VERSION ""

NS_ :

BS_:

BU_: TM

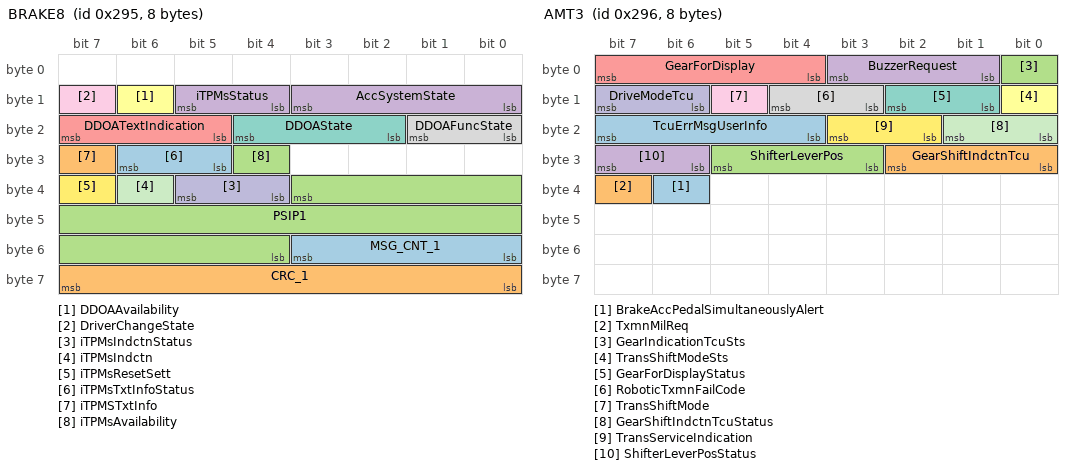
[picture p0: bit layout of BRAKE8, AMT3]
BO_ 661 BRAKE8: 8 Vector__XXX
 SG_ MSG_CNT_1 : 51|4@0+ (1,0) [0|15] ""  TM
 SG_ CRC_1 : 63|8@0+ (1,0) [0|255] ""  TM
 SG_ PSIP1 : 35|16@0+ (0.005,-163.84) [-163.84|163.835] "Deg/Sec"  TM
 SG_ AccSystemState : 11|4@0+ (1,0) [0|15] ""  TM
 SG_ DDOATextIndication : 23|3@0+ (1,0) [0|7] ""  TM
 SG_ DDOAAvailability : 14|1@0+ (1,0) [0|1] ""  TM
 SG_ DDOAState : 20|3@0+ (1,0) [0|7] ""  TM
 SG_ DDOAFuncState : 17|2@0+ (1,0) [0|3] ""  TM
 SG_ DriverChangeState : 15|1@0+ (1,0) [0|1] ""  TM
 SG_ iTPMsIndctnStatus : 37|2@0+ (1,0) [0|3] ""  TM
 SG_ iTPMsIndctn : 38|1@0+ (1,0) [0|1] ""  TM
 SG_ iTPMsResetSett : 39|1@0+ (1,0) [0|1] ""  TM
 SG_ iTPMsTxtInfoStatus : 30|2@0+ (1,0) [0|3] ""  TM
 SG_ iTPMSTxtInfo : 31|1@0+ (1,0) [0|1] ""  TM
 SG_ iTPMsAvailability : 28|1@0+ (1,0) [0|1] ""  TM
 SG_ iTPMsStatus : 13|2@0+ (1,0) [0|3] ""  TM

BO_ 662 AMT3: 8 Vector__XXX
 SG_ BrakeAccPedalSimultaneouslyAlert : 38|1@0+ (1,0) [0|1] ""  TM
 SG_ TxmnMilReq : 39|1@0+ (1,0) [0|1] ""  TM
 SG_ GearIndicationTcuSts : 0|1@0+ (1,0) [0|1] ""  TM
 SG_ BuzzerRequest : 3|3@0+ (1,0) [0|7] ""  TM
 SG_ GearForDisplay : 7|4@0+ (1,0) [0|15] ""  TM
 SG_ TransShiftModeSts : 8|1@0+ (1,0) [0|1] ""  TM
 SG_ GearForDisplayStatus : 10|2@0+ (1,0) [0|3] ""  TM
 SG_ RoboticTxmnFailCode : 12|2@0+ (1,0) [0|3] ""  TM
 SG_ TransShiftMode : 13|1@0+ (1,0) [0|1] ""  TM
 SG_ DriveModeTcu : 15|2@0+ (1,0) [0|3] ""  TM
 SG_ GearShiftIndctnTcuStatus : 17|2@0+ (1,0) [0|3] ""  TM
 SG_ TransServiceIndication : 19|2@0+ (1,0) [0|3] ""  TM
 SG_ TcuErrMsgUserInfo : 23|4@0+ (1,0) [0|15] ""  TM
 SG_ GearShiftIndctnTcu : 26|3@0+ (1,0) [0|7] ""  TM
 SG_ ShifterLeverPos : 29|3@0+ (1,0) [0|7] ""  TM
 SG_ ShifterLeverPosStatus : 31|2@0+ (1,0) [0|3] ""  TM

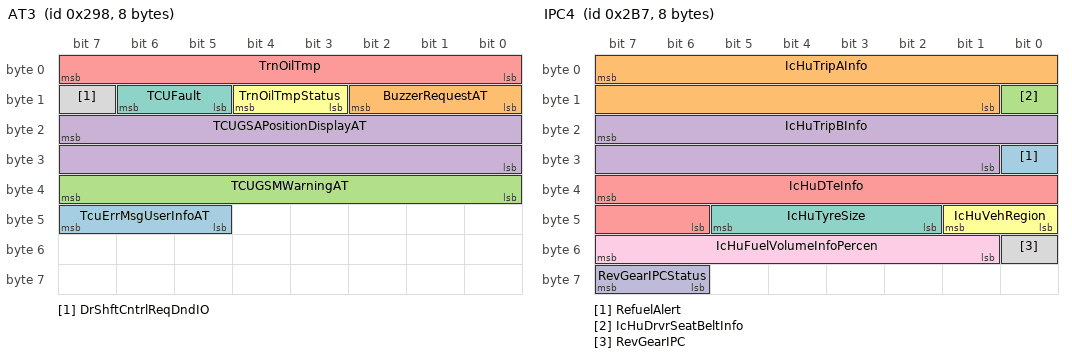
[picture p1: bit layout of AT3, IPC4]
BO_ 664 AT3: 8 Vector__XXX
 SG_ TcuErrMsgUserInfoAT : 47|3@0+ (1,0) [0|7] ""  TM
 SG_ BuzzerRequestAT : 10|3@0+ (1,0) [0|7] ""  TM
 SG_ TCUGSMWarningAT : 39|8@0+ (1,0) [0|255] ""  TM
 SG_ TCUGSAPositionDisplayAT : 23|16@0+ (1,0) [0|65535] ""  TM
 SG_ TrnOilTmp : 7|8@0+ (1,-40) [-40|215] "deg C"  TM
 SG_ TrnOilTmpStatus : 12|2@0+ (1,0) [0|3] ""  TM
 SG_ TCUFault : 14|2@0+ (1,0) [0|3] ""  TM
 SG_ DrShftCntrlReqDndIO : 15|1@0+ (1,0) [0|1] ""  TM

BO_ 666 DCT3: 8 Vector__XXX
 SG_ TCUGSMWarningDct : 63|8@0+ (1,0) [0|255] ""  TM
 SG_ TCUGSAPositionDisplayDct : 47|16@0+ (1,0) [0|65535] ""  TM
 SG_ TcuErrMsgUserInfoDCT : 5|3@0+ (1,0) [0|7] ""  TM
 SG_ DrShftCntrlReqDndIODCT : 26|1@0+ (1,0) [0|1] ""  TM
 SG_ TxmnOilSumpTempStatus : 25|2@0+ (1,0) [0|3] ""  TM
 SG_ TxmnOilSumpTemp : 39|8@0+ (1,-40) [-40|215] "DegC"  TM
 SG_ BuzzerRequestDct : 2|3@0+ (1,0) [0|7] ""  TM
 SG_ TransServiceIndicationDCT : 7|2@0+ (1,0) [0|3] ""  TM
 SG_ CoolingFanStateReq : 8|1@0+ (1,0) [0|1] ""  TM
 SG_ ACCmprsrStateReq : 10|2@0+ (1,0) [0|3] ""  TM
 SG_ GearShiftIndctnTcuDct : 13|3@0+ (1,0) [0|7] ""  TM
 SG_ GearShiftIndctnTcuDctStatus : 15|2@0+ (1,0) [0|3] ""  TM
 SG_ TxmnOverheated : 16|1@0+ (1,0) [0|1] ""  TM
 SG_ InhibitStopStrt : 17|1@0+ (1,0) [0|1] ""  TM
 SG_ GearForDisplayDctStatus : 19|2@0+ (1,0) [0|3] ""  TM
 SG_ GearForDisplayDct : 23|4@0+ (1,0) [0|15] ""  TM
 SG_ BrkPedalPressReq : 27|1@0+ (1,0) [0|1] ""  TM
 SG_ TxmnMilReq : 28|1@0+ (1,0) [0|1] ""  TM
 SG_ EngShutAuth : 29|1@0+ (1,0) [0|1] ""  TM
 SG_ EngStopReqESS : 30|1@0+ (1,0) [0|1] ""  TM
 SG_ EngRestrtReq : 31|1@0+ (1,0) [0|1] ""  TM

BO_ 693 IPC2: 8 Vector__XXX
 SG_ iTPMsResetStatus : 57|2@0+ (1,0) [0|3] ""  TM
 SG_ iTPMsReset : 29|1@0+ (1,0) [0|1] ""  TM
 SG_ HvBattSoCColor : 51|3@0+ (1,0) [0|7] ""  TM
 SG_ OATICSig : 7|8@0+ (0.5,-40) [-40|85] "degC"  TM
 SG_ BattVoltIPC : 15|8@0+ (0.1,0) [0|25.4] "Volts"  TM
 SG_ LowFuelOutputICStatus : 17|2@0+ (1,0) [0|3] ""  TM
 SG_ LowFuelOutputIC : 18|1@0+ (1,0) [0|1] ""  TM
 SG_ ParkBrkState : 19|1@0+ (1,0) [0|1] ""  TM
 SG_ IcPlatformVariant : 23|4@0+ (1,0) [0|15] ""  TM
 SG_ OATICSigStatus : 25|2@0+ (1,0) [0|3] ""  TM
 SG_ IcPresence : 26|1@0+ (1,0) [0|1] ""  TM
 SG_ SRSWarningLampStatus : 27|1@0+ (1,0) [0|1] ""  TM
 SG_ VsSPulseCountSigStatus : 31|2@0+ (1,0) [0|3] ""  TM
 SG_ VsSPulseCountSig : 39|8@0+ (1,0) [0|255] "Pulse"  TM
 SG_ IcHuVoiceAlertState : 47|8@0+ (1,0) [0|255] ""  TM
 SG_ IcHuVoiceAlertStateStatus : 48|1@0+ (1,0) [0|1] ""  TM
 SG_ ICCurDriveModeSig : 55|4@0+ (1,0) [0|15] ""  TM
 SG_ IcHuCarImageSelection : 61|4@0+ (1,0) [0|15] ""  TM
 SG_ IcSbDispReq : 62|1@0+ (1,0) [0|1] ""  TM
 SG_ IcSbrDrvrSeatBeltSwitchStatus : 63|1@0+ (1,0) [0|1] ""  TM

BO_ 695 IPC4: 8 Vector__XXX
 SG_ RefuelAlert : 24|1@0+ (1,0) [0|1] ""  TM
 SG_ IcHuTripAInfo : 7|15@0+ (0.1,0) [0|1999] "Km"  TM
 SG_ IcHuDrvrSeatBeltInfo : 8|1@0+ (1,0) [0|1] ""  TM
 SG_ IcHuTripBInfo : 23|15@0+ (0.1,0) [0|1999] "Km"  TM
 SG_ IcHuDTeInfo : 39|10@0+ (1,0) [0|999] ""  TM
 SG_ IcHuVehRegion : 41|2@0+ (1,0) [0|3] ""  TM
 SG_ IcHuTyreSize : 45|4@0+ (1,0) [0|15] ""  TM
 SG_ RevGearIPC : 48|1@0+ (1,0) [0|1] ""  TM
 SG_ IcHuFuelVolumeInfoPercen : 55|7@0+ (1,0) [0|100] "%"  TM
 SG_ RevGearIPCStatus : 63|2@0+ (1,0) [0|3] ""  TM

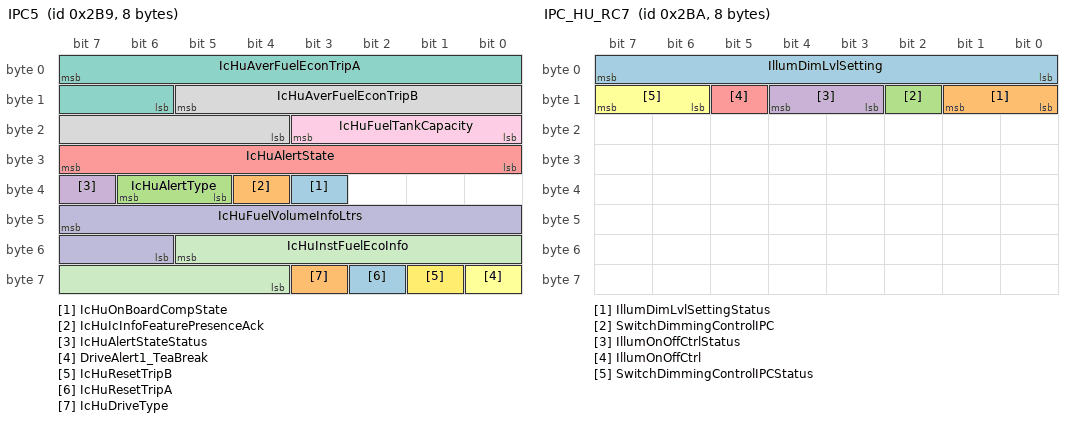
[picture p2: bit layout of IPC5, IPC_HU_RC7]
BO_ 697 IPC5: 8 Vector__XXX
 SG_ IcHuOnBoardCompState : 35|1@0+ (1,0) [0|1] ""  TM
 SG_ IcHuIcInfoFeaturePresenceAck : 36|1@0+ (1,0) [0|1] ""  TM
 SG_ IcHuAlertType : 38|2@0+ (1,0) [0|3] ""  TM
 SG_ IcHuAlertStateStatus : 39|1@0+ (1,0) [0|1] ""  TM
 SG_ IcHuAlertState : 31|8@0+ (1,0) [0|127] ""  TM
 SG_ DriveAlert1_TeaBreak : 56|1@0+ (1,0) [0|1] ""  TM
 SG_ IcHuAverFuelEconTripA : 7|10@0+ (0.1,0) [0|99.9] "Km/Ltr"  TM
 SG_ IcHuAverFuelEconTripB : 13|10@0+ (0.1,0) [0|99.9] "Km/Ltr"  TM
 SG_ IcHuFuelTankCapacity : 19|4@0+ (1,0) [0|15] ""  TM
 SG_ IcHuFuelVolumeInfoLtrs : 47|10@0+ (0.1,0) [0|65] "Ltr"  TM
 SG_ IcHuInstFuelEcoInfo : 53|10@0+ (0.1,0) [0|99.9] "Km/Ltr"  TM
 SG_ IcHuResetTripB : 57|1@0+ (1,0) [0|1] ""  TM
 SG_ IcHuResetTripA : 58|1@0+ (1,0) [0|1] ""  TM
 SG_ IcHuDriveType : 59|1@0+ (1,0) [0|1] ""  TM

BO_ 698 IPC_HU_RC7: 8 Vector__XXX
 SG_ IllumDimLvlSetting : 7|8@0+ (1,0) [0|100] "%"  TM
 SG_ IllumDimLvlSettingStatus : 9|2@0+ (1,0) [0|3] ""  TM
 SG_ SwitchDimmingControlIPC : 10|1@0+ (1,0) [0|1] ""  TM
 SG_ IllumOnOffCtrlStatus : 12|2@0+ (1,0) [0|3] ""  TM
 SG_ IllumOnOffCtrl : 13|1@0+ (1,0) [0|1] ""  TM
 SG_ SwitchDimmingControlIPCStatus : 15|2@0+ (1,0) [0|3] ""  TM

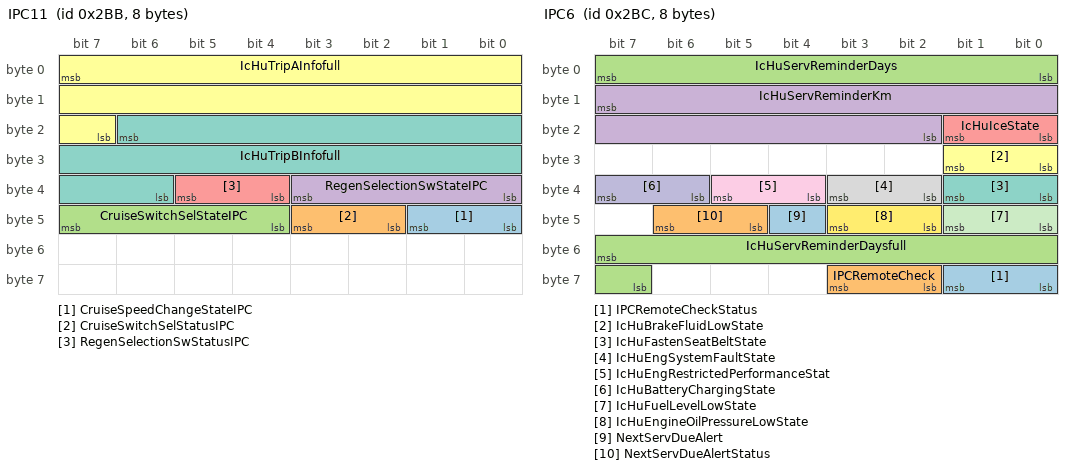
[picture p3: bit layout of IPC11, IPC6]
BO_ 699 IPC11: 8 Vector__XXX
 SG_ CruiseSpeedChangeStateIPC : 41|2@0+ (1,0) [0|3] ""  TM
 SG_ CruiseSwitchSelStatusIPC : 43|2@0+ (1,0) [0|3] ""  TM
 SG_ CruiseSwitchSelStateIPC : 47|4@0+ (1,0) [0|15] ""  TM
 SG_ RegenSelectionSwStateIPC : 35|4@0+ (1,0) [0|15] ""  TM
 SG_ RegenSelectionSwStatusIPC : 37|2@0+ (1,0) [0|3] ""  TM
 SG_ IcHuTripAInfofull : 7|17@0+ (0.1,0) [0|9999.9] "Km"  TM
 SG_ IcHuTripBInfofull : 22|17@0+ (0.1,0) [0|9999.9] "Km"  TM

BO_ 700 IPC6: 8 Vector__XXX
 SG_ IPCRemoteCheckStatus : 57|2@0+ (1,0) [0|3] ""  TM
 SG_ IPCRemoteCheck : 59|2@0+ (1,0) [0|3] ""  TM
 SG_ IcHuServReminderDays : 7|8@0+ (1,0) [0|255] "Day"  TM
 SG_ IcHuServReminderKm : 15|14@0+ (1,0) [0|16383] "Km"  TM
 SG_ IcHuIceState : 17|2@0+ (1,0) [0|3] ""  TM
 SG_ IcHuBrakeFluidLowState : 25|2@0+ (1,0) [0|3] ""  TM
 SG_ IcHuFastenSeatBeltState : 33|2@0+ (1,0) [0|3] ""  TM
 SG_ IcHuEngSystemFaultState : 35|2@0+ (1,0) [0|3] ""  TM
 SG_ IcHuEngRestrictedPerformanceStat : 37|2@0+ (1,0) [0|3] ""  TM
 SG_ IcHuBatteryChargingState : 39|2@0+ (1,0) [0|3] ""  TM
 SG_ IcHuFuelLevelLowState : 41|2@0+ (1,0) [0|3] ""  TM
 SG_ IcHuEngineOilPressureLowState : 43|2@0+ (1,0) [0|3] ""  TM
 SG_ NextServDueAlert : 44|1@0+ (1,0) [0|1] ""  TM
 SG_ NextServDueAlertStatus : 46|2@0+ (1,0) [0|3] ""  TM
 SG_ IcHuServReminderDaysfull : 55|9@0+ (1,0) [0|511] "Day"  TM

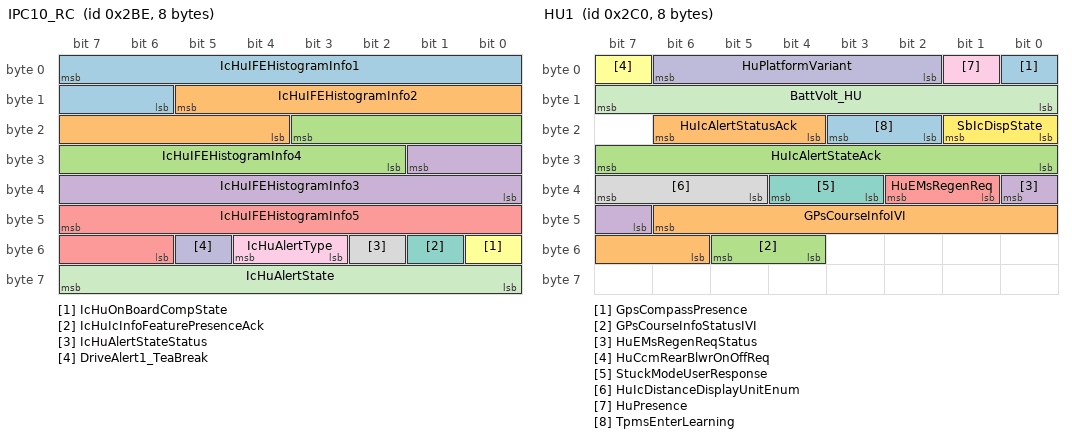
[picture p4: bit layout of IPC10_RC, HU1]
BO_ 702 IPC10_RC: 8 Vector__XXX
 SG_ IcHuIFEHistogramInfo1 : 7|10@0+ (0.1,0) [0|99.9] "Km/Ltr"  TM
 SG_ IcHuIFEHistogramInfo2 : 13|10@0+ (0.1,0) [0|99.9] "km/Ltr"  TM
 SG_ IcHuIFEHistogramInfo4 : 19|10@0+ (0.1,0) [0|99.9] "Km/Ltr"  TM
 SG_ IcHuIFEHistogramInfo3 : 25|10@0+ (0.1,0) [0|99.9] "Km/Ltr"  TM
 SG_ IcHuIFEHistogramInfo5 : 47|10@0+ (0.1,0) [0|99.9] "Km/Ltr"  TM
 SG_ IcHuOnBoardCompState : 48|1@0+ (1,0) [0|1] ""  TM
 SG_ IcHuIcInfoFeaturePresenceAck : 49|1@0+ (1,0) [0|1] ""  TM
 SG_ IcHuAlertStateStatus : 50|1@0+ (1,0) [0|1] ""  TM
 SG_ IcHuAlertType : 52|2@0+ (1,0) [0|3] ""  TM
 SG_ DriveAlert1_TeaBreak : 53|1@0+ (1,0) [0|1] ""  TM
 SG_ IcHuAlertState : 63|8@0+ (1,0) [0|127] ""  TM

BO_ 704 HU1: 8 Vector__XXX
 SG_ GpsCompassPresence : 0|1@0+ (1,0) [0|1] ""  TM
 SG_ GPsCourseInfoIVI : 46|9@0+ (1,0) [0|360] ""  TM
 SG_ GPsCourseInfoStatusIVI : 53|2@0+ (1,0) [0|3] ""  TM
 SG_ HuEMsRegenReqStatus : 32|2@0+ (1,0) [0|3] ""  TM
 SG_ HuEMsRegenReq : 34|2@0+ (1,0) [0|3] ""  TM
 SG_ HuCcmRearBlwrOnOffReq : 7|1@0+ (1,0) [0|1] ""  TM
 SG_ StuckModeUserResponse : 36|2@0+ (1,0) [0|3] ""  TM
 SG_ HuIcDistanceDisplayUnitEnum : 39|3@0+ (1,0) [0|7] ""  TM
 SG_ HuPresence : 1|1@0+ (1,0) [0|1] ""  TM
 SG_ HuPlatformVariant : 6|5@0+ (1,0) [0|31] ""  TM
 SG_ BattVolt_HU : 15|8@0+ (0.1,0) [0|25] "Volts"  TM
 SG_ SbIcDispState : 17|2@0+ (1,0) [0|3] ""  TM
 SG_ TpmsEnterLearning : 19|2@0+ (1,0) [0|3] ""  TM
 SG_ HuIcAlertStatusAck : 22|3@0+ (1,0) [0|7] ""  TM
 SG_ HuIcAlertStateAck : 31|8@0+ (1,0) [0|127] ""  TM

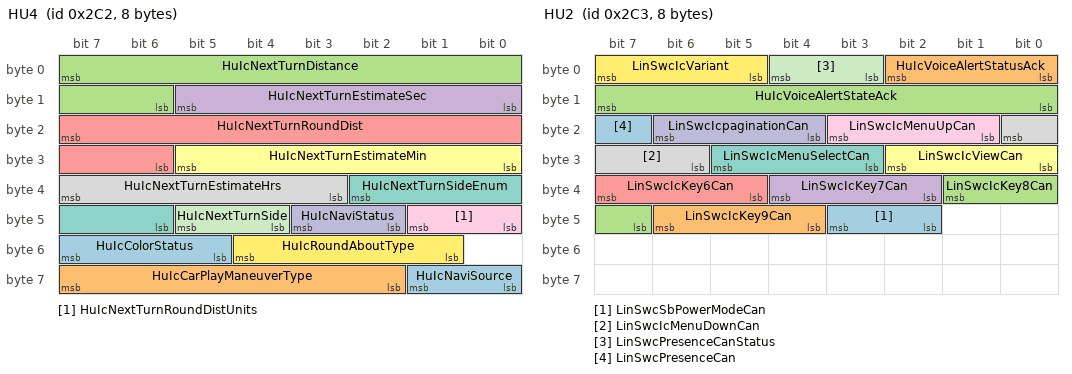
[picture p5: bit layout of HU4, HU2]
BO_ 706 HU4: 8 Vector__XXX
 SG_ HuIcNaviSource : 57|2@0+ (1,0) [0|3] ""  TM
 SG_ HuIcCarPlayManeuverType : 63|6@0+ (1,0) [0|63] ""  TM
 SG_ HuIcNextTurnDistance : 7|10@0+ (1,0) [0|1023] "m"  TM
 SG_ HuIcNextTurnEstimateSec : 13|6@0+ (1,0) [0|59] "sec"  TM
 SG_ HuIcNextTurnRoundDist : 23|10@0+ (1,0) [0|1023] "m"  TM
 SG_ HuIcNextTurnEstimateMin : 29|6@0+ (1,0) [0|59] "min"  TM
 SG_ HuIcNextTurnSideEnum : 34|5@0+ (1,0) [0|31] ""  TM
 SG_ HuIcNextTurnEstimateHrs : 39|5@0+ (1,0) [0|23] "hr"  TM
 SG_ HuIcNextTurnRoundDistUnits : 41|2@0+ (1,0) [0|3] ""  TM
 SG_ HuIcNaviStatus : 43|2@0+ (1,0) [0|3] ""  TM
 SG_ HuIcNextTurnSide : 45|2@0+ (1,0) [0|3] ""  TM
 SG_ HuIcRoundAboutType : 52|4@0+ (1,0) [0|15] ""  TM
 SG_ HuIcColorStatus : 55|3@0+ (1,0) [0|7] ""  TM

BO_ 707 HU2: 8 Vector__XXX
 SG_ LinSwcSbPowerModeCan : 43|2@0+ (1,0) [0|3] ""  TM
 SG_ LinSwcIcKey9Can : 46|3@0+ (1,0) [0|7] ""  TM
 SG_ LinSwcIcKey8Can : 33|3@0+ (1,0) [0|7] ""  TM
 SG_ LinSwcIcKey7Can : 36|3@0+ (1,0) [0|7] ""  TM
 SG_ LinSwcIcKey6Can : 39|3@0+ (1,0) [0|7] ""  TM
 SG_ LinSwcIcViewCan : 26|3@0+ (1,0) [0|7] ""  TM
 SG_ LinSwcIcMenuSelectCan : 29|3@0+ (1,0) [0|7] ""  TM
 SG_ LinSwcIcMenuDownCan : 16|3@0+ (1,0) [0|7] ""  TM
 SG_ LinSwcIcMenuUpCan : 19|3@0+ (1,0) [0|7] ""  TM
 SG_ LinSwcIcpaginationCan : 22|3@0+ (1,0) [0|7] ""  TM
 SG_ LinSwcPresenceCanStatus : 4|2@0+ (1,0) [0|3] ""  TM
 SG_ LinSwcIcVariant : 7|3@0+ (1,0) [0|7] ""  TM
 SG_ LinSwcPresenceCan : 23|1@0+ (1,0) [0|1] ""  TM
 SG_ HuIcVoiceAlertStatusAck : 2|3@0+ (1,0) [0|7] ""  TM
 SG_ HuIcVoiceAlertStateAck : 15|8@0+ (1,0) [0|255] ""  TM

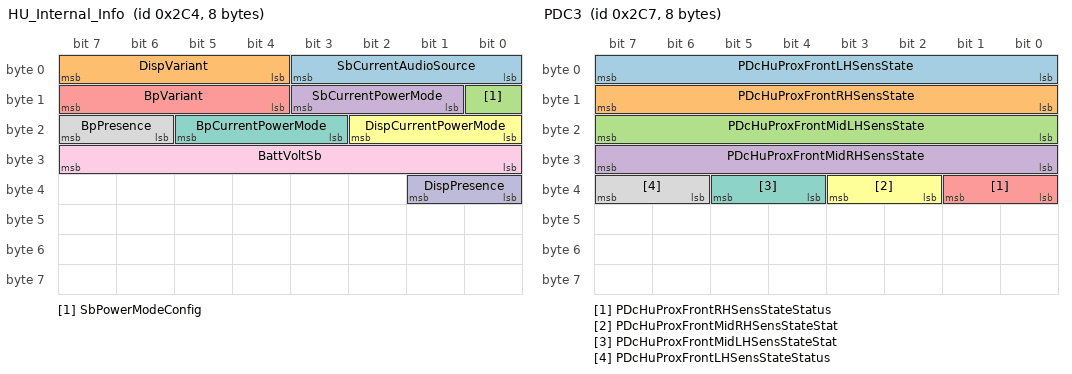
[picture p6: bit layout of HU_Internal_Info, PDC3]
BO_ 708 HU_Internal_Info: 8 Vector__XXX
 SG_ SbCurrentAudioSource : 3|4@0+ (1,0) [0|15] ""  TM
 SG_ DispVariant : 7|4@0+ (1,0) [0|15] ""  TM
 SG_ SbPowerModeConfig : 8|1@0+ (1,0) [0|1] ""  TM
 SG_ SbCurrentPowerMode : 11|3@0+ (1,0) [0|7] ""  TM
 SG_ BpVariant : 15|4@0+ (1,0) [0|15] ""  TM
 SG_ DispCurrentPowerMode : 18|3@0+ (1,0) [0|7] ""  TM
 SG_ BpCurrentPowerMode : 21|3@0+ (1,0) [0|7] ""  TM
 SG_ BpPresence : 23|2@0+ (1,0) [0|3] ""  TM
 SG_ BattVoltSb : 31|8@0+ (0.1,0) [0|25.4] "V"  TM
 SG_ DispPresence : 33|2@0+ (1,0) [0|3] ""  TM

BO_ 710 PDC1: 8 Vector__XXX
 SG_ PDcHuFaultState : 4|5@0+ (1,0) [0|31] ""  TM
 SG_ PDcHuAudioZoneState : 7|3@0+ (1,0) [0|7] ""  TM
 SG_ PDcHuVisualZoneRearLHSensState : 11|4@0+ (1,0) [0|15] ""  TM
 SG_ PDcHuVisualZoneRearMidRHSensStat : 15|4@0+ (1,0) [0|15] ""  TM
 SG_ PDcHuVisualZoneRearRHSensState : 19|4@0+ (1,0) [0|15] ""  TM
 SG_ PDcHuVisualZoneRearMidLHSensStat : 23|4@0+ (1,0) [0|15] ""  TM
 SG_ PDcPresence : 24|1@0+ (1,0) [0|1] ""  TM
 SG_ PDcHuState : 25|1@0+ (1,0) [0|1] ""  TM
 SG_ PDcHuPwrModeState : 29|4@0+ (1,0) [0|15] ""  TM
 SG_ PDcVariant : 31|2@0+ (1,0) [0|3] ""  TM
 SG_ PDcHuVisualZoneFrontLHSensState : 35|4@0+ (1,0) [0|15] ""  TM
 SG_ PDcHuVisualZoneFrontMidLHSensSta : 39|4@0+ (1,0) [0|15] ""  TM
 SG_ PDcHuVisualZoneFrontMidRHSensSta : 43|4@0+ (1,0) [0|15] ""  TM
 SG_ PDcHuVisualZoneFrontRHSensState : 47|4@0+ (1,0) [0|15] ""  TM
 SG_ PDcHuFrontAudioZoneState : 50|3@0+ (1,0) [0|7] ""  TM
 SG_ PDcHuFrontFaultState : 55|5@0+ (1,0) [0|31] ""  TM
 SG_ PDcHuFrontState : 56|1@0+ (1,0) [0|1] ""  TM
 SG_ PDcIPcFrontActive : 59|1@0+ (1,0) [0|1] ""  TM
 SG_ PDcIPcRearActive : 60|1@0+ (1,0) [0|1] ""  TM

BO_ 711 PDC3: 8 Vector__XXX
 SG_ PDcHuProxFrontLHSensState : 7|8@0+ (1,0) [0|255] "cms"  TM
 SG_ PDcHuProxFrontRHSensState : 15|8@0+ (1,0) [0|255] "cms"  TM
 SG_ PDcHuProxFrontMidLHSensState : 23|8@0+ (1,0) [0|255] "cms"  TM
 SG_ PDcHuProxFrontMidRHSensState : 31|8@0+ (1,0) [0|255] "cm"  TM
 SG_ PDcHuProxFrontRHSensStateStatus : 33|2@0+ (1,0) [0|3] ""  TM
 SG_ PDcHuProxFrontMidRHSensStateStat : 35|2@0+ (1,0) [0|3] ""  TM
 SG_ PDcHuProxFrontMidLHSensStateStat : 37|2@0+ (1,0) [0|3] ""  TM
 SG_ PDcHuProxFrontLHSensStateStatus : 39|2@0+ (1,0) [0|3] ""  TM

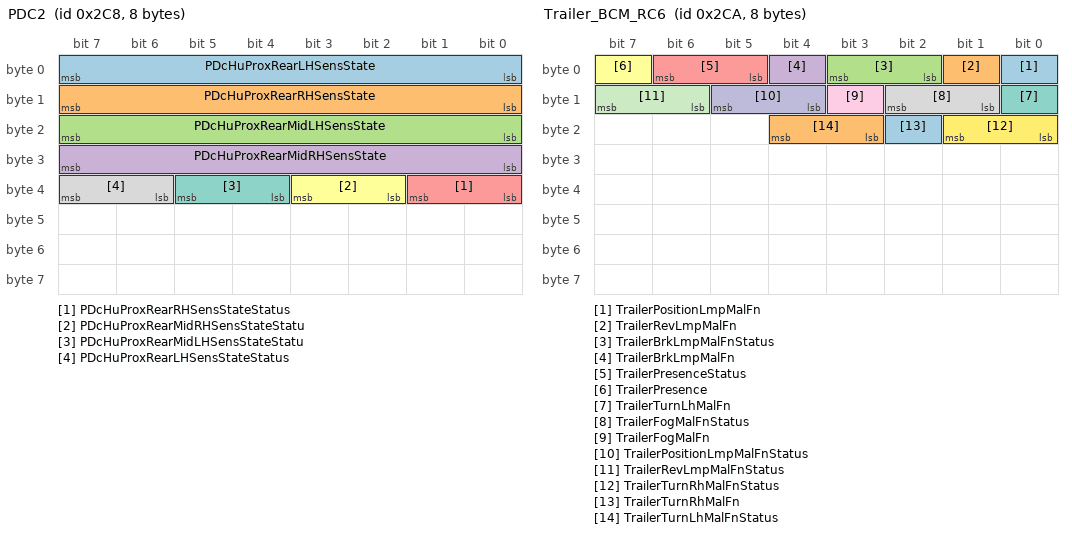
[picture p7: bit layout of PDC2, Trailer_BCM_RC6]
BO_ 712 PDC2: 8 Vector__XXX
 SG_ PDcHuProxRearLHSensState : 7|8@0+ (1,0) [0|255] "cms"  TM
 SG_ PDcHuProxRearRHSensState : 15|8@0+ (1,0) [0|255] "cms"  TM
 SG_ PDcHuProxRearMidLHSensState : 23|8@0+ (1,0) [0|255] "cms"  TM
 SG_ PDcHuProxRearMidRHSensState : 31|8@0+ (1,0) [0|255] "cm"  TM
 SG_ PDcHuProxRearRHSensStateStatus : 33|2@0+ (1,0) [0|3] ""  TM
 SG_ PDcHuProxRearMidRHSensStateStatu : 35|2@0+ (1,0) [0|3] ""  TM
 SG_ PDcHuProxRearMidLHSensStateStatu : 37|2@0+ (1,0) [0|3] ""  TM
 SG_ PDcHuProxRearLHSensStateStatus : 39|2@0+ (1,0) [0|3] ""  TM

BO_ 713 HU5: 8 Vector__XXX
 SG_ HuIcMediaState : 59|4@0+ (1,0) [0|15] ""  TM
 SG_ HuIcSource : 48|5@0+ (1,0) [0|31] ""  TM
 SG_ HuIcAudioVolumeStatus : 12|5@0+ (1,0) [0|31] ""  TM
 SG_ HuIcBTStatus : 15|3@0+ (1,0) [0|7] ""  TM
 SG_ HuIcPlabackCallDurationSec : 21|6@0+ (1,0) [0|59] "sec."  TM
 SG_ HuIcRepeatOneState : 22|1@0+ (1,0) [0|1] ""  TM
 SG_ HuIcMuteStatus : 23|1@0+ (1,0) [0|1] ""  TM
 SG_ HuIcPlabackCallDurationMin : 29|6@0+ (1,0) [0|59] "min"  TM
 SG_ HuIcSMSReceiveState : 30|1@0+ (1,0) [0|1] ""  TM
 SG_ HuIcRepeatState : 31|1@0+ (1,0) [0|1] ""  TM
 SG_ HuIcPlabackCallDurationHrs : 36|5@0+ (1,0) [0|23] "hr"  TM
 SG_ HuIcPhoneCallStatus : 39|3@0+ (1,0) [0|7] ""  TM
 SG_ HuIcPlaybackElapsedTimeHrs : 44|5@0+ (1,0) [0|23] "hr"  TM
 SG_ HuIcNetworkSignalStatus : 47|3@0+ (1,0) [0|7] ""  TM
 SG_ HuIcPlaybackElapsedTimeMin : 55|6@0+ (1,0) [0|59] "min"  TM
 SG_ HuIcInfoFeaturePresence : 0|1@0+ (1,0) [0|1] ""  TM
 SG_ HuIcShuffleState : 1|1@0+ (1,0) [0|1] ""  TM
 SG_ HuIcPlaybackElapsedTimeSec : 7|6@0+ (1,0) [0|59] "sec"  TM

BO_ 714 Trailer_BCM_RC6: 8 Vector__XXX
 SG_ TrailerPositionLmpMalFn : 0|1@0+ (1,0) [0|1] ""  TM
 SG_ TrailerRevLmpMalFn : 1|1@0+ (1,0) [0|1] ""  TM
 SG_ TrailerBrkLmpMalFnStatus : 3|2@0+ (1,0) [0|3] ""  TM
 SG_ TrailerBrkLmpMalFn : 4|1@0+ (1,0) [0|1] ""  TM
 SG_ TrailerPresenceStatus : 6|2@0+ (1,0) [0|3] ""  TM
 SG_ TrailerPresence : 7|1@0+ (1,0) [0|1] ""  TM
 SG_ TrailerTurnLhMalFn : 8|1@0+ (1,0) [0|1] ""  TM
 SG_ TrailerFogMalFnStatus : 10|2@0+ (1,0) [0|3] ""  TM
 SG_ TrailerFogMalFn : 11|1@0+ (1,0) [0|1] ""  TM
 SG_ TrailerPositionLmpMalFnStatus : 13|2@0+ (1,0) [0|3] ""  TM
 SG_ TrailerRevLmpMalFnStatus : 15|2@0+ (1,0) [0|3] ""  TM
 SG_ TrailerTurnRhMalFnStatus : 17|2@0+ (1,0) [0|3] ""  TM
 SG_ TrailerTurnRhMalFn : 18|1@0+ (1,0) [0|1] ""  TM
 SG_ TrailerTurnLhMalFnStatus : 20|2@0+ (1,0) [0|3] ""  TM

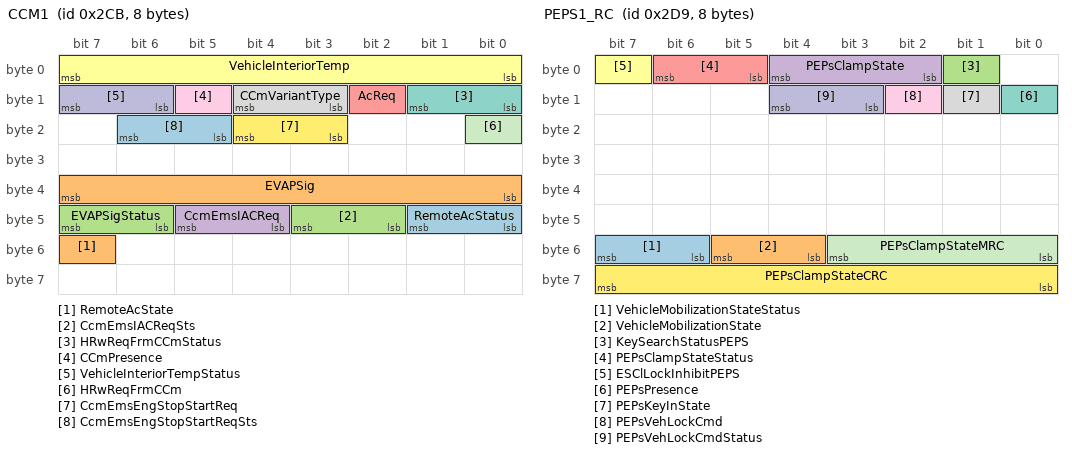
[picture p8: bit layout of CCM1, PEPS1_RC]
BO_ 715 CCM1: 8 Vector__XXX
 SG_ RemoteAcStatus : 41|2@0+ (1,0) [0|3] ""  TM
 SG_ RemoteAcState : 55|1@0+ (1,0) [0|1] ""  TM
 SG_ CcmEmsIACReqSts : 43|2@0+ (1,0) [0|3] ""  TM
 SG_ CcmEmsIACReq : 45|2@0+ (1,0) [0|3] ""  TM
 SG_ AcReq : 10|1@0+ (1,0) [0|1] ""  TM
 SG_ VehicleInteriorTemp : 7|8@0+ (0.5,-40) [-40|85] "Deg"  TM
 SG_ HRwReqFrmCCmStatus : 9|2@0+ (1,0) [0|3] ""  TM
 SG_ CCmVariantType : 12|2@0+ (1,0) [0|3] ""  TM
 SG_ CCmPresence : 13|1@0+ (1,0) [0|1] ""  TM
 SG_ VehicleInteriorTempStatus : 15|2@0+ (1,0) [0|3] ""  TM
 SG_ HRwReqFrmCCm : 16|1@0+ (1,0) [0|1] ""  TM
 SG_ CcmEmsEngStopStartReq : 20|2@0+ (1,0) [0|3] ""  TM
 SG_ CcmEmsEngStopStartReqSts : 22|2@0+ (1,0) [0|3] ""  TM
 SG_ EVAPSig : 39|8@0+ (0.5,-40) [-40|85] "DegC"  TM
 SG_ EVAPSigStatus : 47|2@0+ (1,0) [0|3] ""  TM

BO_ 720 BCM1: 8 Vector__XXX
 SG_ RearWasherStateStatus : 63|2@0+ (1,0) [0|3] ""  TM
 SG_ RearWasherState : 61|2@0+ (1,0) [0|3] ""  TM
 SG_ FrontWasherStateStatus : 59|2@0+ (1,0) [0|3] ""  TM
 SG_ FrontWasherState : 57|2@0+ (1,0) [0|3] ""  TM
 SG_ AutoWipeStateStatus : 35|2@0+ (1,0) [0|3] ""  TM
 SG_ AutoWipeState : 33|2@0+ (1,0) [0|3] ""  TM
 SG_ PositionLmpTelltale : 25|1@0+ (1,0) [0|1] ""  TM
 SG_ PositionLmpTelltaleStatus : 39|2@0+ (1,0) [0|3] ""  TM
 SG_ BattVolt_BCM : 7|8@0+ (0.1,0) [0|25] "Volts"  TM
 SG_ BCMVariant : 10|3@0+ (1,0) [0|7] ""  TM
 SG_ BCMPresence : 11|1@0+ (1,0) [0|1] ""  TM
 SG_ RevGearStatus : 13|2@0+ (1,0) [0|3] ""  TM
 SG_ RevGear : 14|1@0+ (1,0) [0|1] ""  TM
 SG_ RevLmpON : 15|1@0+ (1,0) [0|1] ""  TM
 SG_ RevLmpONStatus : 17|2@0+ (1,0) [0|3] ""  TM
 SG_ RearFogLmpON : 18|1@0+ (1,0) [0|1] ""  TM
 SG_ RearFogLmpONStatus : 20|2@0+ (1,0) [0|3] ""  TM
 SG_ TurnLHTelltaleStatus : 22|2@0+ (1,0) [0|3] ""  TM
 SG_ TurnLHTelltale : 23|1@0+ (1,0) [0|1] ""  TM
 SG_ TurnRHTelltaleStatus : 27|2@0+ (1,0) [0|3] ""  TM
 SG_ TurnRHTelltale : 28|1@0+ (1,0) [0|1] ""  TM
 SG_ LightSensActiveStatus : 30|2@0+ (1,0) [0|3] ""  TM
 SG_ LightSensActive : 31|1@0+ (1,0) [0|1] ""  TM
 SG_ RVcPresence : 37|2@0+ (1,0) [0|3] ""  TM
 SG_ BcmCcmSolarInputLh : 47|8@0+ (5,0) [0|1200] "W/m^2"  TM
 SG_ BcmCcmSolarInputRh : 55|8@0+ (5,0) [0|1200] "W/m^2"  TM

BO_ 722 BCM_HUICTrailer_RC1: 8 Vector__XXX
 SG_ PowerModeStateStatus : 1|2@0+ (1,0) [0|3] ""  TM
 SG_ PowerModeState : 5|4@0+ (1,0) [0|15] ""  TM
 SG_ PositionLmpTelltaleStatus : 7|2@0+ (1,0) [0|3] ""  TM
 SG_ PositionLmpTelltale : 8|1@0+ (1,0) [0|1] ""  TM
 SG_ HRwFdBkFrmBCm : 9|1@0+ (1,0) [0|1] ""  TM
 SG_ HRwFdBkFrmBCmStatus : 11|2@0+ (1,0) [0|3] ""  TM
 SG_ TurnRHTelltale : 12|1@0+ (1,0) [0|1] ""  TM
 SG_ TurnLHTelltaleStatus : 14|2@0+ (1,0) [0|3] ""  TM
 SG_ TurnLHTelltale : 15|1@0+ (1,0) [0|1] ""  TM
 SG_ TurnRHTelltaleStatus : 17|2@0+ (1,0) [0|3] ""  TM
 SG_ BattSaverFnONStatus : 19|2@0+ (1,0) [0|3] ""  TM
 SG_ BattSaverFnON : 20|1@0+ (1,0) [0|1] ""  TM
 SG_ BrkLmpONStatus : 22|2@0+ (1,0) [0|3] ""  TM
 SG_ BrkLmpON : 23|1@0+ (1,0) [0|1] ""  TM
 SG_ CockpitSigECuStatus : 25|2@0+ (1,0) [0|3] ""  TM
 SG_ RearRHTurnLmpON : 26|1@0+ (1,0) [0|1] ""  TM
 SG_ RearRHTurnLmpONStatus : 28|2@0+ (1,0) [0|3] ""  TM
 SG_ RearLHTurnLmpONStatus : 30|2@0+ (1,0) [0|3] ""  TM
 SG_ RearLHTurnLmpON : 31|1@0+ (1,0) [0|1] ""  TM
 SG_ CockpitSigECu : 39|8@0+ (1,0) [0|100] "%"  TM
 SG_ VehicleLockStateStatus : 41|2@0+ (1,0) [0|3] ""  TM
 SG_ HighBeamTelltaleStatus : 43|2@0+ (1,0) [0|3] ""  TM
 SG_ HighBeamTelltale : 44|1@0+ (1,0) [0|1] ""  TM
 SG_ KeyInStateStatus : 46|2@0+ (1,0) [0|3] ""  TM
 SG_ KeyInState : 47|1@0+ (1,0) [0|1] ""  TM
 SG_ PowerModeStateMsgCnt : 51|4@0+ (1,0) [0|15] ""  TM
 SG_ VehicleLockState : 55|3@0+ (1,0) [0|7] ""  TM
 SG_ PowerModeStateCRC : 63|8@0+ (1,0) [0|255] ""  TM

BO_ 729 PEPS1_RC: 8 Vector__XXX
 SG_ VehicleMobilizationStateStatus : 55|2@0+ (1,0) [0|3] ""  TM
 SG_ VehicleMobilizationState : 53|2@0+ (1,0) [0|3] ""  TM
 SG_ KeySearchStatusPEPS : 1|1@0+ (1,0) [0|1] ""  TM
 SG_ PEPsClampState : 4|3@0+ (1,0) [0|7] ""  TM
 SG_ PEPsClampStateStatus : 6|2@0+ (1,0) [0|3] ""  TM
 SG_ ESClLockInhibitPEPS : 7|1@0+ (1,0) [0|1] ""  TM
 SG_ PEPsPresence : 8|1@0+ (1,0) [0|1] ""  TM
 SG_ PEPsKeyInState : 9|1@0+ (1,0) [0|1] ""  TM
 SG_ PEPsVehLockCmd : 10|1@0+ (1,0) [0|1] ""  TM
 SG_ PEPsVehLockCmdStatus : 12|2@0+ (1,0) [0|3] ""  TM
 SG_ PEPsClampStateMRC : 51|4@0+ (1,0) [0|15] ""  TM
 SG_ PEPsClampStateCRC : 63|8@0+ (1,0) [0|255] ""  TM

CM_ SG_ 661 MSG_CNT_1 "Messgage counter for AY & Yaw signals";
CM_ SG_ 661 CRC_1 "CRC signal for AY & Yaw signals";
CM_ SG_ 661 PSIP1 "This data indicates information regarding digital filtered Yaw rate signal.";
CM_ SG_ 661 AccSystemState "It indicates the status of AccEngaged signal";
CM_ SG_ 661 DDOATextIndication " Driver Drowsiness State for IPC Text Message ";
CM_ SG_ 661 DDOAAvailability "DDOA function availability in the vehicle";
CM_ SG_ 661 DDOAState "Signal indicates driver Drowsiness State";
CM_ SG_ 661 DDOAFuncState "Functional State of DDOA";
CM_ SG_ 661 DriverChangeState "It indicates driver change is required";
CM_ SG_ 661 iTPMsIndctnStatus "Status signal of iTPMSIndctn";
CM_ SG_ 661 iTPMsIndctn "Low/ Ok tyre pressure indication";
CM_ SG_ 661 iTPMsResetSett "iTPMS reset setting to IPC";
CM_ SG_ 661 iTPMsTxtInfoStatus "Staus signal for iTPMSTxtInfo";
CM_ SG_ 661 iTPMSTxtInfo "iTPMS text message for user information";
CM_ SG_ 661 iTPMsAvailability "status information of TPMS";
CM_ SG_ 661 iTPMsStatus "status information of TPMS";
CM_ SG_ 662 BrakeAccPedalSimultaneouslyAlert "Brake and acc pedal pressed simultaneously.";
CM_ SG_ 662 TxmnMilReq "transmission OBD related malfunction indication to the driver";
CM_ SG_ 662 GearIndicationTcuSts "In case of any problem, gear number wll blink otherwise it will be normal";
CM_ SG_ 662 BuzzerRequest "Indication for buzzer request";
CM_ SG_ 662 GearForDisplay "This is the current position of the gear shift lever";
CM_ SG_ 662 TransShiftModeSts "In case of Inadvertent GSL movement, Transmission mode willl blink otherwise it will be normal";
CM_ SG_ 662 GearForDisplayStatus "This is the current position of the gear shift lever,Status info";
CM_ SG_ 662 RoboticTxmnFailCode "In case of vehcile interface or Gear box shifting failure, corresponding fault will be set.";
CM_ SG_ 662 TransShiftMode "Indication for the gear shift program";
CM_ SG_ 662 DriveModeTcu "Indicated the mode selected for IC";
CM_ SG_ 662 GearShiftIndctnTcuStatus "Gear shift Indication staus used to indicate the gear status signal";
CM_ SG_ 662 TransServiceIndication "Indication for AMT system warning lamp";
CM_ SG_ 662 TcuErrMsgUserInfo "ErrorMessages&UserInformation  ";
CM_ SG_ 662 GearShiftIndctnTcu "Gear shift Indication used to indicate the required gear status in IC  required Gear by the driver is to Improve the drive habits of driver 








";
CM_ SG_ 662 ShifterLeverPos "Gear Shift Lever position";
CM_ SG_ 662 ShifterLeverPosStatus "Gear Shift Lever position status information";
CM_ SG_ 664 TcuErrMsgUserInfoAT "ErrorMessages&UserInformation";
CM_ SG_ 664 BuzzerRequestAT "Indication for buzzer request";
CM_ SG_ 664 TCUGSMWarningAT "Request from GSM for alerts/warnings. More then one bit to can be set in the signal. This is to request multiple messages.

This is bit-mapped signal. Please refer FD/Function net for value table";
CM_ SG_ 664 TCUGSAPositionDisplayAT "Refer FN/FD for bit-mapped signals";
CM_ SG_ 664 TrnOilTmp "Transmission Oil Temperature";
CM_ SG_ 664 TCUFault "Diagnostic failure in TCU ";
CM_ SG_ 664 DrShftCntrlReqDndIO "This signal indicates that the driver gear request cannot be allowed";
CM_ SG_ 666 TCUGSMWarningDct "Request from GSM for alerts/warnings. More then one bit to can be set in the signal. This is to request multiple messages.

This is bit-mapped signal. Please refer FD/Function net for value table";
CM_ SG_ 666 TCUGSAPositionDisplayDct "Refer FN/FD for bit-mapped signals";
CM_ SG_ 666 TcuErrMsgUserInfoDCT "ErrorMessages&UserInformation  ";
CM_ SG_ 666 DrShftCntrlReqDndIODCT "Driver Shift Control Request Denied Indication On";
CM_ SG_ 666 TxmnOilSumpTempStatus "Transmission Oil Sump Temperature Status";
CM_ SG_ 666 TxmnOilSumpTemp "Transmission Oil Sump Temperature";
CM_ SG_ 666 BuzzerRequestDct "Indication for buzzer request";
CM_ SG_ 666 TransServiceIndicationDCT "Indication for AMT system warning lamp";
CM_ SG_ 666 CoolingFanStateReq "TCU request specific cooling FAN state";
CM_ SG_ 666 ACCmprsrStateReq "TCU request specific Air conditioning request";
CM_ SG_ 666 GearShiftIndctnTcuDct "Gear shift Indication used to indicate the required gear status in IC  required Gear by the driver is to Improve the drive habits of driver 








";
CM_ SG_ 666 GearShiftIndctnTcuDctStatus "Gear shift Indication staus used to indicate the gear status signal";
CM_ SG_ 666 TxmnOverheated "transmission Overheat  indication to the driver";
CM_ SG_ 666 InhibitStopStrt "Flag inhibiting stop start function.";
CM_ SG_ 666 GearForDisplayDctStatus "status information";
CM_ SG_ 666 GearForDisplayDct "This is the actual engaged gear ";
CM_ SG_ 666 BrkPedalPressReq "Flag that indicates to the driver that brake press is required in order to authorise gear lever transition";
CM_ SG_ 666 TxmnMilReq "transmission OBD related malfunction indication to the driver";
CM_ SG_ 666 EngShutAuth "Flag authorising EMS to stop the engine , In case of Start Stop functionality";
CM_ SG_ 666 EngStopReqESS "TCU request an engine Stop request,in case of Start Stop functionality";
CM_ SG_ 666 EngRestrtReq "TCU request an engine restart for tranmission internal need,in case of Start Stop functionality";
CM_ SG_ 693 iTPMsResetStatus "Staus signal for iTPMSTxtInfo";
CM_ SG_ 693 iTPMsReset "iTPMS reset input through IPC";
CM_ SG_ 693 OATICSig "Signal represents Outside Ambient Temperature raw value evaluated by Instrument Cluster ";
CM_ SG_ 693 BattVoltIPC "Battery voltage evaluated by IPC";
CM_ SG_ 693 LowFuelOutputICStatus "Status information";
CM_ SG_ 693 LowFuelOutputIC "Signal represents that Fuel volume is less";
CM_ SG_ 693 ParkBrkState " Signal represents Status of ParkBrake";
CM_ SG_ 693 IcPlatformVariant "IC shall publish its variant type to all partner ECUs.";
CM_ SG_ 693 OATICSigStatus "Signal represents Status of OATSig";
CM_ SG_ 693 IcPresence "IC shall publish its presence to all partner ECUs";
CM_ SG_ 693 SRSWarningLampStatus "AWL Warning Lamp Status from IC";
CM_ SG_ 693 VsSPulseCountSigStatus "Indicates status of VsSPulseCountSig status";
CM_ SG_ 693 VsSPulseCountSig "Signal represents the number of VSS pulses produced.";
CM_ SG_ 693 IcHuVoiceAlertState "IC sends alerts to HU.";
CM_ SG_ 693 IcHuVoiceAlertStateStatus "Status of IcHUVoiceAlert signal";
CM_ SG_ 693 ICCurDriveModeSig "Signal represents the current drive mode selected in Vehicle";
CM_ SG_ 693 IcHuCarImageSelection "Car image selection";
CM_ SG_ 693 IcSbDispReq "Indicates request to infotainment to drive IC display";
CM_ SG_ 693 IcSbrDrvrSeatBeltSwitchStatus "Driver seat belt information";
CM_ SG_ 695 RefuelAlert "This information is used to display or indicate the re-fueling alert";
CM_ SG_ 695 IcHuTripAInfo "This signal indicates Trip A info.";
CM_ SG_ 695 IcHuDrvrSeatBeltInfo "Driver seat belt information";
CM_ SG_ 695 IcHuTripBInfo "This signal indicates Trip B info.";
CM_ SG_ 695 IcHuDTeInfo "This signal indicates distance to empty info.";
CM_ SG_ 695 IcHuVehRegion "This signal indicates the  vehicle geography.";
CM_ SG_ 695 IcHuTyreSize "This signal indicates the  vehicle tyre size.";
CM_ SG_ 695 RevGearIPC "RevGear engaged/disengaed Signal";
CM_ SG_ 695 IcHuFuelVolumeInfoPercen "This signal indicates fuel volume in % .";
CM_ SG_ 695 RevGearIPCStatus "Status of the RevGear";
CM_ SG_ 697 IcHuOnBoardCompState "Indicates the Function state";
CM_ SG_ 697 IcHuIcInfoFeaturePresenceAck "Media Information in IC";
CM_ SG_ 697 IcHuAlertType "Informs type of alert";
CM_ SG_ 697 IcHuAlertStateStatus "Alert Status";
CM_ SG_ 697 IcHuAlertState "IC HU test message details";
CM_ SG_ 697 DriveAlert1_TeaBreak "Tea Break alert from IC to HU";
CM_ SG_ 697 IcHuAverFuelEconTripA "This signal indicates average fuel economy of Trip A .";
CM_ SG_ 697 IcHuAverFuelEconTripB "This signal indicates average fuel economy of Trip B.";
CM_ SG_ 697 IcHuFuelTankCapacity "This signal indicates fuel tank capacity info.";
CM_ SG_ 697 IcHuFuelVolumeInfoLtrs "This signal indicates fuel volume in litres";
CM_ SG_ 697 IcHuInstFuelEcoInfo "This signal indicates fuel economy in litres.";
CM_ SG_ 697 IcHuResetTripB "This signal indicates the Set/Reset of Trip B.";
CM_ SG_ 697 IcHuResetTripA "This signal indicates the Set/Reset of Trip A.";
CM_ SG_ 697 IcHuDriveType "This signal indicates the drive type of vehicle.";
CM_ SG_ 698 IllumDimLvlSetting "Signal represents Dimming Level evaluated by Instrument Cluster";
CM_ SG_ 698 IllumDimLvlSettingStatus "Signal represents Status of Dimming Level Signal";
CM_ SG_ 698 SwitchDimmingControlIPC "Status of Switch Illumination";
CM_ SG_ 698 IllumOnOffCtrlStatus "status of the interior illumination";
CM_ SG_ 698 IllumOnOffCtrl "this signal is used to turn ON/OFF the interior illumination of the individual ECU's";
CM_ SG_ 698 SwitchDimmingControlIPCStatus "Status of Switch Illumination status";
CM_ SG_ 699 CruiseSpeedChangeStateIPC "Indicates Cruise Speed Inc / Dec through the  cluster";
CM_ SG_ 699 CruiseSwitchSelStatusIPC "status information to CruiseStateStatus";
CM_ SG_ 699 CruiseSwitchSelStateIPC "This function indicates Cruise Selection by cluster";
CM_ SG_ 699 RegenSelectionSwStateIPC "Transmit user selected Regen Level";
CM_ SG_ 699 RegenSelectionSwStatusIPC "Transmit user selected Regen Level";
CM_ SG_ 699 IcHuTripAInfofull "This signal indicates Trip A info";
CM_ SG_ 699 IcHuTripBInfofull "This signal indicates Trip B info";
CM_ SG_ 700 IPCRemoteCheckStatus "IPC Remote Engine and AC signal check Status";
CM_ SG_ 700 IPCRemoteCheck "IPC Remote Engine and AC signal check";
CM_ SG_ 700 IcHuServReminderDays "This signal indicates the  service reminder in days.";
CM_ SG_ 700 IcHuServReminderKm "This signal indicates the  service reminder in Kms";
CM_ SG_ 700 IcHuIceState "This information is used   to display or indicate the possibility of snowfall.";
CM_ SG_ 700 IcHuBrakeFluidLowState "This information is used   to display or indicate the Brake fluid low state .";
CM_ SG_ 700 IcHuFastenSeatBeltState "This information is used   to display or indicate the FASTEN SEAT BELT state.";
CM_ SG_ 700 IcHuEngSystemFaultState "This information is used   to display or indicate the ENGINE SYSTEM FAULT state.";
CM_ SG_ 700 IcHuEngRestrictedPerformanceStat "This information is used   to display or indicate the ENGINE RESTRICTED PERFORMANCE state.";
CM_ SG_ 700 IcHuBatteryChargingState "This information is used   to display or indicate the Battery Charging state .";
CM_ SG_ 700 IcHuFuelLevelLowState "This information is used   to display or indicate the Fuel level low state.";
CM_ SG_ 700 IcHuEngineOilPressureLowState "This information is used   to display or indicate the Engine oil pressure low state .";
CM_ SG_ 700 NextServDueAlert "signal represents the next service due alert ";
CM_ SG_ 700 NextServDueAlertStatus "signal represents the next service due alert status";
CM_ SG_ 700 IcHuServReminderDaysfull "This signal indicates the  service reminder in days.";
CM_ SG_ 702 IcHuIFEHistogramInfo1 "This signal indicates fuel economy in litres.";
CM_ SG_ 702 IcHuIFEHistogramInfo2 "This signal indicates fuel economy in litres.";
CM_ SG_ 702 IcHuIFEHistogramInfo4 "This signal indicates fuel economy in litres.";
CM_ SG_ 702 IcHuIFEHistogramInfo3 "This signal indicates fuel economy in litres.";
CM_ SG_ 702 IcHuIFEHistogramInfo5 "This signal indicates fuel economy in litres.";
CM_ SG_ 702 IcHuOnBoardCompState "Indicates the Function state";
CM_ SG_ 702 IcHuIcInfoFeaturePresenceAck "Media Information in IC";
CM_ SG_ 702 IcHuAlertStateStatus "Alert Status";
CM_ SG_ 702 IcHuAlertType "Informs type of alert";
CM_ SG_ 702 DriveAlert1_TeaBreak "Tea Break alert from IC to HU";
CM_ SG_ 702 IcHuAlertState "IC HU test message details";
CM_ SG_ 704 GpsCompassPresence "This is to check compass information, available or not in IVI ";
CM_ SG_ 704 GPsCourseInfoIVI "This signal shall be published by IVI . It shall contain GPS Course angle info";
CM_ SG_ 704 GPsCourseInfoStatusIVI "Status of signal GPsCourseInfoStatusIVI";
CM_ SG_ 704 HuEMsRegenReqStatus "This signal is used to indicate plausibility status of DPF regeneration request signal.";
CM_ SG_ 704 HuEMsRegenReq "This signal is used for requesting / cancelling the regenration request.";
CM_ SG_ 704 HuCcmRearBlwrOnOffReq "Transmit Rear Blower ON/OFF Request to CCM.";
CM_ SG_ 704 StuckModeUserResponse "User input information for end user";
CM_ SG_ 704 HuIcDistanceDisplayUnitEnum "Indicating navigation next turn round disatnce unit";
CM_ SG_ 704 HuPresence "HU shall publish its presence to all partner ECUs.";
CM_ SG_ 704 HuPlatformVariant "HU shall publish its variant type to all partner ECUs";
CM_ SG_ 704 BattVolt_HU "Battery voltage evaluated by HU";
CM_ SG_ 704 SbIcDispState "Indicates silver box readiness to drive IC display";
CM_ SG_ 704 TpmsEnterLearning "Trigger Wheel Sensor Learning In TPMS";
CM_ SG_ 704 HuIcAlertStatusAck "Alert delivery status";
CM_ SG_ 704 HuIcAlertStateAck " HU send ack for each alert";
CM_ SG_ 706 HuIcNaviSource "Indicating navigation source type";
CM_ SG_ 706 HuIcCarPlayManeuverType "Indicating car play navigation source type";
CM_ SG_ 706 HuIcNextTurnDistance "Navigation Info In IC";
CM_ SG_ 706 HuIcNextTurnEstimateSec "Navigation Info In IC";
CM_ SG_ 706 HuIcNextTurnRoundDist "Navigation Info In IC";
CM_ SG_ 706 HuIcNextTurnEstimateMin "Navigation Info In IC";
CM_ SG_ 706 HuIcNextTurnSideEnum "Navigation Info In IC";
CM_ SG_ 706 HuIcNextTurnEstimateHrs "Navigation Info In IC";
CM_ SG_ 706 HuIcNextTurnRoundDistUnits "Navigation Info In IC";
CM_ SG_ 706 HuIcNaviStatus "Navigation Info In IC";
CM_ SG_ 706 HuIcNextTurnSide "Navigation Info In IC";
CM_ SG_ 706 HuIcRoundAboutType "Indicating navigation next turn round type";
CM_ SG_ 706 HuIcColorStatus "Theme color from HU to IC";
CM_ SG_ 707 LinSwcSbPowerModeCan "It is used to specify LinSwc power mode state";
CM_ SG_ 707 LinSwcIcKey9Can "It is used to specify Reserve key9 state";
CM_ SG_ 707 LinSwcIcKey8Can "It is used to specify Reserve key8 state";
CM_ SG_ 707 LinSwcIcKey7Can "It is used to specify Reserve key7 state";
CM_ SG_ 707 LinSwcIcKey6Can "It is used to specify Reserve key6 state";
CM_ SG_ 707 LinSwcIcViewCan "It is used to specify view Button state";
CM_ SG_ 707 LinSwcIcMenuSelectCan "It is used to specify menu select Button state";
CM_ SG_ 707 LinSwcIcMenuDownCan "It is used to specify menu down Button state";
CM_ SG_ 707 LinSwcIcMenuUpCan "It is used to specify menu up Button state";
CM_ SG_ 707 LinSwcIcpaginationCan "It is used to specify pagination Button state";
CM_ SG_ 707 LinSwcPresenceCanStatus "LinSwcIc shall publish its status to all partner ECUs.";
CM_ SG_ 707 LinSwcIcVariant "LinSwcIc shall publish its variant type to all partner ECUs.";
CM_ SG_ 707 LinSwcPresenceCan "LinSwc shall publish its presence to partner ECUs.";
CM_ SG_ 707 HuIcVoiceAlertStatusAck "HU transmits status of alerts to IC.";
CM_ SG_ 707 HuIcVoiceAlertStateAck "HU Acknowledges to the alert received by IPC.";
CM_ SG_ 708 SbCurrentAudioSource "Silver Box shall published its current audio source";
CM_ SG_ 708 DispVariant "HU shall publish its variant type to all partner ECUs.";
CM_ SG_ 708 SbPowerModeConfig "Silver Box shall published its current power mode configuration";
CM_ SG_ 708 SbCurrentPowerMode "Silver Box shall published its current operating power mode";
CM_ SG_ 708 BpVariant "HU shall publish its variant type to all partner ECUs.";
CM_ SG_ 708 DispCurrentPowerMode "Silver Box shall published display current operating power mode";
CM_ SG_ 708 BpCurrentPowerMode "Silver Box shall published button panel current operating power mode";
CM_ SG_ 708 BpPresence "HU shall publish its presence to all partner ECUs.";
CM_ SG_ 708 BattVoltSb "Silver Box Battery Voltage";
CM_ SG_ 708 DispPresence "HU shall publish its presence to all partner ECUs.";
CM_ SG_ 710 PDcHuFaultState "This input signal to HU from BCM is to update Rear PDC fault  information.";
CM_ SG_ 710 PDcHuAudioZoneState "This signal is used as an output from BCM to HU to know Audio Zone state for rear PDC.";
CM_ SG_ 710 PDcHuVisualZoneRearLHSensState "It is used as an input to HU from BCM to update the display warning zone from RearLeft Sensor";
CM_ SG_ 710 PDcHuVisualZoneRearMidRHSensStat "It is used as an input to HU from BCM to update the display warning zone from Rear Mid-Right sensor.";
CM_ SG_ 710 PDcHuVisualZoneRearRHSensState "It is used as an input to HU from BCM to update the display warning zone from Rear Right sensor.";
CM_ SG_ 710 PDcHuVisualZoneRearMidLHSensStat "It is used as an input to HU from BCM to update the display warning zone from Rear Mid-Left sensor.";
CM_ SG_ 710 PDcPresence "This is O/P signal from PDC to provide its presence to all ECU in n/w";
CM_ SG_ 710 PDcHuState "This signal is used an input from BCM to HU to know Rear PDC function is Active/Deactive state.";
CM_ SG_ 710 PDcHuPwrModeState "It is used to know PDC power mode.";
CM_ SG_ 710 PDcVariant "This is O/P signal from PDC to provide its variant details to all other ECUs in n/w";
CM_ SG_ 710 PDcHuVisualZoneFrontLHSensState "IIt is used as an input to HU from BCM to update the display warning zone from Rear Left sensor.";
CM_ SG_ 710 PDcHuVisualZoneFrontMidLHSensSta "It is used as an input to HU from BCM to update the display warning zone from Rear Mid-Left sensor.";
CM_ SG_ 710 PDcHuVisualZoneFrontMidRHSensSta "It is used as an input to HU from BCM to update the display warning zone from Rear Mid-Right sensor.";
CM_ SG_ 710 PDcHuVisualZoneFrontRHSensState "It is used as an input to HU from BCM to update the display warning zone from Rear Right sensor.";
CM_ SG_ 710 PDcHuFrontAudioZoneState "This signal is used as an output from BCM to HU to know Audio Zone state for Front PDC";
CM_ SG_ 710 PDcHuFrontFaultState "This input signal to HU from BCM is to update Front PDC fault  information.";
CM_ SG_ 710 PDcHuFrontState "This signal is used an input from BCM to HU to know Front PDC function is Active/Deactive state.";
CM_ SG_ 710 PDcIPcFrontActive "This signal is sent by BCM to IPC for displaying PDC warnings";
CM_ SG_ 710 PDcIPcRearActive "This signal is sent by BCM to IPC for displaying PDC warnings";
CM_ SG_ 711 PDcHuProxFrontLHSensState "IIt is used as an input to HU from BCM to update proximity distance  from Front Left sensor.";
CM_ SG_ 711 PDcHuProxFrontRHSensState "It is used as an input to HU from BCM to update proximity distance  from Front Right sensor.";
CM_ SG_ 711 PDcHuProxFrontMidLHSensState "It is used as an input to HU from BCMto update proximity distance  from Front Mid-Left sensor.";
CM_ SG_ 711 PDcHuProxFrontMidRHSensState "It is used as an input to HU from BCM to update proximity distance  from Front Mid-Right sensor.";
CM_ SG_ 711 PDcHuProxFrontRHSensStateStatus "It is used to know proximity info status.BCM will send Plausible / Implausible status to HU.";
CM_ SG_ 711 PDcHuProxFrontMidRHSensStateStat "It is used to know proximity info status.BCM will send Plausible / Implausible status to HU.";
CM_ SG_ 711 PDcHuProxFrontMidLHSensStateStat "It is used to know proximity info status.BCM will send Plausible / Implausible status to HU.";
CM_ SG_ 711 PDcHuProxFrontLHSensStateStatus "It is used to know proximity info status.BCM will send Plausible / Implausible status to HU.";
CM_ SG_ 712 PDcHuProxRearLHSensState "It is used as an input to HU from BCM to update proximity distance  from Rear Left sensor.";
CM_ SG_ 712 PDcHuProxRearRHSensState "It is used as an input to HU from BCM to update proximity distance  from Rear Right sensor.";
CM_ SG_ 712 PDcHuProxRearMidLHSensState "IIt is used as an input to HU from BCMto update proximity distance  from Rear Mid-Left sensor.";
CM_ SG_ 712 PDcHuProxRearMidRHSensState "It is used as an input to HU from BCM to update proximity distance  from Rear Mid-Right sensor.";
CM_ SG_ 712 PDcHuProxRearRHSensStateStatus "It is used to know proximity info status.BCM will send Plausible / Implausible status to HU.";
CM_ SG_ 712 PDcHuProxRearMidRHSensStateStatu "It is used to know proximity info status.BCM will send Plausible / Implausible status to HU.";
CM_ SG_ 712 PDcHuProxRearMidLHSensStateStatu "It is used to know proximity info status.BCM will send Plausible / Implausible status to HU.";
CM_ SG_ 712 PDcHuProxRearLHSensStateStatus "It is used to know proximity info status.BCM will send Plausible / Implausible status to HU.";
CM_ SG_ 713 HuIcMediaState "Media Information in IC";
CM_ SG_ 713 HuIcSource "Media Information in IC";
CM_ SG_ 713 HuIcAudioVolumeStatus "Media Information in IC";
CM_ SG_ 713 HuIcBTStatus "Media Information in IC";
CM_ SG_ 713 HuIcPlabackCallDurationSec "Media Information in IC";
CM_ SG_ 713 HuIcRepeatOneState "Media Information in IC";
CM_ SG_ 713 HuIcMuteStatus "Media Information in IC";
CM_ SG_ 713 HuIcPlabackCallDurationMin "Media Information in IC";
CM_ SG_ 713 HuIcSMSReceiveState "Media Information in IC";
CM_ SG_ 713 HuIcRepeatState "Media Information in IC";
CM_ SG_ 713 HuIcPlabackCallDurationHrs "Media Information in IC";
CM_ SG_ 713 HuIcPhoneCallStatus "Media Information in IC";
CM_ SG_ 713 HuIcPlaybackElapsedTimeHrs "Media Information in IC";
CM_ SG_ 713 HuIcNetworkSignalStatus "Media Information in IC";
CM_ SG_ 713 HuIcPlaybackElapsedTimeMin "Media Information in IC";
CM_ SG_ 713 HuIcInfoFeaturePresence "Media Information in IC";
CM_ SG_ 713 HuIcShuffleState "Media Information in IC";
CM_ SG_ 713 HuIcPlaybackElapsedTimeSec "Media Information in IC";
CM_ SG_ 714 TrailerPositionLmpMalFn "Trailer Position Lamp malfunction signal";
CM_ SG_ 714 TrailerRevLmpMalFn "Trailer Reverse Lamp malfunction signal";
CM_ SG_ 714 TrailerBrkLmpMalFnStatus "Trailer Brake Lamp malfunction signal status";
CM_ SG_ 714 TrailerBrkLmpMalFn "Trailer Brake Lamp malfunction signal";
CM_ SG_ 714 TrailerPresenceStatus "Status of the Trailer Presence signal";
CM_ SG_ 714 TrailerTurnLhMalFn "Trailer Turn left side indicator lamp malfunction signal";
CM_ SG_ 714 TrailerFogMalFnStatus "Trailer Fog Lamp malfunction signal status";
CM_ SG_ 714 TrailerFogMalFn "Trailer Fog Lamp malfunction signal";
CM_ SG_ 714 TrailerPositionLmpMalFnStatus "Trailer Position Lamp malfunction signal status";
CM_ SG_ 714 TrailerRevLmpMalFnStatus "Trailer Reverse Lamp malfunction signal status";
CM_ SG_ 714 TrailerTurnRhMalFnStatus "Trailer Turn right side indicator lamp malfunction signal status";
CM_ SG_ 714 TrailerTurnRhMalFn "Trailer Turn right side indicator lamp malfunction signal";
CM_ SG_ 714 TrailerTurnLhMalFnStatus "Trailer Turn left side indicator lamp malfunction signal status";
CM_ SG_ 715 RemoteAcStatus "Plausibility status of Remote AC ON/OFF status from FATC to TCM";
CM_ SG_ 715 RemoteAcState "Remote AC ON/OFF status from FATC to TCM";
CM_ SG_ 715 CcmEmsIACReqSts "Intelligent Alternator CCM Status Request";
CM_ SG_ 715 CcmEmsIACReq "Intelligent Alternator CCM Request";
CM_ SG_ 715 AcReq "EMS to recive the signal from FATC to know the AC request by driver";
CM_ SG_ 715 VehicleInteriorTemp "HVAC receives the raw Interior temperature value from sensor and transmits the same to IPC for global snapshot only";
CM_ SG_ 715 HRwReqFrmCCmStatus "Indicates the status whether the heated rear window is requested from Climate Control Module.";
CM_ SG_ 715 CCmVariantType "Indicates whether CCM is ETC/FATC single or dual zone";
CM_ SG_ 715 CCmPresence " presence of CCM ECU";
CM_ SG_ 715 VehicleInteriorTempStatus "sensor value status";
CM_ SG_ 715 HRwReqFrmCCm "Indicates the state (ON/OFF) whether the heated rear window is requested from Climate Control Module.";
CM_ SG_ 715 CcmEmsEngStopStartReq "CCM to give the EMS permission to stop the engine when the cabin comfort is at an acceptable level";
CM_ SG_ 715 CcmEmsEngStopStartReqSts "Engine Stop/Start request Status";
CM_ SG_ 715 EVAPSig "Signal represents Evaporator Temperature raw value ";
CM_ SG_ 715 EVAPSigStatus "Signal represents Status of EVAPSig";
CM_ SG_ 720 RearWasherStateStatus "Status of Rear Washer function Activate/Deactivate state  to various ECUs";
CM_ SG_ 720 RearWasherState "Rear Washer function Activate/Deactivate state  to various ECUs";
CM_ SG_ 720 FrontWasherStateStatus "Status of Front Washer function Activate/Deactivate state  to various ECUs";
CM_ SG_ 720 FrontWasherState "Front Washer function Activate/Deactivate state  to various ECUs";
CM_ SG_ 720 AutoWipeStateStatus "Status of the Wiper sensor active";
CM_ SG_ 720 AutoWipeState "When an auto wipe switch is configured as a separate switch and is non-latchable then BCM shall communicate  the wipe sensor ON status text message signal AutoWipeState via CAN to partner ECU";
CM_ SG_ 720 PositionLmpTelltale "IC to display the position lamp telltale when the position lamp is active. (For backlight illumination - wherever Telltale is not applicable)IC to display the position lamp telltale when the position lamp is active. (For backlight illumination - wherever Telltale is not applicable)IC to display the position lamp telltale when the position lamp is active. (For backlight illumination - wherever Telltale is not applicable)";
CM_ SG_ 720 PositionLmpTelltaleStatus "Status of the Position Lamp Tell-taleStatus of the Position Lamp Tell-taleStatus of the Position Lamp Tell-tale";
CM_ SG_ 720 BattVolt_BCM "Battery voltage evaluated by BCM";
CM_ SG_ 720 BCMVariant "Indicates the BCM variant to other ECU, if BCM is present.";
CM_ SG_ 720 BCMPresence "Indicates the state of the BCM presence to other ECU.";
CM_ SG_ 720 RevGearStatus "Status of the Reverse gear";
CM_ SG_ 720 RevGear "Status of the Reverse gear";
CM_ SG_ 720 RevLmpON "Reverse Lamp signal";
CM_ SG_ 720 RevLmpONStatus "Status of the Reverse Lamp signal";
CM_ SG_ 720 RearFogLmpON "Rear Fog Lamp signal";
CM_ SG_ 720 RearFogLmpONStatus "Status of the Rear Fog Lamp signal";
CM_ SG_ 720 TurnLHTelltaleStatus "Status of the turn left tell-tale";
CM_ SG_ 720 TurnLHTelltale "IC to display the turn left tell-tale when the left side indicator lamp is active";
CM_ SG_ 720 TurnRHTelltaleStatus "Status of the turn right tell-tale





";
CM_ SG_ 720 TurnRHTelltale "IC to display the turn right tell-tale when the right side indicator lamp is active



";
CM_ SG_ 720 LightSensActiveStatus "Status of the Light sensor active";
CM_ SG_ 720 LightSensActive "When an auto light switch is configured as a separate switch and is non-latchable then BCM shall communicate  the light sensor ON status text message signal LightSensorActive via CAN to IC.";
CM_ SG_ 720 RVcPresence "This signal is used as an input from BCM to HU to know if camera is present and if it is what type of camera it is";
CM_ SG_ 720 BcmCcmSolarInputLh "Solar input signal from BCM to CCM(LH)";
CM_ SG_ 720 BcmCcmSolarInputRh "Solar input signal from BCM to CCM(RH)";
CM_ SG_ 722 PowerModeStateStatus "This signal is used to verify the correctness of Power Mode Status";
CM_ SG_ 722 PowerModeState "Vehicle power mode signal shall be used by all ECUs of the vehicle for their respective functional implementation";
CM_ SG_ 722 PositionLmpTelltaleStatus "Status of the Position Lamp Tell-tale";
CM_ SG_ 722 PositionLmpTelltale "IC to display the position lamp telltale when the position lamp is active. (For backlight illumination - wherever Telltale is not applicable)";
CM_ SG_ 722 HRwFdBkFrmBCm "Indicates the feedback for HRW from BCM.";
CM_ SG_ 722 HRwFdBkFrmBCmStatus "Indicates the feedback status for HRW from BCM.";
CM_ SG_ 722 TurnRHTelltale "IC to display the turn right tell-tale when the right side indicator lamp is active



";
CM_ SG_ 722 TurnLHTelltaleStatus "Status of the turn left tell-tale";
CM_ SG_ 722 TurnLHTelltale "IC to display the turn left tell-tale when the left side indicator lamp is active";
CM_ SG_ 722 TurnRHTelltaleStatus "Status of the turn right tell-tale





";
CM_ SG_ 722 BattSaverFnONStatus "Status of the Battery Saver Function ON





";
CM_ SG_ 722 BattSaverFnON "BCM to transmit battery saver active message when the battery saver mode is made active.



";
CM_ SG_ 722 BrkLmpONStatus "Status of the Brake Lamp signal";
CM_ SG_ 722 BrkLmpON "Brake Lamp signal";
CM_ SG_ 722 CockpitSigECuStatus "Status of the Cockpit Signal ECU.";
CM_ SG_ 722 RearRHTurnLmpON "BCM to Trailer ECU to turn ON/ OFF Trailer RH turn indicator";
CM_ SG_ 722 RearRHTurnLmpONStatus "Status of the RearRHTurnLmpON signal";
CM_ SG_ 722 RearLHTurnLmpONStatus "Status of the RearLHTurnLmpON signal";
CM_ SG_ 722 RearLHTurnLmpON "BCM to Trailer ECU to turn ON/ OFF Trailer LH turn indicator";
CM_ SG_ 722 CockpitSigECu "BCM sends cockpit signal to other ECUs. It is 'Package Protected' signal.


";
CM_ SG_ 722 VehicleLockStateStatus "Status of the 'VehicleLockState' signal";
CM_ SG_ 722 HighBeamTelltaleStatus "Status of the High Beam Telltale";
CM_ SG_ 722 HighBeamTelltale "IC to display the high beam tell-tale when the high beam lamp is active";
CM_ SG_ 722 KeyInStateStatus "This signal is used to verify the correctness of Key-In Signal.";
CM_ SG_ 722 KeyInState "Key-In signal used by IC ECUs of the vehicle for their respective functional implementation";
CM_ SG_ 722 PowerModeStateMsgCnt "Message counter for E2E-Protection";
CM_ SG_ 722 VehicleLockState "Vehicle central lock state signal from BCM to PEPS ECU";
CM_ SG_ 722 PowerModeStateCRC "CRC-Checksum over signals for E2E-Protection.";
CM_ SG_ 729 VehicleMobilizationStateStatus "Status of the VehicleMobilizationState signal";
CM_ SG_ 729 VehicleMobilizationState "Vehicle Mobilization and immobilization  response to prevent vehicle crank";
CM_ SG_ 729 KeySearchStatusPEPS "PEPS UID search status while learning";
CM_ SG_ 729 PEPsClampState "PEPS power mode signal shall be used by BCM for it's respective functional implementation";
CM_ SG_ 729 PEPsClampStateStatus "Status of the 'PEPSClampState' signal";
CM_ SG_ 729 ESClLockInhibitPEPS "Signal for the ESCL to prevent Locking";
CM_ SG_ 729 PEPsPresence "Indicates the state of the PEPS presence to other ECU.";
CM_ SG_ 729 PEPsKeyInState "PEPS KeyIn state from PEPS to BCM - 'Inside the vehicle / Outside the vehicle'";
CM_ SG_ 729 PEPsVehLockCmd "Vehicle lock command signal";
CM_ SG_ 729 PEPsVehLockCmdStatus "Status of the VehicleLockCommand signal";
CM_ SG_ 729 PEPsClampStateMRC "Message counter for E2E-Protection";
CM_ SG_ 729 PEPsClampStateCRC "CRC for E2E protection";
BA_DEF_ SG_  "Remarks" STRING ;
BA_DEF_ SG_  "NWM_WakeupAllowed" ENUM  "No","Yes";
BA_DEF_ SG_  "GenSigTimeoutTime_HU_Mid_X451" INT 0 65535;
BA_DEF_ SG_  "GenSigTimeoutTime_HU_High_X451" INT 0 65535;
BA_DEF_ SG_  "GenSigTimeoutTime_HU_B" INT 0 65535;
BA_DEF_ SG_  "GenSigTimeoutTime_HU_A" INT 0 65535;
BA_DEF_ SG_  "GenSigTimeoutTime_BCM_Mid" INT 0 65535;
BA_DEF_ SG_  "GenSigTimeoutMsg_HU_Mid_X451" INT 0 65535;
BA_DEF_ SG_  "GenSigTimeoutMsg_HU_High_X451" INT 0 65535;
BA_DEF_ SG_  "GenSigTimeoutMsg_HU_B" INT 0 65535;
BA_DEF_ SG_  "GenSigTimeoutMsg_HU_A" INT 0 65535;
BA_DEF_ SG_  "GenSigStartValue" INT 0 0;
BA_DEF_ SG_  "GenSigSendType" ENUM  "Cyclic","OnWrite","OnWriteWithRepetition","OnChange","OnChangeWithRepetition","IfActive","IfActiveWithRepetition","NoSigSendType","NotUsed","NotUsed","NotUsed","NotUsed","NotUsed";
BA_DEF_ SG_  "GenSigInactiveValue" INT 0 0;
BA_DEF_ SG_  "GenSigEnvVarType" ENUM  "int","float","undef";
BA_DEF_ SG_  "GenSigCycleTimeActive" INT 0 0;
BA_DEF_ SG_  "GenSigCycleTime" INT 0 0;
BA_DEF_ SG_  "GenSigTimeoutMsg_HU_High_X445" INT 0 65535;
BA_DEF_ SG_  "GenSigTimeoutMsg_HU_Mid_X445" INT 0 65535;
BA_DEF_ SG_  "GenSigTimeoutTime_HU_High_X445" INT 0 65535;
BA_DEF_ SG_  "GenSigTimeoutTime_HU_Mid_X445" INT 0 65535;
BA_DEF_ SG_  "GenSigTimeoutMsg_IVI" INT 0 65535;
BA_DEF_ SG_  "GenSigTimeoutTime_IVI" INT 0 65535;
BA_DEF_ BO_  "NmMessage" ENUM  "no","yes";
BA_DEF_ BO_  "NmAsrMessage" ENUM  "<n.a.>","No","Yes";
BA_DEF_ BO_  "MessageTimeout" INT 0 65535;
BA_DEF_ BO_  "Me" INT 0 0;
BA_DEF_ BO_  "GenMsgStartDelayTime" INT 0 0;
BA_DEF_ BO_  "GenMsgSendType" ENUM  "Cyclic","NotUsed","NotUsed","NotUsed","NotUsed","NotUsed","NotUsed","IfActive","NoMsgSendType","NotUsed";
BA_DEF_ BO_  "GenMsgNrOfRepetition" INT 0 0;
BA_DEF_ BO_  "GenMsgILSupport" ENUM  "No","Yes";
BA_DEF_ BO_  "GenMsgDelayTime" INT 0 0;
BA_DEF_ BO_  "GenMsgCycleTimeFast" INT 0 0;
BA_DEF_ BO_  "GenMsgCycleTime" INT 0 0;
BA_DEF_ BO_  "DiagUudtResponse" ENUM  "false","true";
BA_DEF_ BO_  "DiagUsdtResponse" ENUM  "false","true";
BA_DEF_ BO_  "DiagState" ENUM  "No","Yes";
BA_DEF_ BO_  "DiagResponse" ENUM  "No","Yes";
BA_DEF_ BO_  "DiagRequest" ENUM  "No","Yes";
BA_DEF_ BO_  "MsgType" ENUM  "Application","NM","NMH";
BA_DEF_ SG_  "SystemSignalLongSymbol" STRING ;
BA_DEF_DEF_  "Remarks" "null";
BA_DEF_DEF_  "NWM_WakeupAllowed" "No";
BA_DEF_DEF_  "GenSigTimeoutTime_HU_Mid_X451" 500;
BA_DEF_DEF_  "GenSigTimeoutTime_HU_High_X451" 500;
BA_DEF_DEF_  "GenSigTimeoutTime_HU_B" 500;
BA_DEF_DEF_  "GenSigTimeoutTime_HU_A" 500;
BA_DEF_DEF_  "GenSigTimeoutTime_BCM_Mid" 0;
BA_DEF_DEF_  "GenSigTimeoutMsg_HU_Mid_X451" 500;
BA_DEF_DEF_  "GenSigTimeoutMsg_HU_High_X451" 500;
BA_DEF_DEF_  "GenSigTimeoutMsg_HU_B" 500;
BA_DEF_DEF_  "GenSigTimeoutMsg_HU_A" 500;
BA_DEF_DEF_  "GenSigStartValue" 0;
BA_DEF_DEF_  "GenSigSendType" "Cyclic";
BA_DEF_DEF_  "GenSigInactiveValue" 0;
BA_DEF_DEF_  "GenSigEnvVarType" "undef";
BA_DEF_DEF_  "GenSigCycleTimeActive" 0;
BA_DEF_DEF_  "GenSigCycleTime" 0;
BA_DEF_DEF_  "GenSigTimeoutMsg_HU_High_X445" 500;
BA_DEF_DEF_  "GenSigTimeoutMsg_HU_Mid_X445" 500;
BA_DEF_DEF_  "GenSigTimeoutTime_HU_High_X445" 500;
BA_DEF_DEF_  "GenSigTimeoutTime_HU_Mid_X445" 500;
BA_DEF_DEF_  "GenSigTimeoutMsg_IVI" 500;
BA_DEF_DEF_  "GenSigTimeoutTime_IVI" 500;
BA_DEF_DEF_  "NmMessage" "no";
BA_DEF_DEF_  "NmAsrMessage" "<n.a.>";
BA_DEF_DEF_  "MessageTimeout" 500;
BA_DEF_DEF_  "Me" 0;
BA_DEF_DEF_  "GenMsgStartDelayTime" 0;
BA_DEF_DEF_  "GenMsgSendType" "Cyclic";
BA_DEF_DEF_  "GenMsgNrOfRepetition" 0;
BA_DEF_DEF_  "GenMsgILSupport" "Yes";
BA_DEF_DEF_  "GenMsgDelayTime" 0;
BA_DEF_DEF_  "GenMsgCycleTimeFast" 0;
BA_DEF_DEF_  "GenMsgCycleTime" 0;
BA_DEF_DEF_  "DiagUudtResponse" "false";
BA_DEF_DEF_  "DiagUsdtResponse" "false";
BA_DEF_DEF_  "DiagState" "No";
BA_DEF_DEF_  "DiagResponse" "No";
BA_DEF_DEF_  "DiagRequest" "No";
BA_DEF_DEF_  "MsgType" "Application";
BA_DEF_DEF_  "SystemSignalLongSymbol" "";
BA_ "GenMsgCycleTime" BO_ 661 100;
BA_ "GenMsgStartDelayTime" BO_ 662 10;
BA_ "GenMsgCycleTime" BO_ 662 100;
BA_ "GenMsgCycleTime" BO_ 664 100;
BA_ "GenMsgCycleTime" BO_ 666 100;
BA_ "GenMsgStartDelayTime" BO_ 693 5;
BA_ "GenMsgCycleTime" BO_ 693 100;
BA_ "GenMsgStartDelayTime" BO_ 695 10;
BA_ "GenMsgCycleTime" BO_ 695 100;
BA_ "GenMsgStartDelayTime" BO_ 697 15;
BA_ "GenMsgCycleTime" BO_ 697 100;
BA_ "GenMsgStartDelayTime" BO_ 698 20;
BA_ "GenMsgCycleTime" BO_ 698 100;
BA_ "GenMsgCycleTime" BO_ 699 100;
BA_ "GenMsgStartDelayTime" BO_ 700 25;
BA_ "GenMsgCycleTime" BO_ 700 100;
BA_ "GenMsgCycleTime" BO_ 702 100;
BA_ "GenMsgCycleTime" BO_ 704 100;
BA_ "GenMsgCycleTime" BO_ 706 100;
BA_ "GenMsgStartDelayTime" BO_ 707 5;
BA_ "GenMsgCycleTime" BO_ 707 100;
BA_ "GenMsgStartDelayTime" BO_ 708 10;
BA_ "GenMsgCycleTime" BO_ 708 100;
BA_ "GenMsgCycleTime" BO_ 710 100;
BA_ "GenMsgCycleTime" BO_ 711 100;
BA_ "GenMsgStartDelayTime" BO_ 712 10;
BA_ "GenMsgCycleTime" BO_ 712 100;
BA_ "GenMsgCycleTime" BO_ 713 100;
BA_ "GenMsgCycleTime" BO_ 714 100;
BA_ "GenMsgCycleTime" BO_ 715 100;
BA_ "GenMsgCycleTime" BO_ 720 100;
BA_ "GenMsgStartDelayTime" BO_ 722 10;
BA_ "GenMsgCycleTime" BO_ 722 100;
BA_ "GenMsgCycleTime" BO_ 729 100;
BA_ "GenSigSendType" SG_ 661 MSG_CNT_1 7;
BA_ "GenSigCycleTimeActive" SG_ 661 MSG_CNT_1 100;
BA_ "GenSigCycleTime" SG_ 661 MSG_CNT_1 100;
BA_ "GenSigSendType" SG_ 661 CRC_1 7;
BA_ "GenSigCycleTimeActive" SG_ 661 CRC_1 100;
BA_ "GenSigCycleTime" SG_ 661 CRC_1 100;
BA_ "GenSigStartValue" SG_ 661 PSIP1 32768;
BA_ "GenSigSendType" SG_ 661 PSIP1 7;
BA_ "GenSigCycleTimeActive" SG_ 661 PSIP1 100;
BA_ "GenSigCycleTime" SG_ 661 PSIP1 100;
BA_ "GenSigSendType" SG_ 661 AccSystemState 7;
BA_ "GenSigCycleTimeActive" SG_ 661 AccSystemState 100;
BA_ "GenSigCycleTime" SG_ 661 AccSystemState 100;
BA_ "GenSigSendType" SG_ 661 DDOATextIndication 7;
BA_ "GenSigCycleTimeActive" SG_ 661 DDOATextIndication 100;
BA_ "GenSigCycleTime" SG_ 661 DDOATextIndication 100;
BA_ "GenSigSendType" SG_ 661 DDOAAvailability 7;
BA_ "GenSigCycleTimeActive" SG_ 661 DDOAAvailability 100;
BA_ "GenSigCycleTime" SG_ 661 DDOAAvailability 100;
BA_ "GenSigSendType" SG_ 661 DDOAState 7;
BA_ "GenSigCycleTimeActive" SG_ 661 DDOAState 100;
BA_ "GenSigCycleTime" SG_ 661 DDOAState 100;
BA_ "GenSigSendType" SG_ 661 DDOAFuncState 7;
BA_ "GenSigCycleTimeActive" SG_ 661 DDOAFuncState 100;
BA_ "GenSigCycleTime" SG_ 661 DDOAFuncState 100;
BA_ "GenSigSendType" SG_ 661 DriverChangeState 7;
BA_ "GenSigCycleTimeActive" SG_ 661 DriverChangeState 100;
BA_ "GenSigCycleTime" SG_ 661 DriverChangeState 100;
BA_ "GenSigSendType" SG_ 661 iTPMsIndctnStatus 7;
BA_ "GenSigCycleTimeActive" SG_ 661 iTPMsIndctnStatus 100;
BA_ "GenSigCycleTime" SG_ 661 iTPMsIndctnStatus 100;
BA_ "GenSigSendType" SG_ 661 iTPMsIndctn 7;
BA_ "GenSigCycleTimeActive" SG_ 661 iTPMsIndctn 100;
BA_ "GenSigCycleTime" SG_ 661 iTPMsIndctn 100;
BA_ "GenSigSendType" SG_ 661 iTPMsResetSett 7;
BA_ "GenSigCycleTimeActive" SG_ 661 iTPMsResetSett 100;
BA_ "GenSigCycleTime" SG_ 661 iTPMsResetSett 100;
BA_ "GenSigSendType" SG_ 661 iTPMsTxtInfoStatus 7;
BA_ "GenSigCycleTimeActive" SG_ 661 iTPMsTxtInfoStatus 100;
BA_ "GenSigCycleTime" SG_ 661 iTPMsTxtInfoStatus 100;
BA_ "GenSigSendType" SG_ 661 iTPMSTxtInfo 7;
BA_ "GenSigCycleTimeActive" SG_ 661 iTPMSTxtInfo 100;
BA_ "GenSigCycleTime" SG_ 661 iTPMSTxtInfo 100;
BA_ "GenSigSendType" SG_ 661 iTPMsAvailability 7;
BA_ "GenSigCycleTimeActive" SG_ 661 iTPMsAvailability 100;
BA_ "GenSigCycleTime" SG_ 661 iTPMsAvailability 100;
BA_ "GenSigSendType" SG_ 661 iTPMsStatus 7;
BA_ "GenSigCycleTimeActive" SG_ 661 iTPMsStatus 100;
BA_ "GenSigCycleTime" SG_ 661 iTPMsStatus 100;
BA_ "GenSigSendType" SG_ 662 BrakeAccPedalSimultaneouslyAlert 7;
BA_ "GenSigCycleTimeActive" SG_ 662 BrakeAccPedalSimultaneouslyAlert 100;
BA_ "GenSigCycleTime" SG_ 662 BrakeAccPedalSimultaneouslyAlert 100;
BA_ "GenSigSendType" SG_ 662 TxmnMilReq 7;
BA_ "GenSigCycleTimeActive" SG_ 662 TxmnMilReq 100;
BA_ "GenSigCycleTime" SG_ 662 TxmnMilReq 100;
BA_ "GenSigSendType" SG_ 662 GearIndicationTcuSts 7;
BA_ "GenSigCycleTimeActive" SG_ 662 GearIndicationTcuSts 100;
BA_ "GenSigCycleTime" SG_ 662 GearIndicationTcuSts 100;
BA_ "GenSigSendType" SG_ 662 BuzzerRequest 7;
BA_ "GenSigCycleTimeActive" SG_ 662 BuzzerRequest 100;
BA_ "GenSigCycleTime" SG_ 662 BuzzerRequest 100;
BA_ "GenSigSendType" SG_ 662 GearForDisplay 7;
BA_ "GenSigCycleTimeActive" SG_ 662 GearForDisplay 100;
BA_ "GenSigCycleTime" SG_ 662 GearForDisplay 100;
BA_ "GenSigSendType" SG_ 662 TransShiftModeSts 7;
BA_ "GenSigCycleTimeActive" SG_ 662 TransShiftModeSts 100;
BA_ "GenSigCycleTime" SG_ 662 TransShiftModeSts 100;
BA_ "GenSigSendType" SG_ 662 GearForDisplayStatus 7;
BA_ "GenSigCycleTimeActive" SG_ 662 GearForDisplayStatus 100;
BA_ "GenSigCycleTime" SG_ 662 GearForDisplayStatus 100;
BA_ "GenSigSendType" SG_ 662 RoboticTxmnFailCode 7;
BA_ "GenSigCycleTimeActive" SG_ 662 RoboticTxmnFailCode 100;
BA_ "GenSigCycleTime" SG_ 662 RoboticTxmnFailCode 100;
BA_ "GenSigSendType" SG_ 662 TransShiftMode 7;
BA_ "GenSigCycleTimeActive" SG_ 662 TransShiftMode 100;
BA_ "GenSigCycleTime" SG_ 662 TransShiftMode 100;
BA_ "GenSigSendType" SG_ 662 DriveModeTcu 7;
BA_ "GenSigCycleTimeActive" SG_ 662 DriveModeTcu 100;
BA_ "GenSigCycleTime" SG_ 662 DriveModeTcu 100;
BA_ "GenSigSendType" SG_ 662 GearShiftIndctnTcuStatus 7;
BA_ "GenSigCycleTimeActive" SG_ 662 GearShiftIndctnTcuStatus 100;
BA_ "GenSigCycleTime" SG_ 662 GearShiftIndctnTcuStatus 100;
BA_ "GenSigSendType" SG_ 662 TransServiceIndication 7;
BA_ "GenSigCycleTimeActive" SG_ 662 TransServiceIndication 100;
BA_ "GenSigCycleTime" SG_ 662 TransServiceIndication 100;
BA_ "GenSigSendType" SG_ 662 TcuErrMsgUserInfo 7;
BA_ "GenSigCycleTimeActive" SG_ 662 TcuErrMsgUserInfo 100;
BA_ "GenSigCycleTime" SG_ 662 TcuErrMsgUserInfo 100;
BA_ "GenSigSendType" SG_ 662 GearShiftIndctnTcu 7;
BA_ "GenSigCycleTimeActive" SG_ 662 GearShiftIndctnTcu 100;
BA_ "GenSigCycleTime" SG_ 662 GearShiftIndctnTcu 100;
BA_ "GenSigSendType" SG_ 662 ShifterLeverPos 7;
BA_ "GenSigCycleTimeActive" SG_ 662 ShifterLeverPos 100;
BA_ "GenSigCycleTime" SG_ 662 ShifterLeverPos 100;
BA_ "GenSigSendType" SG_ 662 ShifterLeverPosStatus 7;
BA_ "GenSigCycleTimeActive" SG_ 662 ShifterLeverPosStatus 100;
BA_ "GenSigCycleTime" SG_ 662 ShifterLeverPosStatus 100;
BA_ "GenSigStartValue" SG_ 664 TcuErrMsgUserInfoAT 7;
BA_ "GenSigSendType" SG_ 664 TcuErrMsgUserInfoAT 7;
BA_ "GenSigCycleTimeActive" SG_ 664 TcuErrMsgUserInfoAT 100;
BA_ "GenSigCycleTime" SG_ 664 TcuErrMsgUserInfoAT 100;
BA_ "GenSigSendType" SG_ 664 BuzzerRequestAT 7;
BA_ "GenSigCycleTimeActive" SG_ 664 BuzzerRequestAT 100;
BA_ "GenSigCycleTime" SG_ 664 BuzzerRequestAT 100;
BA_ "GenSigSendType" SG_ 664 TCUGSMWarningAT 7;
BA_ "GenSigCycleTimeActive" SG_ 664 TCUGSMWarningAT 100;
BA_ "GenSigCycleTime" SG_ 664 TCUGSMWarningAT 100;
BA_ "GenSigSendType" SG_ 664 TCUGSAPositionDisplayAT 7;
BA_ "GenSigCycleTimeActive" SG_ 664 TCUGSAPositionDisplayAT 100;
BA_ "GenSigCycleTime" SG_ 664 TCUGSAPositionDisplayAT 100;
BA_ "GenSigStartValue" SG_ 664 TrnOilTmp 40;
BA_ "GenSigSendType" SG_ 664 TrnOilTmp 7;
BA_ "GenSigCycleTimeActive" SG_ 664 TrnOilTmp 100;
BA_ "GenSigCycleTime" SG_ 664 TrnOilTmp 100;
BA_ "GenSigSendType" SG_ 664 TrnOilTmpStatus 7;
BA_ "GenSigCycleTimeActive" SG_ 664 TrnOilTmpStatus 100;
BA_ "GenSigCycleTime" SG_ 664 TrnOilTmpStatus 100;
BA_ "GenSigSendType" SG_ 664 TCUFault 7;
BA_ "GenSigCycleTimeActive" SG_ 664 TCUFault 100;
BA_ "GenSigCycleTime" SG_ 664 TCUFault 100;
BA_ "GenSigSendType" SG_ 664 DrShftCntrlReqDndIO 7;
BA_ "GenSigCycleTimeActive" SG_ 664 DrShftCntrlReqDndIO 100;
BA_ "GenSigCycleTime" SG_ 664 DrShftCntrlReqDndIO 100;
BA_ "GenSigSendType" SG_ 666 TCUGSMWarningDct 7;
BA_ "GenSigCycleTimeActive" SG_ 666 TCUGSMWarningDct 100;
BA_ "GenSigCycleTime" SG_ 666 TCUGSMWarningDct 100;
BA_ "GenSigSendType" SG_ 666 TCUGSAPositionDisplayDct 7;
BA_ "GenSigCycleTimeActive" SG_ 666 TCUGSAPositionDisplayDct 100;
BA_ "GenSigCycleTime" SG_ 666 TCUGSAPositionDisplayDct 100;
BA_ "GenSigStartValue" SG_ 666 TcuErrMsgUserInfoDCT 7;
BA_ "GenSigSendType" SG_ 666 TcuErrMsgUserInfoDCT 7;
BA_ "GenSigCycleTimeActive" SG_ 666 TcuErrMsgUserInfoDCT 100;
BA_ "GenSigCycleTime" SG_ 666 TcuErrMsgUserInfoDCT 100;
BA_ "GenSigSendType" SG_ 666 DrShftCntrlReqDndIODCT 7;
BA_ "GenSigCycleTimeActive" SG_ 666 DrShftCntrlReqDndIODCT 100;
BA_ "GenSigCycleTime" SG_ 666 DrShftCntrlReqDndIODCT 100;
BA_ "GenSigSendType" SG_ 666 TxmnOilSumpTempStatus 7;
BA_ "GenSigCycleTimeActive" SG_ 666 TxmnOilSumpTempStatus 100;
BA_ "GenSigCycleTime" SG_ 666 TxmnOilSumpTempStatus 100;
BA_ "GenSigStartValue" SG_ 666 TxmnOilSumpTemp 40;
BA_ "GenSigSendType" SG_ 666 TxmnOilSumpTemp 7;
BA_ "GenSigCycleTimeActive" SG_ 666 TxmnOilSumpTemp 100;
BA_ "GenSigCycleTime" SG_ 666 TxmnOilSumpTemp 100;
BA_ "GenSigSendType" SG_ 666 BuzzerRequestDct 7;
BA_ "GenSigCycleTimeActive" SG_ 666 BuzzerRequestDct 100;
BA_ "GenSigCycleTime" SG_ 666 BuzzerRequestDct 100;
BA_ "GenSigSendType" SG_ 666 TransServiceIndicationDCT 7;
BA_ "GenSigCycleTimeActive" SG_ 666 TransServiceIndicationDCT 100;
BA_ "GenSigCycleTime" SG_ 666 TransServiceIndicationDCT 100;
BA_ "GenSigTimeoutTime_HU_Mid_X451" SG_ 666 CoolingFanStateReq 0;
BA_ "GenSigTimeoutTime_HU_High_X451" SG_ 666 CoolingFanStateReq 0;
BA_ "GenSigTimeoutTime_HU_B" SG_ 666 CoolingFanStateReq 0;
BA_ "GenSigTimeoutTime_HU_A" SG_ 666 CoolingFanStateReq 0;
BA_ "GenSigTimeoutMsg_HU_Mid_X451" SG_ 666 CoolingFanStateReq 0;
BA_ "GenSigTimeoutMsg_HU_High_X451" SG_ 666 CoolingFanStateReq 0;
BA_ "GenSigTimeoutMsg_HU_B" SG_ 666 CoolingFanStateReq 0;
BA_ "GenSigTimeoutMsg_HU_A" SG_ 666 CoolingFanStateReq 0;
BA_ "GenSigSendType" SG_ 666 CoolingFanStateReq 7;
BA_ "GenSigCycleTimeActive" SG_ 666 CoolingFanStateReq 100;
BA_ "GenSigCycleTime" SG_ 666 CoolingFanStateReq 100;
BA_ "GenSigTimeoutTime_HU_Mid_X451" SG_ 666 ACCmprsrStateReq 0;
BA_ "GenSigTimeoutTime_HU_High_X451" SG_ 666 ACCmprsrStateReq 0;
BA_ "GenSigTimeoutTime_HU_B" SG_ 666 ACCmprsrStateReq 0;
BA_ "GenSigTimeoutTime_HU_A" SG_ 666 ACCmprsrStateReq 0;
BA_ "GenSigTimeoutMsg_HU_Mid_X451" SG_ 666 ACCmprsrStateReq 0;
BA_ "GenSigTimeoutMsg_HU_High_X451" SG_ 666 ACCmprsrStateReq 0;
BA_ "GenSigTimeoutMsg_HU_B" SG_ 666 ACCmprsrStateReq 0;
BA_ "GenSigTimeoutMsg_HU_A" SG_ 666 ACCmprsrStateReq 0;
BA_ "GenSigSendType" SG_ 666 ACCmprsrStateReq 7;
BA_ "GenSigCycleTimeActive" SG_ 666 ACCmprsrStateReq 100;
BA_ "GenSigCycleTime" SG_ 666 ACCmprsrStateReq 100;
BA_ "GenSigSendType" SG_ 666 GearShiftIndctnTcuDct 7;
BA_ "GenSigCycleTimeActive" SG_ 666 GearShiftIndctnTcuDct 100;
BA_ "GenSigCycleTime" SG_ 666 GearShiftIndctnTcuDct 100;
BA_ "GenSigSendType" SG_ 666 GearShiftIndctnTcuDctStatus 7;
BA_ "GenSigCycleTimeActive" SG_ 666 GearShiftIndctnTcuDctStatus 100;
BA_ "GenSigCycleTime" SG_ 666 GearShiftIndctnTcuDctStatus 100;
BA_ "GenSigSendType" SG_ 666 TxmnOverheated 7;
BA_ "GenSigCycleTimeActive" SG_ 666 TxmnOverheated 100;
BA_ "GenSigCycleTime" SG_ 666 TxmnOverheated 100;
BA_ "GenSigTimeoutTime_HU_Mid_X451" SG_ 666 InhibitStopStrt 0;
BA_ "GenSigTimeoutTime_HU_High_X451" SG_ 666 InhibitStopStrt 0;
BA_ "GenSigTimeoutTime_HU_B" SG_ 666 InhibitStopStrt 0;
BA_ "GenSigTimeoutTime_HU_A" SG_ 666 InhibitStopStrt 0;
BA_ "GenSigTimeoutMsg_HU_Mid_X451" SG_ 666 InhibitStopStrt 0;
BA_ "GenSigTimeoutMsg_HU_High_X451" SG_ 666 InhibitStopStrt 0;
BA_ "GenSigTimeoutMsg_HU_B" SG_ 666 InhibitStopStrt 0;
BA_ "GenSigTimeoutMsg_HU_A" SG_ 666 InhibitStopStrt 0;
BA_ "GenSigSendType" SG_ 666 InhibitStopStrt 7;
BA_ "GenSigCycleTimeActive" SG_ 666 InhibitStopStrt 100;
BA_ "GenSigCycleTime" SG_ 666 InhibitStopStrt 100;
BA_ "GenSigSendType" SG_ 666 GearForDisplayDctStatus 7;
BA_ "GenSigCycleTimeActive" SG_ 666 GearForDisplayDctStatus 100;
BA_ "GenSigCycleTime" SG_ 666 GearForDisplayDctStatus 100;
BA_ "GenSigSendType" SG_ 666 GearForDisplayDct 7;
BA_ "GenSigCycleTimeActive" SG_ 666 GearForDisplayDct 100;
BA_ "GenSigCycleTime" SG_ 666 GearForDisplayDct 100;
BA_ "GenSigSendType" SG_ 666 BrkPedalPressReq 7;
BA_ "GenSigCycleTimeActive" SG_ 666 BrkPedalPressReq 100;
BA_ "GenSigCycleTime" SG_ 666 BrkPedalPressReq 100;
BA_ "GenSigTimeoutTime_HU_Mid_X451" SG_ 666 TxmnMilReq 0;
BA_ "GenSigTimeoutTime_HU_High_X451" SG_ 666 TxmnMilReq 0;
BA_ "GenSigTimeoutTime_HU_B" SG_ 666 TxmnMilReq 0;
BA_ "GenSigTimeoutTime_HU_A" SG_ 666 TxmnMilReq 0;
BA_ "GenSigTimeoutMsg_HU_Mid_X451" SG_ 666 TxmnMilReq 0;
BA_ "GenSigTimeoutMsg_HU_High_X451" SG_ 666 TxmnMilReq 0;
BA_ "GenSigTimeoutMsg_HU_B" SG_ 666 TxmnMilReq 0;
BA_ "GenSigTimeoutMsg_HU_A" SG_ 666 TxmnMilReq 0;
BA_ "GenSigSendType" SG_ 666 TxmnMilReq 7;
BA_ "GenSigCycleTimeActive" SG_ 666 TxmnMilReq 100;
BA_ "GenSigCycleTime" SG_ 666 TxmnMilReq 100;
BA_ "GenSigTimeoutTime_HU_Mid_X451" SG_ 666 EngShutAuth 0;
BA_ "GenSigTimeoutTime_HU_High_X451" SG_ 666 EngShutAuth 0;
BA_ "GenSigTimeoutTime_HU_B" SG_ 666 EngShutAuth 0;
BA_ "GenSigTimeoutTime_HU_A" SG_ 666 EngShutAuth 0;
BA_ "GenSigTimeoutMsg_HU_Mid_X451" SG_ 666 EngShutAuth 0;
BA_ "GenSigTimeoutMsg_HU_High_X451" SG_ 666 EngShutAuth 0;
BA_ "GenSigTimeoutMsg_HU_B" SG_ 666 EngShutAuth 0;
BA_ "GenSigTimeoutMsg_HU_A" SG_ 666 EngShutAuth 0;
BA_ "GenSigSendType" SG_ 666 EngShutAuth 7;
BA_ "GenSigCycleTimeActive" SG_ 666 EngShutAuth 100;
BA_ "GenSigCycleTime" SG_ 666 EngShutAuth 100;
BA_ "GenSigTimeoutTime_HU_Mid_X451" SG_ 666 EngStopReqESS 0;
BA_ "GenSigTimeoutTime_HU_High_X451" SG_ 666 EngStopReqESS 0;
BA_ "GenSigTimeoutTime_HU_B" SG_ 666 EngStopReqESS 0;
BA_ "GenSigTimeoutTime_HU_A" SG_ 666 EngStopReqESS 0;
BA_ "GenSigTimeoutMsg_HU_Mid_X451" SG_ 666 EngStopReqESS 0;
BA_ "GenSigTimeoutMsg_HU_High_X451" SG_ 666 EngStopReqESS 0;
BA_ "GenSigTimeoutMsg_HU_B" SG_ 666 EngStopReqESS 0;
BA_ "GenSigTimeoutMsg_HU_A" SG_ 666 EngStopReqESS 0;
BA_ "GenSigSendType" SG_ 666 EngStopReqESS 7;
BA_ "GenSigCycleTimeActive" SG_ 666 EngStopReqESS 100;
BA_ "GenSigCycleTime" SG_ 666 EngStopReqESS 100;
BA_ "GenSigTimeoutTime_HU_Mid_X451" SG_ 666 EngRestrtReq 0;
BA_ "GenSigTimeoutTime_HU_High_X451" SG_ 666 EngRestrtReq 0;
BA_ "GenSigTimeoutTime_HU_B" SG_ 666 EngRestrtReq 0;
BA_ "GenSigTimeoutTime_HU_A" SG_ 666 EngRestrtReq 0;
BA_ "GenSigTimeoutMsg_HU_Mid_X451" SG_ 666 EngRestrtReq 0;
BA_ "GenSigTimeoutMsg_HU_High_X451" SG_ 666 EngRestrtReq 0;
BA_ "GenSigTimeoutMsg_HU_B" SG_ 666 EngRestrtReq 0;
BA_ "GenSigTimeoutMsg_HU_A" SG_ 666 EngRestrtReq 0;
BA_ "GenSigSendType" SG_ 666 EngRestrtReq 7;
BA_ "GenSigCycleTimeActive" SG_ 666 EngRestrtReq 100;
BA_ "GenSigCycleTime" SG_ 666 EngRestrtReq 100;
BA_ "GenSigSendType" SG_ 693 iTPMsResetStatus 7;
BA_ "GenSigCycleTimeActive" SG_ 693 iTPMsResetStatus 100;
BA_ "GenSigCycleTime" SG_ 693 iTPMsResetStatus 100;
BA_ "GenSigSendType" SG_ 693 iTPMsReset 7;
BA_ "GenSigCycleTimeActive" SG_ 693 iTPMsReset 100;
BA_ "GenSigCycleTime" SG_ 693 iTPMsReset 100;
BA_ "GenSigSendType" SG_ 693 HvBattSoCColor 7;
BA_ "GenSigCycleTimeActive" SG_ 693 HvBattSoCColor 100;
BA_ "GenSigCycleTime" SG_ 693 HvBattSoCColor 100;
BA_ "GenSigStartValue" SG_ 693 OATICSig 80;
BA_ "GenSigSendType" SG_ 693 OATICSig 7;
BA_ "GenSigCycleTimeActive" SG_ 693 OATICSig 100;
BA_ "GenSigCycleTime" SG_ 693 OATICSig 100;
BA_ "GenSigSendType" SG_ 693 BattVoltIPC 7;
BA_ "GenSigCycleTimeActive" SG_ 693 BattVoltIPC 100;
BA_ "GenSigCycleTime" SG_ 693 BattVoltIPC 100;
BA_ "GenSigSendType" SG_ 693 LowFuelOutputICStatus 7;
BA_ "GenSigCycleTimeActive" SG_ 693 LowFuelOutputICStatus 100;
BA_ "GenSigCycleTime" SG_ 693 LowFuelOutputICStatus 100;
BA_ "GenSigSendType" SG_ 693 LowFuelOutputIC 7;
BA_ "GenSigCycleTimeActive" SG_ 693 LowFuelOutputIC 100;
BA_ "GenSigCycleTime" SG_ 693 LowFuelOutputIC 100;
BA_ "GenSigStartValue" SG_ 693 ParkBrkState 1;
BA_ "GenSigSendType" SG_ 693 ParkBrkState 7;
BA_ "GenSigCycleTimeActive" SG_ 693 ParkBrkState 100;
BA_ "GenSigCycleTime" SG_ 693 ParkBrkState 100;
BA_ "GenSigSendType" SG_ 693 IcPlatformVariant 7;
BA_ "GenSigCycleTimeActive" SG_ 693 IcPlatformVariant 100;
BA_ "GenSigCycleTime" SG_ 693 IcPlatformVariant 100;
BA_ "GenSigStartValue" SG_ 693 OATICSigStatus 2;
BA_ "GenSigSendType" SG_ 693 OATICSigStatus 7;
BA_ "GenSigCycleTimeActive" SG_ 693 OATICSigStatus 100;
BA_ "GenSigCycleTime" SG_ 693 OATICSigStatus 100;
BA_ "GenSigSendType" SG_ 693 IcPresence 7;
BA_ "GenSigCycleTimeActive" SG_ 693 IcPresence 100;
BA_ "GenSigCycleTime" SG_ 693 IcPresence 100;
BA_ "GenSigSendType" SG_ 693 SRSWarningLampStatus 7;
BA_ "GenSigCycleTimeActive" SG_ 693 SRSWarningLampStatus 100;
BA_ "GenSigCycleTime" SG_ 693 SRSWarningLampStatus 100;
BA_ "GenSigSendType" SG_ 693 VsSPulseCountSigStatus 7;
BA_ "GenSigCycleTimeActive" SG_ 693 VsSPulseCountSigStatus 100;
BA_ "GenSigCycleTime" SG_ 693 VsSPulseCountSigStatus 100;
BA_ "GenSigSendType" SG_ 693 VsSPulseCountSig 7;
BA_ "GenSigCycleTimeActive" SG_ 693 VsSPulseCountSig 100;
BA_ "GenSigCycleTime" SG_ 693 VsSPulseCountSig 100;
BA_ "GenSigSendType" SG_ 693 IcHuVoiceAlertState 7;
BA_ "GenSigCycleTimeActive" SG_ 693 IcHuVoiceAlertState 100;
BA_ "GenSigCycleTime" SG_ 693 IcHuVoiceAlertState 100;
BA_ "GenSigSendType" SG_ 693 IcHuVoiceAlertStateStatus 7;
BA_ "GenSigCycleTimeActive" SG_ 693 IcHuVoiceAlertStateStatus 100;
BA_ "GenSigCycleTime" SG_ 693 IcHuVoiceAlertStateStatus 100;
BA_ "GenSigSendType" SG_ 693 ICCurDriveModeSig 7;
BA_ "GenSigCycleTimeActive" SG_ 693 ICCurDriveModeSig 100;
BA_ "GenSigCycleTime" SG_ 693 ICCurDriveModeSig 100;
BA_ "GenSigSendType" SG_ 693 IcHuCarImageSelection 7;
BA_ "GenSigCycleTimeActive" SG_ 693 IcHuCarImageSelection 100;
BA_ "GenSigCycleTime" SG_ 693 IcHuCarImageSelection 100;
BA_ "GenSigSendType" SG_ 693 IcSbDispReq 7;
BA_ "GenSigCycleTimeActive" SG_ 693 IcSbDispReq 100;
BA_ "GenSigCycleTime" SG_ 693 IcSbDispReq 100;
BA_ "GenSigSendType" SG_ 693 IcSbrDrvrSeatBeltSwitchStatus 7;
BA_ "GenSigCycleTimeActive" SG_ 693 IcSbrDrvrSeatBeltSwitchStatus 100;
BA_ "GenSigCycleTime" SG_ 693 IcSbrDrvrSeatBeltSwitchStatus 100;
BA_ "GenSigSendType" SG_ 695 RefuelAlert 7;
BA_ "GenSigCycleTimeActive" SG_ 695 RefuelAlert 100;
BA_ "GenSigCycleTime" SG_ 695 RefuelAlert 100;
BA_ "GenSigSendType" SG_ 695 IcHuTripAInfo 7;
BA_ "GenSigCycleTimeActive" SG_ 695 IcHuTripAInfo 100;
BA_ "GenSigCycleTime" SG_ 695 IcHuTripAInfo 100;
BA_ "GenSigSendType" SG_ 695 IcHuDrvrSeatBeltInfo 7;
BA_ "GenSigCycleTimeActive" SG_ 695 IcHuDrvrSeatBeltInfo 100;
BA_ "GenSigCycleTime" SG_ 695 IcHuDrvrSeatBeltInfo 100;
BA_ "GenSigSendType" SG_ 695 IcHuTripBInfo 7;
BA_ "GenSigCycleTimeActive" SG_ 695 IcHuTripBInfo 100;
BA_ "GenSigCycleTime" SG_ 695 IcHuTripBInfo 100;
BA_ "GenSigSendType" SG_ 695 IcHuDTeInfo 7;
BA_ "GenSigCycleTimeActive" SG_ 695 IcHuDTeInfo 100;
BA_ "GenSigCycleTime" SG_ 695 IcHuDTeInfo 100;
BA_ "GenSigSendType" SG_ 695 IcHuVehRegion 7;
BA_ "GenSigCycleTimeActive" SG_ 695 IcHuVehRegion 100;
BA_ "GenSigCycleTime" SG_ 695 IcHuVehRegion 100;
BA_ "GenSigSendType" SG_ 695 IcHuTyreSize 7;
BA_ "GenSigCycleTimeActive" SG_ 695 IcHuTyreSize 100;
BA_ "GenSigCycleTime" SG_ 695 IcHuTyreSize 100;
BA_ "GenSigSendType" SG_ 695 RevGearIPC 7;
BA_ "GenSigCycleTimeActive" SG_ 695 RevGearIPC 100;
BA_ "GenSigCycleTime" SG_ 695 RevGearIPC 100;
BA_ "GenSigSendType" SG_ 695 IcHuFuelVolumeInfoPercen 7;
BA_ "GenSigCycleTimeActive" SG_ 695 IcHuFuelVolumeInfoPercen 100;
BA_ "GenSigCycleTime" SG_ 695 IcHuFuelVolumeInfoPercen 100;
BA_ "GenSigSendType" SG_ 695 RevGearIPCStatus 7;
BA_ "GenSigCycleTimeActive" SG_ 695 RevGearIPCStatus 100;
BA_ "GenSigCycleTime" SG_ 695 RevGearIPCStatus 100;
BA_ "GenSigSendType" SG_ 697 IcHuOnBoardCompState 7;
BA_ "GenSigCycleTimeActive" SG_ 697 IcHuOnBoardCompState 100;
BA_ "GenSigCycleTime" SG_ 697 IcHuOnBoardCompState 100;
BA_ "GenSigSendType" SG_ 697 IcHuIcInfoFeaturePresenceAck 7;
BA_ "GenSigCycleTimeActive" SG_ 697 IcHuIcInfoFeaturePresenceAck 100;
BA_ "GenSigCycleTime" SG_ 697 IcHuIcInfoFeaturePresenceAck 100;
BA_ "GenSigSendType" SG_ 697 IcHuAlertType 7;
BA_ "GenSigCycleTimeActive" SG_ 697 IcHuAlertType 100;
BA_ "GenSigCycleTime" SG_ 697 IcHuAlertType 100;
BA_ "GenSigSendType" SG_ 697 IcHuAlertStateStatus 7;
BA_ "GenSigCycleTimeActive" SG_ 697 IcHuAlertStateStatus 100;
BA_ "GenSigCycleTime" SG_ 697 IcHuAlertStateStatus 100;
BA_ "GenSigSendType" SG_ 697 IcHuAlertState 7;
BA_ "GenSigCycleTimeActive" SG_ 697 IcHuAlertState 100;
BA_ "GenSigCycleTime" SG_ 697 IcHuAlertState 100;
BA_ "GenSigSendType" SG_ 697 DriveAlert1_TeaBreak 7;
BA_ "GenSigCycleTimeActive" SG_ 697 DriveAlert1_TeaBreak 100;
BA_ "GenSigCycleTime" SG_ 697 DriveAlert1_TeaBreak 100;
BA_ "GenSigSendType" SG_ 697 IcHuAverFuelEconTripA 7;
BA_ "GenSigCycleTimeActive" SG_ 697 IcHuAverFuelEconTripA 100;
BA_ "GenSigCycleTime" SG_ 697 IcHuAverFuelEconTripA 100;
BA_ "GenSigSendType" SG_ 697 IcHuAverFuelEconTripB 7;
BA_ "GenSigCycleTimeActive" SG_ 697 IcHuAverFuelEconTripB 100;
BA_ "GenSigCycleTime" SG_ 697 IcHuAverFuelEconTripB 100;
BA_ "GenSigSendType" SG_ 697 IcHuFuelTankCapacity 7;
BA_ "GenSigCycleTimeActive" SG_ 697 IcHuFuelTankCapacity 100;
BA_ "GenSigCycleTime" SG_ 697 IcHuFuelTankCapacity 100;
BA_ "GenSigSendType" SG_ 697 IcHuFuelVolumeInfoLtrs 7;
BA_ "GenSigCycleTimeActive" SG_ 697 IcHuFuelVolumeInfoLtrs 100;
BA_ "GenSigCycleTime" SG_ 697 IcHuFuelVolumeInfoLtrs 100;
BA_ "GenSigSendType" SG_ 697 IcHuInstFuelEcoInfo 7;
BA_ "GenSigCycleTimeActive" SG_ 697 IcHuInstFuelEcoInfo 100;
BA_ "GenSigCycleTime" SG_ 697 IcHuInstFuelEcoInfo 100;
BA_ "GenSigSendType" SG_ 697 IcHuResetTripB 7;
BA_ "GenSigCycleTimeActive" SG_ 697 IcHuResetTripB 100;
BA_ "GenSigCycleTime" SG_ 697 IcHuResetTripB 100;
BA_ "GenSigSendType" SG_ 697 IcHuResetTripA 7;
BA_ "GenSigCycleTimeActive" SG_ 697 IcHuResetTripA 100;
BA_ "GenSigCycleTime" SG_ 697 IcHuResetTripA 100;
BA_ "GenSigStartValue" SG_ 697 IcHuDriveType 1;
BA_ "GenSigSendType" SG_ 697 IcHuDriveType 7;
BA_ "GenSigCycleTimeActive" SG_ 697 IcHuDriveType 100;
BA_ "GenSigCycleTime" SG_ 697 IcHuDriveType 100;
BA_ "GenSigSendType" SG_ 698 IllumDimLvlSetting 7;
BA_ "GenSigCycleTimeActive" SG_ 698 IllumDimLvlSetting 100;
BA_ "GenSigCycleTime" SG_ 698 IllumDimLvlSetting 100;
BA_ "GenSigStartValue" SG_ 698 IllumDimLvlSettingStatus 3;
BA_ "GenSigSendType" SG_ 698 IllumDimLvlSettingStatus 7;
BA_ "GenSigCycleTimeActive" SG_ 698 IllumDimLvlSettingStatus 100;
BA_ "GenSigCycleTime" SG_ 698 IllumDimLvlSettingStatus 100;
BA_ "GenSigSendType" SG_ 698 SwitchDimmingControlIPC 7;
BA_ "GenSigCycleTimeActive" SG_ 698 SwitchDimmingControlIPC 100;
BA_ "GenSigCycleTime" SG_ 698 SwitchDimmingControlIPC 100;
BA_ "GenSigStartValue" SG_ 698 IllumOnOffCtrlStatus 3;
BA_ "GenSigSendType" SG_ 698 IllumOnOffCtrlStatus 7;
BA_ "GenSigCycleTimeActive" SG_ 698 IllumOnOffCtrlStatus 100;
BA_ "GenSigCycleTime" SG_ 698 IllumOnOffCtrlStatus 100;
BA_ "GenSigSendType" SG_ 698 IllumOnOffCtrl 7;
BA_ "GenSigCycleTimeActive" SG_ 698 IllumOnOffCtrl 100;
BA_ "GenSigCycleTime" SG_ 698 IllumOnOffCtrl 100;
BA_ "GenSigStartValue" SG_ 698 SwitchDimmingControlIPCStatus 3;
BA_ "GenSigSendType" SG_ 698 SwitchDimmingControlIPCStatus 7;
BA_ "GenSigCycleTimeActive" SG_ 698 SwitchDimmingControlIPCStatus 100;
BA_ "GenSigCycleTime" SG_ 698 SwitchDimmingControlIPCStatus 100;
BA_ "GenSigSendType" SG_ 699 CruiseSpeedChangeStateIPC 7;
BA_ "GenSigCycleTimeActive" SG_ 699 CruiseSpeedChangeStateIPC 100;
BA_ "GenSigCycleTime" SG_ 699 CruiseSpeedChangeStateIPC 100;
BA_ "GenSigSendType" SG_ 699 CruiseSwitchSelStatusIPC 7;
BA_ "GenSigCycleTimeActive" SG_ 699 CruiseSwitchSelStatusIPC 100;
BA_ "GenSigCycleTime" SG_ 699 CruiseSwitchSelStatusIPC 100;
BA_ "GenSigSendType" SG_ 699 CruiseSwitchSelStateIPC 7;
BA_ "GenSigCycleTimeActive" SG_ 699 CruiseSwitchSelStateIPC 100;
BA_ "GenSigCycleTime" SG_ 699 CruiseSwitchSelStateIPC 100;
BA_ "GenSigSendType" SG_ 699 RegenSelectionSwStateIPC 7;
BA_ "GenSigCycleTimeActive" SG_ 699 RegenSelectionSwStateIPC 100;
BA_ "GenSigCycleTime" SG_ 699 RegenSelectionSwStateIPC 100;
BA_ "GenSigSendType" SG_ 699 RegenSelectionSwStatusIPC 7;
BA_ "GenSigCycleTimeActive" SG_ 699 RegenSelectionSwStatusIPC 100;
BA_ "GenSigCycleTime" SG_ 699 RegenSelectionSwStatusIPC 100;
BA_ "GenSigSendType" SG_ 699 IcHuTripAInfofull 7;
BA_ "GenSigCycleTimeActive" SG_ 699 IcHuTripAInfofull 100;
BA_ "GenSigCycleTime" SG_ 699 IcHuTripAInfofull 100;
BA_ "GenSigSendType" SG_ 699 IcHuTripBInfofull 7;
BA_ "GenSigCycleTimeActive" SG_ 699 IcHuTripBInfofull 100;
BA_ "GenSigCycleTime" SG_ 699 IcHuTripBInfofull 100;
BA_ "GenSigSendType" SG_ 700 IPCRemoteCheckStatus 7;
BA_ "GenSigCycleTimeActive" SG_ 700 IPCRemoteCheckStatus 100;
BA_ "GenSigCycleTime" SG_ 700 IPCRemoteCheckStatus 100;
BA_ "GenSigSendType" SG_ 700 IPCRemoteCheck 7;
BA_ "GenSigCycleTimeActive" SG_ 700 IPCRemoteCheck 100;
BA_ "GenSigCycleTime" SG_ 700 IPCRemoteCheck 100;
BA_ "GenSigSendType" SG_ 700 IcHuServReminderDays 7;
BA_ "GenSigCycleTimeActive" SG_ 700 IcHuServReminderDays 100;
BA_ "GenSigCycleTime" SG_ 700 IcHuServReminderDays 100;
BA_ "GenSigSendType" SG_ 700 IcHuServReminderKm 7;
BA_ "GenSigCycleTimeActive" SG_ 700 IcHuServReminderKm 100;
BA_ "GenSigCycleTime" SG_ 700 IcHuServReminderKm 100;
BA_ "GenSigSendType" SG_ 700 IcHuIceState 7;
BA_ "GenSigCycleTimeActive" SG_ 700 IcHuIceState 100;
BA_ "GenSigCycleTime" SG_ 700 IcHuIceState 100;
BA_ "GenSigSendType" SG_ 700 IcHuBrakeFluidLowState 7;
BA_ "GenSigCycleTimeActive" SG_ 700 IcHuBrakeFluidLowState 100;
BA_ "GenSigCycleTime" SG_ 700 IcHuBrakeFluidLowState 100;
BA_ "GenSigSendType" SG_ 700 IcHuFastenSeatBeltState 7;
BA_ "GenSigCycleTimeActive" SG_ 700 IcHuFastenSeatBeltState 100;
BA_ "GenSigCycleTime" SG_ 700 IcHuFastenSeatBeltState 100;
BA_ "GenSigSendType" SG_ 700 IcHuEngSystemFaultState 7;
BA_ "GenSigCycleTimeActive" SG_ 700 IcHuEngSystemFaultState 100;
BA_ "GenSigCycleTime" SG_ 700 IcHuEngSystemFaultState 100;
BA_ "GenSigSendType" SG_ 700 IcHuEngRestrictedPerformanceStat 7;
BA_ "GenSigCycleTimeActive" SG_ 700 IcHuEngRestrictedPerformanceStat 100;
BA_ "GenSigCycleTime" SG_ 700 IcHuEngRestrictedPerformanceStat 100;
BA_ "SystemSignalLongSymbol" SG_ 700 IcHuEngRestrictedPerformanceStat "IcHuEngRestrictedPerformanceState";
BA_ "GenSigSendType" SG_ 700 IcHuBatteryChargingState 7;
BA_ "GenSigCycleTimeActive" SG_ 700 IcHuBatteryChargingState 100;
BA_ "GenSigCycleTime" SG_ 700 IcHuBatteryChargingState 100;
BA_ "GenSigSendType" SG_ 700 IcHuFuelLevelLowState 7;
BA_ "GenSigCycleTimeActive" SG_ 700 IcHuFuelLevelLowState 100;
BA_ "GenSigCycleTime" SG_ 700 IcHuFuelLevelLowState 100;
BA_ "GenSigSendType" SG_ 700 IcHuEngineOilPressureLowState 7;
BA_ "GenSigCycleTimeActive" SG_ 700 IcHuEngineOilPressureLowState 100;
BA_ "GenSigCycleTime" SG_ 700 IcHuEngineOilPressureLowState 100;
BA_ "GenSigSendType" SG_ 700 NextServDueAlert 7;
BA_ "GenSigCycleTimeActive" SG_ 700 NextServDueAlert 100;
BA_ "GenSigCycleTime" SG_ 700 NextServDueAlert 100;
BA_ "GenSigSendType" SG_ 700 NextServDueAlertStatus 7;
BA_ "GenSigCycleTimeActive" SG_ 700 NextServDueAlertStatus 100;
BA_ "GenSigCycleTime" SG_ 700 NextServDueAlertStatus 100;
BA_ "GenSigSendType" SG_ 700 IcHuServReminderDaysfull 7;
BA_ "GenSigCycleTimeActive" SG_ 700 IcHuServReminderDaysfull 100;
BA_ "GenSigCycleTime" SG_ 700 IcHuServReminderDaysfull 100;
BA_ "GenSigSendType" SG_ 702 IcHuIFEHistogramInfo1 7;
BA_ "GenSigCycleTimeActive" SG_ 702 IcHuIFEHistogramInfo1 100;
BA_ "GenSigCycleTime" SG_ 702 IcHuIFEHistogramInfo1 100;
BA_ "GenSigSendType" SG_ 702 IcHuIFEHistogramInfo2 7;
BA_ "GenSigCycleTimeActive" SG_ 702 IcHuIFEHistogramInfo2 100;
BA_ "GenSigCycleTime" SG_ 702 IcHuIFEHistogramInfo2 100;
BA_ "GenSigSendType" SG_ 702 IcHuIFEHistogramInfo4 7;
BA_ "GenSigCycleTimeActive" SG_ 702 IcHuIFEHistogramInfo4 100;
BA_ "GenSigCycleTime" SG_ 702 IcHuIFEHistogramInfo4 100;
BA_ "GenSigSendType" SG_ 702 IcHuIFEHistogramInfo3 7;
BA_ "GenSigCycleTimeActive" SG_ 702 IcHuIFEHistogramInfo3 100;
BA_ "GenSigCycleTime" SG_ 702 IcHuIFEHistogramInfo3 100;
BA_ "GenSigSendType" SG_ 702 IcHuIFEHistogramInfo5 7;
BA_ "GenSigCycleTimeActive" SG_ 702 IcHuIFEHistogramInfo5 100;
BA_ "GenSigCycleTime" SG_ 702 IcHuIFEHistogramInfo5 100;
BA_ "GenSigSendType" SG_ 702 IcHuOnBoardCompState 7;
BA_ "GenSigCycleTimeActive" SG_ 702 IcHuOnBoardCompState 100;
BA_ "GenSigCycleTime" SG_ 702 IcHuOnBoardCompState 100;
BA_ "GenSigSendType" SG_ 702 IcHuIcInfoFeaturePresenceAck 7;
BA_ "GenSigCycleTimeActive" SG_ 702 IcHuIcInfoFeaturePresenceAck 100;
BA_ "GenSigCycleTime" SG_ 702 IcHuIcInfoFeaturePresenceAck 100;
BA_ "GenSigSendType" SG_ 702 IcHuAlertStateStatus 7;
BA_ "GenSigCycleTimeActive" SG_ 702 IcHuAlertStateStatus 100;
BA_ "GenSigCycleTime" SG_ 702 IcHuAlertStateStatus 100;
BA_ "GenSigSendType" SG_ 702 IcHuAlertType 7;
BA_ "GenSigCycleTimeActive" SG_ 702 IcHuAlertType 100;
BA_ "GenSigCycleTime" SG_ 702 IcHuAlertType 100;
BA_ "GenSigSendType" SG_ 702 DriveAlert1_TeaBreak 7;
BA_ "GenSigCycleTimeActive" SG_ 702 DriveAlert1_TeaBreak 100;
BA_ "GenSigCycleTime" SG_ 702 DriveAlert1_TeaBreak 100;
BA_ "GenSigSendType" SG_ 702 IcHuAlertState 7;
BA_ "GenSigCycleTimeActive" SG_ 702 IcHuAlertState 100;
BA_ "GenSigCycleTime" SG_ 702 IcHuAlertState 100;
BA_ "GenSigSendType" SG_ 704 GpsCompassPresence 7;
BA_ "GenSigCycleTimeActive" SG_ 704 GpsCompassPresence 100;
BA_ "GenSigCycleTime" SG_ 704 GpsCompassPresence 100;
BA_ "GenSigSendType" SG_ 704 GPsCourseInfoIVI 7;
BA_ "GenSigCycleTimeActive" SG_ 704 GPsCourseInfoIVI 100;
BA_ "GenSigCycleTime" SG_ 704 GPsCourseInfoIVI 100;
BA_ "GenSigSendType" SG_ 704 GPsCourseInfoStatusIVI 7;
BA_ "GenSigCycleTimeActive" SG_ 704 GPsCourseInfoStatusIVI 100;
BA_ "GenSigCycleTime" SG_ 704 GPsCourseInfoStatusIVI 100;
BA_ "GenSigSendType" SG_ 704 HuEMsRegenReqStatus 7;
BA_ "GenSigCycleTimeActive" SG_ 704 HuEMsRegenReqStatus 100;
BA_ "GenSigCycleTime" SG_ 704 HuEMsRegenReqStatus 100;
BA_ "GenSigSendType" SG_ 704 HuEMsRegenReq 7;
BA_ "GenSigCycleTimeActive" SG_ 704 HuEMsRegenReq 100;
BA_ "GenSigCycleTime" SG_ 704 HuEMsRegenReq 100;
BA_ "GenSigSendType" SG_ 704 HuCcmRearBlwrOnOffReq 7;
BA_ "GenSigCycleTimeActive" SG_ 704 HuCcmRearBlwrOnOffReq 100;
BA_ "GenSigCycleTime" SG_ 704 HuCcmRearBlwrOnOffReq 100;
BA_ "GenSigSendType" SG_ 704 StuckModeUserResponse 7;
BA_ "GenSigCycleTimeActive" SG_ 704 StuckModeUserResponse 100;
BA_ "GenSigCycleTime" SG_ 704 StuckModeUserResponse 100;
BA_ "GenSigSendType" SG_ 704 HuIcDistanceDisplayUnitEnum 7;
BA_ "GenSigCycleTimeActive" SG_ 704 HuIcDistanceDisplayUnitEnum 100;
BA_ "GenSigCycleTime" SG_ 704 HuIcDistanceDisplayUnitEnum 100;
BA_ "GenSigSendType" SG_ 704 HuPresence 7;
BA_ "GenSigCycleTimeActive" SG_ 704 HuPresence 100;
BA_ "GenSigCycleTime" SG_ 704 HuPresence 100;
BA_ "GenSigSendType" SG_ 704 HuPlatformVariant 7;
BA_ "GenSigCycleTimeActive" SG_ 704 HuPlatformVariant 100;
BA_ "GenSigCycleTime" SG_ 704 HuPlatformVariant 100;
BA_ "GenSigSendType" SG_ 704 BattVolt_HU 7;
BA_ "GenSigCycleTimeActive" SG_ 704 BattVolt_HU 100;
BA_ "GenSigCycleTime" SG_ 704 BattVolt_HU 100;
BA_ "GenSigSendType" SG_ 704 SbIcDispState 7;
BA_ "GenSigCycleTimeActive" SG_ 704 SbIcDispState 100;
BA_ "GenSigCycleTime" SG_ 704 SbIcDispState 100;
BA_ "GenSigSendType" SG_ 704 TpmsEnterLearning 7;
BA_ "GenSigCycleTimeActive" SG_ 704 TpmsEnterLearning 100;
BA_ "GenSigCycleTime" SG_ 704 TpmsEnterLearning 100;
BA_ "GenSigSendType" SG_ 704 HuIcAlertStatusAck 7;
BA_ "GenSigCycleTimeActive" SG_ 704 HuIcAlertStatusAck 100;
BA_ "GenSigCycleTime" SG_ 704 HuIcAlertStatusAck 100;
BA_ "GenSigSendType" SG_ 704 HuIcAlertStateAck 7;
BA_ "GenSigCycleTimeActive" SG_ 704 HuIcAlertStateAck 100;
BA_ "GenSigCycleTime" SG_ 704 HuIcAlertStateAck 100;
BA_ "GenSigSendType" SG_ 706 HuIcNaviSource 7;
BA_ "GenSigCycleTimeActive" SG_ 706 HuIcNaviSource 100;
BA_ "GenSigCycleTime" SG_ 706 HuIcNaviSource 100;
BA_ "GenSigSendType" SG_ 706 HuIcCarPlayManeuverType 7;
BA_ "GenSigCycleTimeActive" SG_ 706 HuIcCarPlayManeuverType 100;
BA_ "GenSigCycleTime" SG_ 706 HuIcCarPlayManeuverType 100;
BA_ "GenSigSendType" SG_ 706 HuIcNextTurnDistance 7;
BA_ "GenSigCycleTimeActive" SG_ 706 HuIcNextTurnDistance 100;
BA_ "GenSigCycleTime" SG_ 706 HuIcNextTurnDistance 100;
BA_ "GenSigSendType" SG_ 706 HuIcNextTurnEstimateSec 7;
BA_ "GenSigCycleTimeActive" SG_ 706 HuIcNextTurnEstimateSec 100;
BA_ "GenSigCycleTime" SG_ 706 HuIcNextTurnEstimateSec 100;
BA_ "GenSigSendType" SG_ 706 HuIcNextTurnRoundDist 7;
BA_ "GenSigCycleTimeActive" SG_ 706 HuIcNextTurnRoundDist 100;
BA_ "GenSigCycleTime" SG_ 706 HuIcNextTurnRoundDist 100;
BA_ "GenSigSendType" SG_ 706 HuIcNextTurnEstimateMin 7;
BA_ "GenSigCycleTimeActive" SG_ 706 HuIcNextTurnEstimateMin 100;
BA_ "GenSigCycleTime" SG_ 706 HuIcNextTurnEstimateMin 100;
BA_ "GenSigSendType" SG_ 706 HuIcNextTurnSideEnum 7;
BA_ "GenSigCycleTimeActive" SG_ 706 HuIcNextTurnSideEnum 100;
BA_ "GenSigCycleTime" SG_ 706 HuIcNextTurnSideEnum 100;
BA_ "GenSigSendType" SG_ 706 HuIcNextTurnEstimateHrs 7;
BA_ "GenSigCycleTimeActive" SG_ 706 HuIcNextTurnEstimateHrs 100;
BA_ "GenSigCycleTime" SG_ 706 HuIcNextTurnEstimateHrs 100;
BA_ "GenSigSendType" SG_ 706 HuIcNextTurnRoundDistUnits 7;
BA_ "GenSigCycleTimeActive" SG_ 706 HuIcNextTurnRoundDistUnits 100;
BA_ "GenSigCycleTime" SG_ 706 HuIcNextTurnRoundDistUnits 100;
BA_ "GenSigSendType" SG_ 706 HuIcNaviStatus 7;
BA_ "GenSigCycleTimeActive" SG_ 706 HuIcNaviStatus 100;
BA_ "GenSigCycleTime" SG_ 706 HuIcNaviStatus 100;
BA_ "GenSigSendType" SG_ 706 HuIcNextTurnSide 7;
BA_ "GenSigCycleTimeActive" SG_ 706 HuIcNextTurnSide 100;
BA_ "GenSigCycleTime" SG_ 706 HuIcNextTurnSide 100;
BA_ "GenSigSendType" SG_ 706 HuIcRoundAboutType 7;
BA_ "GenSigCycleTimeActive" SG_ 706 HuIcRoundAboutType 100;
BA_ "GenSigCycleTime" SG_ 706 HuIcRoundAboutType 100;
BA_ "GenSigSendType" SG_ 706 HuIcColorStatus 7;
BA_ "GenSigCycleTimeActive" SG_ 706 HuIcColorStatus 100;
BA_ "GenSigCycleTime" SG_ 706 HuIcColorStatus 100;
BA_ "GenSigSendType" SG_ 707 LinSwcSbPowerModeCan 7;
BA_ "GenSigCycleTimeActive" SG_ 707 LinSwcSbPowerModeCan 100;
BA_ "GenSigCycleTime" SG_ 707 LinSwcSbPowerModeCan 100;
BA_ "GenSigSendType" SG_ 707 LinSwcIcKey9Can 7;
BA_ "GenSigCycleTimeActive" SG_ 707 LinSwcIcKey9Can 100;
BA_ "GenSigCycleTime" SG_ 707 LinSwcIcKey9Can 100;
BA_ "GenSigSendType" SG_ 707 LinSwcIcKey8Can 7;
BA_ "GenSigCycleTimeActive" SG_ 707 LinSwcIcKey8Can 100;
BA_ "GenSigCycleTime" SG_ 707 LinSwcIcKey8Can 100;
BA_ "GenSigSendType" SG_ 707 LinSwcIcKey7Can 7;
BA_ "GenSigCycleTimeActive" SG_ 707 LinSwcIcKey7Can 100;
BA_ "GenSigCycleTime" SG_ 707 LinSwcIcKey7Can 100;
BA_ "GenSigSendType" SG_ 707 LinSwcIcKey6Can 7;
BA_ "GenSigCycleTimeActive" SG_ 707 LinSwcIcKey6Can 100;
BA_ "GenSigCycleTime" SG_ 707 LinSwcIcKey6Can 100;
BA_ "GenSigSendType" SG_ 707 LinSwcIcViewCan 7;
BA_ "GenSigCycleTimeActive" SG_ 707 LinSwcIcViewCan 100;
BA_ "GenSigCycleTime" SG_ 707 LinSwcIcViewCan 100;
BA_ "GenSigSendType" SG_ 707 LinSwcIcMenuSelectCan 7;
BA_ "GenSigCycleTimeActive" SG_ 707 LinSwcIcMenuSelectCan 100;
BA_ "GenSigCycleTime" SG_ 707 LinSwcIcMenuSelectCan 100;
BA_ "GenSigSendType" SG_ 707 LinSwcIcMenuDownCan 7;
BA_ "GenSigCycleTimeActive" SG_ 707 LinSwcIcMenuDownCan 100;
BA_ "GenSigCycleTime" SG_ 707 LinSwcIcMenuDownCan 100;
BA_ "GenSigSendType" SG_ 707 LinSwcIcMenuUpCan 7;
BA_ "GenSigCycleTimeActive" SG_ 707 LinSwcIcMenuUpCan 100;
BA_ "GenSigCycleTime" SG_ 707 LinSwcIcMenuUpCan 100;
BA_ "GenSigSendType" SG_ 707 LinSwcIcpaginationCan 7;
BA_ "GenSigCycleTimeActive" SG_ 707 LinSwcIcpaginationCan 100;
BA_ "GenSigCycleTime" SG_ 707 LinSwcIcpaginationCan 100;
BA_ "GenSigSendType" SG_ 707 LinSwcPresenceCanStatus 7;
BA_ "GenSigCycleTimeActive" SG_ 707 LinSwcPresenceCanStatus 100;
BA_ "GenSigCycleTime" SG_ 707 LinSwcPresenceCanStatus 100;
BA_ "GenSigSendType" SG_ 707 LinSwcIcVariant 7;
BA_ "GenSigCycleTimeActive" SG_ 707 LinSwcIcVariant 100;
BA_ "GenSigCycleTime" SG_ 707 LinSwcIcVariant 100;
BA_ "GenSigSendType" SG_ 707 LinSwcPresenceCan 7;
BA_ "GenSigCycleTimeActive" SG_ 707 LinSwcPresenceCan 100;
BA_ "GenSigCycleTime" SG_ 707 LinSwcPresenceCan 100;
BA_ "GenSigSendType" SG_ 707 HuIcVoiceAlertStatusAck 7;
BA_ "GenSigCycleTimeActive" SG_ 707 HuIcVoiceAlertStatusAck 100;
BA_ "GenSigCycleTime" SG_ 707 HuIcVoiceAlertStatusAck 100;
BA_ "GenSigSendType" SG_ 707 HuIcVoiceAlertStateAck 7;
BA_ "GenSigCycleTimeActive" SG_ 707 HuIcVoiceAlertStateAck 100;
BA_ "GenSigCycleTime" SG_ 707 HuIcVoiceAlertStateAck 100;
BA_ "GenSigSendType" SG_ 708 SbCurrentAudioSource 7;
BA_ "GenSigCycleTimeActive" SG_ 708 SbCurrentAudioSource 100;
BA_ "GenSigCycleTime" SG_ 708 SbCurrentAudioSource 100;
BA_ "GenSigSendType" SG_ 708 DispVariant 7;
BA_ "GenSigCycleTimeActive" SG_ 708 DispVariant 100;
BA_ "GenSigCycleTime" SG_ 708 DispVariant 100;
BA_ "GenSigSendType" SG_ 708 SbPowerModeConfig 7;
BA_ "GenSigCycleTimeActive" SG_ 708 SbPowerModeConfig 100;
BA_ "GenSigCycleTime" SG_ 708 SbPowerModeConfig 100;
BA_ "GenSigSendType" SG_ 708 SbCurrentPowerMode 7;
BA_ "GenSigCycleTimeActive" SG_ 708 SbCurrentPowerMode 100;
BA_ "GenSigCycleTime" SG_ 708 SbCurrentPowerMode 100;
BA_ "GenSigSendType" SG_ 708 BpVariant 7;
BA_ "GenSigCycleTimeActive" SG_ 708 BpVariant 100;
BA_ "GenSigCycleTime" SG_ 708 BpVariant 100;
BA_ "GenSigSendType" SG_ 708 DispCurrentPowerMode 7;
BA_ "GenSigCycleTimeActive" SG_ 708 DispCurrentPowerMode 100;
BA_ "GenSigCycleTime" SG_ 708 DispCurrentPowerMode 100;
BA_ "GenSigSendType" SG_ 708 BpCurrentPowerMode 7;
BA_ "GenSigCycleTimeActive" SG_ 708 BpCurrentPowerMode 100;
BA_ "GenSigCycleTime" SG_ 708 BpCurrentPowerMode 100;
BA_ "GenSigSendType" SG_ 708 BpPresence 7;
BA_ "GenSigCycleTimeActive" SG_ 708 BpPresence 100;
BA_ "GenSigCycleTime" SG_ 708 BpPresence 100;
BA_ "GenSigStartValue" SG_ 708 BattVoltSb 120;
BA_ "GenSigSendType" SG_ 708 BattVoltSb 7;
BA_ "GenSigCycleTimeActive" SG_ 708 BattVoltSb 100;
BA_ "GenSigCycleTime" SG_ 708 BattVoltSb 100;
BA_ "GenSigSendType" SG_ 708 DispPresence 7;
BA_ "GenSigCycleTimeActive" SG_ 708 DispPresence 100;
BA_ "GenSigCycleTime" SG_ 708 DispPresence 100;
BA_ "GenSigSendType" SG_ 710 PDcHuFaultState 7;
BA_ "GenSigCycleTimeActive" SG_ 710 PDcHuFaultState 100;
BA_ "GenSigCycleTime" SG_ 710 PDcHuFaultState 100;
BA_ "GenSigSendType" SG_ 710 PDcHuAudioZoneState 7;
BA_ "GenSigCycleTimeActive" SG_ 710 PDcHuAudioZoneState 100;
BA_ "GenSigCycleTime" SG_ 710 PDcHuAudioZoneState 100;
BA_ "GenSigSendType" SG_ 710 PDcHuVisualZoneRearLHSensState 7;
BA_ "GenSigCycleTimeActive" SG_ 710 PDcHuVisualZoneRearLHSensState 100;
BA_ "GenSigCycleTime" SG_ 710 PDcHuVisualZoneRearLHSensState 100;
BA_ "GenSigSendType" SG_ 710 PDcHuVisualZoneRearMidRHSensStat 7;
BA_ "GenSigCycleTimeActive" SG_ 710 PDcHuVisualZoneRearMidRHSensStat 100;
BA_ "GenSigCycleTime" SG_ 710 PDcHuVisualZoneRearMidRHSensStat 100;
BA_ "SystemSignalLongSymbol" SG_ 710 PDcHuVisualZoneRearMidRHSensStat "PDcHuVisualZoneRearMidRHSensState";
BA_ "GenSigSendType" SG_ 710 PDcHuVisualZoneRearRHSensState 7;
BA_ "GenSigCycleTimeActive" SG_ 710 PDcHuVisualZoneRearRHSensState 100;
BA_ "GenSigCycleTime" SG_ 710 PDcHuVisualZoneRearRHSensState 100;
BA_ "GenSigSendType" SG_ 710 PDcHuVisualZoneRearMidLHSensStat 7;
BA_ "GenSigCycleTimeActive" SG_ 710 PDcHuVisualZoneRearMidLHSensStat 100;
BA_ "GenSigCycleTime" SG_ 710 PDcHuVisualZoneRearMidLHSensStat 100;
BA_ "SystemSignalLongSymbol" SG_ 710 PDcHuVisualZoneRearMidLHSensStat "PDcHuVisualZoneRearMidLHSensState";
BA_ "GenSigSendType" SG_ 710 PDcPresence 7;
BA_ "GenSigCycleTimeActive" SG_ 710 PDcPresence 100;
BA_ "GenSigCycleTime" SG_ 710 PDcPresence 100;
BA_ "GenSigSendType" SG_ 710 PDcHuState 7;
BA_ "GenSigCycleTimeActive" SG_ 710 PDcHuState 100;
BA_ "GenSigCycleTime" SG_ 710 PDcHuState 100;
BA_ "GenSigSendType" SG_ 710 PDcHuPwrModeState 7;
BA_ "GenSigCycleTimeActive" SG_ 710 PDcHuPwrModeState 100;
BA_ "GenSigCycleTime" SG_ 710 PDcHuPwrModeState 100;
BA_ "GenSigSendType" SG_ 710 PDcVariant 7;
BA_ "GenSigCycleTimeActive" SG_ 710 PDcVariant 100;
BA_ "GenSigCycleTime" SG_ 710 PDcVariant 100;
BA_ "GenSigSendType" SG_ 710 PDcHuVisualZoneFrontLHSensState 7;
BA_ "GenSigCycleTimeActive" SG_ 710 PDcHuVisualZoneFrontLHSensState 100;
BA_ "GenSigCycleTime" SG_ 710 PDcHuVisualZoneFrontLHSensState 100;
BA_ "GenSigSendType" SG_ 710 PDcHuVisualZoneFrontMidLHSensSta 7;
BA_ "GenSigCycleTimeActive" SG_ 710 PDcHuVisualZoneFrontMidLHSensSta 100;
BA_ "GenSigCycleTime" SG_ 710 PDcHuVisualZoneFrontMidLHSensSta 100;
BA_ "SystemSignalLongSymbol" SG_ 710 PDcHuVisualZoneFrontMidLHSensSta "PDcHuVisualZoneFrontMidLHSensState";
BA_ "GenSigSendType" SG_ 710 PDcHuVisualZoneFrontMidRHSensSta 7;
BA_ "GenSigCycleTimeActive" SG_ 710 PDcHuVisualZoneFrontMidRHSensSta 100;
BA_ "GenSigCycleTime" SG_ 710 PDcHuVisualZoneFrontMidRHSensSta 100;
BA_ "SystemSignalLongSymbol" SG_ 710 PDcHuVisualZoneFrontMidRHSensSta "PDcHuVisualZoneFrontMidRHSensState";
BA_ "GenSigSendType" SG_ 710 PDcHuVisualZoneFrontRHSensState 7;
BA_ "GenSigCycleTimeActive" SG_ 710 PDcHuVisualZoneFrontRHSensState 100;
BA_ "GenSigCycleTime" SG_ 710 PDcHuVisualZoneFrontRHSensState 100;
BA_ "GenSigSendType" SG_ 710 PDcHuFrontAudioZoneState 7;
BA_ "GenSigCycleTimeActive" SG_ 710 PDcHuFrontAudioZoneState 100;
BA_ "GenSigCycleTime" SG_ 710 PDcHuFrontAudioZoneState 100;
BA_ "GenSigSendType" SG_ 710 PDcHuFrontFaultState 7;
BA_ "GenSigCycleTimeActive" SG_ 710 PDcHuFrontFaultState 100;
BA_ "GenSigCycleTime" SG_ 710 PDcHuFrontFaultState 100;
BA_ "GenSigSendType" SG_ 710 PDcHuFrontState 7;
BA_ "GenSigCycleTimeActive" SG_ 710 PDcHuFrontState 100;
BA_ "GenSigCycleTime" SG_ 710 PDcHuFrontState 100;
BA_ "GenSigSendType" SG_ 710 PDcIPcFrontActive 7;
BA_ "GenSigCycleTimeActive" SG_ 710 PDcIPcFrontActive 100;
BA_ "GenSigCycleTime" SG_ 710 PDcIPcFrontActive 100;
BA_ "GenSigSendType" SG_ 710 PDcIPcRearActive 7;
BA_ "GenSigCycleTimeActive" SG_ 710 PDcIPcRearActive 100;
BA_ "GenSigCycleTime" SG_ 710 PDcIPcRearActive 100;
BA_ "GenSigStartValue" SG_ 711 PDcHuProxFrontLHSensState 255;
BA_ "GenSigSendType" SG_ 711 PDcHuProxFrontLHSensState 7;
BA_ "GenSigCycleTimeActive" SG_ 711 PDcHuProxFrontLHSensState 100;
BA_ "GenSigCycleTime" SG_ 711 PDcHuProxFrontLHSensState 100;
BA_ "GenSigStartValue" SG_ 711 PDcHuProxFrontRHSensState 255;
BA_ "GenSigSendType" SG_ 711 PDcHuProxFrontRHSensState 7;
BA_ "GenSigCycleTimeActive" SG_ 711 PDcHuProxFrontRHSensState 100;
BA_ "GenSigCycleTime" SG_ 711 PDcHuProxFrontRHSensState 100;
BA_ "GenSigStartValue" SG_ 711 PDcHuProxFrontMidLHSensState 255;
BA_ "GenSigSendType" SG_ 711 PDcHuProxFrontMidLHSensState 7;
BA_ "GenSigCycleTimeActive" SG_ 711 PDcHuProxFrontMidLHSensState 100;
BA_ "GenSigCycleTime" SG_ 711 PDcHuProxFrontMidLHSensState 100;
BA_ "GenSigStartValue" SG_ 711 PDcHuProxFrontMidRHSensState 255;
BA_ "GenSigSendType" SG_ 711 PDcHuProxFrontMidRHSensState 7;
BA_ "GenSigCycleTimeActive" SG_ 711 PDcHuProxFrontMidRHSensState 100;
BA_ "GenSigCycleTime" SG_ 711 PDcHuProxFrontMidRHSensState 100;
BA_ "GenSigSendType" SG_ 711 PDcHuProxFrontRHSensStateStatus 7;
BA_ "GenSigCycleTimeActive" SG_ 711 PDcHuProxFrontRHSensStateStatus 100;
BA_ "GenSigCycleTime" SG_ 711 PDcHuProxFrontRHSensStateStatus 100;
BA_ "GenSigSendType" SG_ 711 PDcHuProxFrontMidRHSensStateStat 7;
BA_ "GenSigCycleTimeActive" SG_ 711 PDcHuProxFrontMidRHSensStateStat 100;
BA_ "GenSigCycleTime" SG_ 711 PDcHuProxFrontMidRHSensStateStat 100;
BA_ "SystemSignalLongSymbol" SG_ 711 PDcHuProxFrontMidRHSensStateStat "PDcHuProxFrontMidRHSensStateStatus";
BA_ "GenSigSendType" SG_ 711 PDcHuProxFrontMidLHSensStateStat 7;
BA_ "GenSigCycleTimeActive" SG_ 711 PDcHuProxFrontMidLHSensStateStat 100;
BA_ "GenSigCycleTime" SG_ 711 PDcHuProxFrontMidLHSensStateStat 100;
BA_ "SystemSignalLongSymbol" SG_ 711 PDcHuProxFrontMidLHSensStateStat "PDcHuProxFrontMidLHSensStateStatus";
BA_ "GenSigSendType" SG_ 711 PDcHuProxFrontLHSensStateStatus 7;
BA_ "GenSigCycleTimeActive" SG_ 711 PDcHuProxFrontLHSensStateStatus 100;
BA_ "GenSigCycleTime" SG_ 711 PDcHuProxFrontLHSensStateStatus 100;
BA_ "GenSigStartValue" SG_ 712 PDcHuProxRearLHSensState 255;
BA_ "GenSigSendType" SG_ 712 PDcHuProxRearLHSensState 7;
BA_ "GenSigCycleTimeActive" SG_ 712 PDcHuProxRearLHSensState 100;
BA_ "GenSigCycleTime" SG_ 712 PDcHuProxRearLHSensState 100;
BA_ "GenSigStartValue" SG_ 712 PDcHuProxRearRHSensState 255;
BA_ "GenSigSendType" SG_ 712 PDcHuProxRearRHSensState 7;
BA_ "GenSigCycleTimeActive" SG_ 712 PDcHuProxRearRHSensState 100;
BA_ "GenSigCycleTime" SG_ 712 PDcHuProxRearRHSensState 100;
BA_ "GenSigStartValue" SG_ 712 PDcHuProxRearMidLHSensState 255;
BA_ "GenSigSendType" SG_ 712 PDcHuProxRearMidLHSensState 7;
BA_ "GenSigCycleTimeActive" SG_ 712 PDcHuProxRearMidLHSensState 100;
BA_ "GenSigCycleTime" SG_ 712 PDcHuProxRearMidLHSensState 100;
BA_ "GenSigStartValue" SG_ 712 PDcHuProxRearMidRHSensState 255;
BA_ "GenSigSendType" SG_ 712 PDcHuProxRearMidRHSensState 7;
BA_ "GenSigCycleTimeActive" SG_ 712 PDcHuProxRearMidRHSensState 100;
BA_ "GenSigCycleTime" SG_ 712 PDcHuProxRearMidRHSensState 100;
BA_ "GenSigSendType" SG_ 712 PDcHuProxRearRHSensStateStatus 7;
BA_ "GenSigCycleTimeActive" SG_ 712 PDcHuProxRearRHSensStateStatus 100;
BA_ "GenSigCycleTime" SG_ 712 PDcHuProxRearRHSensStateStatus 100;
BA_ "GenSigSendType" SG_ 712 PDcHuProxRearMidRHSensStateStatu 7;
BA_ "GenSigCycleTimeActive" SG_ 712 PDcHuProxRearMidRHSensStateStatu 100;
BA_ "GenSigCycleTime" SG_ 712 PDcHuProxRearMidRHSensStateStatu 100;
BA_ "SystemSignalLongSymbol" SG_ 712 PDcHuProxRearMidRHSensStateStatu "PDcHuProxRearMidRHSensStateStatus";
BA_ "GenSigSendType" SG_ 712 PDcHuProxRearMidLHSensStateStatu 7;
BA_ "GenSigCycleTimeActive" SG_ 712 PDcHuProxRearMidLHSensStateStatu 100;
BA_ "GenSigCycleTime" SG_ 712 PDcHuProxRearMidLHSensStateStatu 100;
BA_ "SystemSignalLongSymbol" SG_ 712 PDcHuProxRearMidLHSensStateStatu "PDcHuProxRearMidLHSensStateStatus";
BA_ "GenSigSendType" SG_ 712 PDcHuProxRearLHSensStateStatus 7;
BA_ "GenSigCycleTimeActive" SG_ 712 PDcHuProxRearLHSensStateStatus 100;
BA_ "GenSigCycleTime" SG_ 712 PDcHuProxRearLHSensStateStatus 100;
BA_ "GenSigSendType" SG_ 713 HuIcMediaState 7;
BA_ "GenSigCycleTimeActive" SG_ 713 HuIcMediaState 100;
BA_ "GenSigCycleTime" SG_ 713 HuIcMediaState 100;
BA_ "GenSigSendType" SG_ 713 HuIcSource 7;
BA_ "GenSigCycleTimeActive" SG_ 713 HuIcSource 100;
BA_ "GenSigCycleTime" SG_ 713 HuIcSource 100;
BA_ "GenSigSendType" SG_ 713 HuIcAudioVolumeStatus 7;
BA_ "GenSigCycleTimeActive" SG_ 713 HuIcAudioVolumeStatus 100;
BA_ "GenSigCycleTime" SG_ 713 HuIcAudioVolumeStatus 100;
BA_ "GenSigSendType" SG_ 713 HuIcBTStatus 7;
BA_ "GenSigCycleTimeActive" SG_ 713 HuIcBTStatus 100;
BA_ "GenSigCycleTime" SG_ 713 HuIcBTStatus 100;
BA_ "GenSigSendType" SG_ 713 HuIcPlabackCallDurationSec 7;
BA_ "GenSigCycleTimeActive" SG_ 713 HuIcPlabackCallDurationSec 100;
BA_ "GenSigCycleTime" SG_ 713 HuIcPlabackCallDurationSec 100;
BA_ "GenSigSendType" SG_ 713 HuIcRepeatOneState 7;
BA_ "GenSigCycleTimeActive" SG_ 713 HuIcRepeatOneState 100;
BA_ "GenSigCycleTime" SG_ 713 HuIcRepeatOneState 100;
BA_ "GenSigSendType" SG_ 713 HuIcMuteStatus 7;
BA_ "GenSigCycleTimeActive" SG_ 713 HuIcMuteStatus 100;
BA_ "GenSigCycleTime" SG_ 713 HuIcMuteStatus 100;
BA_ "GenSigSendType" SG_ 713 HuIcPlabackCallDurationMin 7;
BA_ "GenSigCycleTimeActive" SG_ 713 HuIcPlabackCallDurationMin 100;
BA_ "GenSigCycleTime" SG_ 713 HuIcPlabackCallDurationMin 100;
BA_ "GenSigSendType" SG_ 713 HuIcSMSReceiveState 7;
BA_ "GenSigCycleTimeActive" SG_ 713 HuIcSMSReceiveState 100;
BA_ "GenSigCycleTime" SG_ 713 HuIcSMSReceiveState 100;
BA_ "GenSigSendType" SG_ 713 HuIcRepeatState 7;
BA_ "GenSigCycleTimeActive" SG_ 713 HuIcRepeatState 100;
BA_ "GenSigCycleTime" SG_ 713 HuIcRepeatState 100;
BA_ "GenSigSendType" SG_ 713 HuIcPlabackCallDurationHrs 7;
BA_ "GenSigCycleTimeActive" SG_ 713 HuIcPlabackCallDurationHrs 100;
BA_ "GenSigCycleTime" SG_ 713 HuIcPlabackCallDurationHrs 100;
BA_ "GenSigSendType" SG_ 713 HuIcPhoneCallStatus 7;
BA_ "GenSigCycleTimeActive" SG_ 713 HuIcPhoneCallStatus 100;
BA_ "GenSigCycleTime" SG_ 713 HuIcPhoneCallStatus 100;
BA_ "GenSigSendType" SG_ 713 HuIcPlaybackElapsedTimeHrs 7;
BA_ "GenSigCycleTimeActive" SG_ 713 HuIcPlaybackElapsedTimeHrs 100;
BA_ "GenSigCycleTime" SG_ 713 HuIcPlaybackElapsedTimeHrs 100;
BA_ "GenSigSendType" SG_ 713 HuIcNetworkSignalStatus 7;
BA_ "GenSigCycleTimeActive" SG_ 713 HuIcNetworkSignalStatus 100;
BA_ "GenSigCycleTime" SG_ 713 HuIcNetworkSignalStatus 100;
BA_ "GenSigSendType" SG_ 713 HuIcPlaybackElapsedTimeMin 7;
BA_ "GenSigCycleTimeActive" SG_ 713 HuIcPlaybackElapsedTimeMin 100;
BA_ "GenSigCycleTime" SG_ 713 HuIcPlaybackElapsedTimeMin 100;
BA_ "GenSigSendType" SG_ 713 HuIcInfoFeaturePresence 7;
BA_ "GenSigCycleTimeActive" SG_ 713 HuIcInfoFeaturePresence 100;
BA_ "GenSigCycleTime" SG_ 713 HuIcInfoFeaturePresence 100;
BA_ "GenSigSendType" SG_ 713 HuIcShuffleState 7;
BA_ "GenSigCycleTimeActive" SG_ 713 HuIcShuffleState 100;
BA_ "GenSigCycleTime" SG_ 713 HuIcShuffleState 100;
BA_ "GenSigSendType" SG_ 713 HuIcPlaybackElapsedTimeSec 7;
BA_ "GenSigCycleTimeActive" SG_ 713 HuIcPlaybackElapsedTimeSec 100;
BA_ "GenSigCycleTime" SG_ 713 HuIcPlaybackElapsedTimeSec 100;
BA_ "GenSigTimeoutTime_HU_B" SG_ 714 TrailerPositionLmpMalFn 0;
BA_ "GenSigTimeoutTime_HU_A" SG_ 714 TrailerPositionLmpMalFn 0;
BA_ "GenSigTimeoutMsg_HU_B" SG_ 714 TrailerPositionLmpMalFn 0;
BA_ "GenSigTimeoutMsg_HU_A" SG_ 714 TrailerPositionLmpMalFn 0;
BA_ "GenSigSendType" SG_ 714 TrailerPositionLmpMalFn 7;
BA_ "GenSigCycleTimeActive" SG_ 714 TrailerPositionLmpMalFn 100;
BA_ "GenSigCycleTime" SG_ 714 TrailerPositionLmpMalFn 100;
BA_ "GenSigTimeoutTime_HU_B" SG_ 714 TrailerRevLmpMalFn 0;
BA_ "GenSigTimeoutTime_HU_A" SG_ 714 TrailerRevLmpMalFn 0;
BA_ "GenSigTimeoutMsg_HU_B" SG_ 714 TrailerRevLmpMalFn 0;
BA_ "GenSigTimeoutMsg_HU_A" SG_ 714 TrailerRevLmpMalFn 0;
BA_ "GenSigSendType" SG_ 714 TrailerRevLmpMalFn 7;
BA_ "GenSigCycleTimeActive" SG_ 714 TrailerRevLmpMalFn 100;
BA_ "GenSigCycleTime" SG_ 714 TrailerRevLmpMalFn 100;
BA_ "GenSigTimeoutTime_HU_B" SG_ 714 TrailerBrkLmpMalFnStatus 0;
BA_ "GenSigTimeoutTime_HU_A" SG_ 714 TrailerBrkLmpMalFnStatus 0;
BA_ "GenSigTimeoutMsg_HU_B" SG_ 714 TrailerBrkLmpMalFnStatus 0;
BA_ "GenSigTimeoutMsg_HU_A" SG_ 714 TrailerBrkLmpMalFnStatus 0;
BA_ "GenSigSendType" SG_ 714 TrailerBrkLmpMalFnStatus 7;
BA_ "GenSigCycleTimeActive" SG_ 714 TrailerBrkLmpMalFnStatus 100;
BA_ "GenSigCycleTime" SG_ 714 TrailerBrkLmpMalFnStatus 100;
BA_ "GenSigTimeoutTime_HU_B" SG_ 714 TrailerBrkLmpMalFn 0;
BA_ "GenSigTimeoutTime_HU_A" SG_ 714 TrailerBrkLmpMalFn 0;
BA_ "GenSigTimeoutMsg_HU_B" SG_ 714 TrailerBrkLmpMalFn 0;
BA_ "GenSigTimeoutMsg_HU_A" SG_ 714 TrailerBrkLmpMalFn 0;
BA_ "GenSigSendType" SG_ 714 TrailerBrkLmpMalFn 7;
BA_ "GenSigCycleTimeActive" SG_ 714 TrailerBrkLmpMalFn 100;
BA_ "GenSigCycleTime" SG_ 714 TrailerBrkLmpMalFn 100;
BA_ "GenSigTimeoutTime_HU_B" SG_ 714 TrailerPresenceStatus 0;
BA_ "GenSigTimeoutTime_HU_A" SG_ 714 TrailerPresenceStatus 0;
BA_ "GenSigTimeoutMsg_HU_B" SG_ 714 TrailerPresenceStatus 0;
BA_ "GenSigTimeoutMsg_HU_A" SG_ 714 TrailerPresenceStatus 0;
BA_ "GenSigSendType" SG_ 714 TrailerPresenceStatus 7;
BA_ "GenSigCycleTimeActive" SG_ 714 TrailerPresenceStatus 100;
BA_ "GenSigCycleTime" SG_ 714 TrailerPresenceStatus 100;
BA_ "GenSigTimeoutTime_HU_B" SG_ 714 TrailerPresence 0;
BA_ "GenSigTimeoutTime_HU_A" SG_ 714 TrailerPresence 0;
BA_ "GenSigTimeoutMsg_HU_B" SG_ 714 TrailerPresence 0;
BA_ "GenSigTimeoutMsg_HU_A" SG_ 714 TrailerPresence 0;
BA_ "GenSigSendType" SG_ 714 TrailerPresence 7;
BA_ "GenSigCycleTimeActive" SG_ 714 TrailerPresence 100;
BA_ "GenSigCycleTime" SG_ 714 TrailerPresence 100;
BA_ "GenSigTimeoutTime_HU_B" SG_ 714 TrailerTurnLhMalFn 0;
BA_ "GenSigTimeoutTime_HU_A" SG_ 714 TrailerTurnLhMalFn 0;
BA_ "GenSigTimeoutMsg_HU_B" SG_ 714 TrailerTurnLhMalFn 0;
BA_ "GenSigTimeoutMsg_HU_A" SG_ 714 TrailerTurnLhMalFn 0;
BA_ "GenSigSendType" SG_ 714 TrailerTurnLhMalFn 7;
BA_ "GenSigCycleTimeActive" SG_ 714 TrailerTurnLhMalFn 100;
BA_ "GenSigCycleTime" SG_ 714 TrailerTurnLhMalFn 100;
BA_ "GenSigTimeoutTime_HU_B" SG_ 714 TrailerFogMalFnStatus 0;
BA_ "GenSigTimeoutTime_HU_A" SG_ 714 TrailerFogMalFnStatus 0;
BA_ "GenSigTimeoutMsg_HU_B" SG_ 714 TrailerFogMalFnStatus 0;
BA_ "GenSigTimeoutMsg_HU_A" SG_ 714 TrailerFogMalFnStatus 0;
BA_ "GenSigSendType" SG_ 714 TrailerFogMalFnStatus 7;
BA_ "GenSigCycleTimeActive" SG_ 714 TrailerFogMalFnStatus 100;
BA_ "GenSigCycleTime" SG_ 714 TrailerFogMalFnStatus 100;
BA_ "GenSigTimeoutTime_HU_B" SG_ 714 TrailerFogMalFn 0;
BA_ "GenSigTimeoutTime_HU_A" SG_ 714 TrailerFogMalFn 0;
BA_ "GenSigTimeoutMsg_HU_B" SG_ 714 TrailerFogMalFn 0;
BA_ "GenSigTimeoutMsg_HU_A" SG_ 714 TrailerFogMalFn 0;
BA_ "GenSigSendType" SG_ 714 TrailerFogMalFn 7;
BA_ "GenSigCycleTimeActive" SG_ 714 TrailerFogMalFn 100;
BA_ "GenSigCycleTime" SG_ 714 TrailerFogMalFn 100;
BA_ "GenSigTimeoutTime_HU_B" SG_ 714 TrailerPositionLmpMalFnStatus 0;
BA_ "GenSigTimeoutTime_HU_A" SG_ 714 TrailerPositionLmpMalFnStatus 0;
BA_ "GenSigTimeoutMsg_HU_B" SG_ 714 TrailerPositionLmpMalFnStatus 0;
BA_ "GenSigTimeoutMsg_HU_A" SG_ 714 TrailerPositionLmpMalFnStatus 0;
BA_ "GenSigSendType" SG_ 714 TrailerPositionLmpMalFnStatus 7;
BA_ "GenSigCycleTimeActive" SG_ 714 TrailerPositionLmpMalFnStatus 100;
BA_ "GenSigCycleTime" SG_ 714 TrailerPositionLmpMalFnStatus 100;
BA_ "GenSigTimeoutTime_HU_B" SG_ 714 TrailerRevLmpMalFnStatus 0;
BA_ "GenSigTimeoutTime_HU_A" SG_ 714 TrailerRevLmpMalFnStatus 0;
BA_ "GenSigTimeoutMsg_HU_B" SG_ 714 TrailerRevLmpMalFnStatus 0;
BA_ "GenSigTimeoutMsg_HU_A" SG_ 714 TrailerRevLmpMalFnStatus 0;
BA_ "GenSigSendType" SG_ 714 TrailerRevLmpMalFnStatus 7;
BA_ "GenSigCycleTimeActive" SG_ 714 TrailerRevLmpMalFnStatus 100;
BA_ "GenSigCycleTime" SG_ 714 TrailerRevLmpMalFnStatus 100;
BA_ "GenSigTimeoutTime_HU_B" SG_ 714 TrailerTurnRhMalFnStatus 0;
BA_ "GenSigTimeoutTime_HU_A" SG_ 714 TrailerTurnRhMalFnStatus 0;
BA_ "GenSigTimeoutMsg_HU_B" SG_ 714 TrailerTurnRhMalFnStatus 0;
BA_ "GenSigTimeoutMsg_HU_A" SG_ 714 TrailerTurnRhMalFnStatus 0;
BA_ "GenSigSendType" SG_ 714 TrailerTurnRhMalFnStatus 7;
BA_ "GenSigCycleTimeActive" SG_ 714 TrailerTurnRhMalFnStatus 100;
BA_ "GenSigCycleTime" SG_ 714 TrailerTurnRhMalFnStatus 100;
BA_ "GenSigTimeoutTime_HU_B" SG_ 714 TrailerTurnRhMalFn 0;
BA_ "GenSigTimeoutTime_HU_A" SG_ 714 TrailerTurnRhMalFn 0;
BA_ "GenSigTimeoutMsg_HU_B" SG_ 714 TrailerTurnRhMalFn 0;
BA_ "GenSigTimeoutMsg_HU_A" SG_ 714 TrailerTurnRhMalFn 0;
BA_ "GenSigSendType" SG_ 714 TrailerTurnRhMalFn 7;
BA_ "GenSigCycleTimeActive" SG_ 714 TrailerTurnRhMalFn 100;
BA_ "GenSigCycleTime" SG_ 714 TrailerTurnRhMalFn 100;
BA_ "GenSigTimeoutTime_HU_B" SG_ 714 TrailerTurnLhMalFnStatus 0;
BA_ "GenSigTimeoutTime_HU_A" SG_ 714 TrailerTurnLhMalFnStatus 0;
BA_ "GenSigTimeoutMsg_HU_B" SG_ 714 TrailerTurnLhMalFnStatus 0;
BA_ "GenSigTimeoutMsg_HU_A" SG_ 714 TrailerTurnLhMalFnStatus 0;
BA_ "GenSigSendType" SG_ 714 TrailerTurnLhMalFnStatus 7;
BA_ "GenSigCycleTimeActive" SG_ 714 TrailerTurnLhMalFnStatus 100;
BA_ "GenSigCycleTime" SG_ 714 TrailerTurnLhMalFnStatus 100;
BA_ "GenSigSendType" SG_ 715 RemoteAcStatus 7;
BA_ "GenSigCycleTimeActive" SG_ 715 RemoteAcStatus 100;
BA_ "GenSigCycleTime" SG_ 715 RemoteAcStatus 100;
BA_ "GenSigSendType" SG_ 715 RemoteAcState 7;
BA_ "GenSigCycleTimeActive" SG_ 715 RemoteAcState 100;
BA_ "GenSigCycleTime" SG_ 715 RemoteAcState 100;
BA_ "GenSigTimeoutTime_HU_Mid_X451" SG_ 715 CcmEmsIACReqSts 0;
BA_ "GenSigTimeoutTime_HU_High_X451" SG_ 715 CcmEmsIACReqSts 0;
BA_ "GenSigTimeoutTime_HU_B" SG_ 715 CcmEmsIACReqSts 0;
BA_ "GenSigTimeoutTime_HU_A" SG_ 715 CcmEmsIACReqSts 0;
BA_ "GenSigTimeoutMsg_HU_Mid_X451" SG_ 715 CcmEmsIACReqSts 0;
BA_ "GenSigTimeoutMsg_HU_High_X451" SG_ 715 CcmEmsIACReqSts 0;
BA_ "GenSigTimeoutMsg_HU_B" SG_ 715 CcmEmsIACReqSts 0;
BA_ "GenSigTimeoutMsg_HU_A" SG_ 715 CcmEmsIACReqSts 0;
BA_ "GenSigSendType" SG_ 715 CcmEmsIACReqSts 7;
BA_ "GenSigCycleTimeActive" SG_ 715 CcmEmsIACReqSts 100;
BA_ "GenSigCycleTime" SG_ 715 CcmEmsIACReqSts 100;
BA_ "GenSigTimeoutTime_HU_Mid_X451" SG_ 715 CcmEmsIACReq 0;
BA_ "GenSigTimeoutTime_HU_High_X451" SG_ 715 CcmEmsIACReq 0;
BA_ "GenSigTimeoutTime_HU_B" SG_ 715 CcmEmsIACReq 0;
BA_ "GenSigTimeoutTime_HU_A" SG_ 715 CcmEmsIACReq 0;
BA_ "GenSigTimeoutMsg_HU_Mid_X451" SG_ 715 CcmEmsIACReq 0;
BA_ "GenSigTimeoutMsg_HU_High_X451" SG_ 715 CcmEmsIACReq 0;
BA_ "GenSigTimeoutMsg_HU_B" SG_ 715 CcmEmsIACReq 0;
BA_ "GenSigTimeoutMsg_HU_A" SG_ 715 CcmEmsIACReq 0;
BA_ "GenSigSendType" SG_ 715 CcmEmsIACReq 7;
BA_ "GenSigCycleTimeActive" SG_ 715 CcmEmsIACReq 100;
BA_ "GenSigCycleTime" SG_ 715 CcmEmsIACReq 100;
BA_ "GenSigTimeoutTime_HU_Mid_X451" SG_ 715 AcReq 0;
BA_ "GenSigTimeoutTime_HU_High_X451" SG_ 715 AcReq 0;
BA_ "GenSigTimeoutTime_HU_B" SG_ 715 AcReq 0;
BA_ "GenSigTimeoutTime_HU_A" SG_ 715 AcReq 0;
BA_ "GenSigTimeoutMsg_HU_Mid_X451" SG_ 715 AcReq 0;
BA_ "GenSigTimeoutMsg_HU_High_X451" SG_ 715 AcReq 0;
BA_ "GenSigTimeoutMsg_HU_B" SG_ 715 AcReq 0;
BA_ "GenSigTimeoutMsg_HU_A" SG_ 715 AcReq 0;
BA_ "GenSigSendType" SG_ 715 AcReq 7;
BA_ "GenSigCycleTimeActive" SG_ 715 AcReq 100;
BA_ "GenSigCycleTime" SG_ 715 AcReq 100;
BA_ "GenSigStartValue" SG_ 715 VehicleInteriorTemp 130;
BA_ "GenSigSendType" SG_ 715 VehicleInteriorTemp 7;
BA_ "GenSigCycleTimeActive" SG_ 715 VehicleInteriorTemp 100;
BA_ "GenSigCycleTime" SG_ 715 VehicleInteriorTemp 100;
BA_ "GenSigTimeoutTime_HU_B" SG_ 715 HRwReqFrmCCmStatus 0;
BA_ "GenSigTimeoutTime_HU_A" SG_ 715 HRwReqFrmCCmStatus 0;
BA_ "GenSigTimeoutMsg_HU_B" SG_ 715 HRwReqFrmCCmStatus 0;
BA_ "GenSigTimeoutMsg_HU_A" SG_ 715 HRwReqFrmCCmStatus 0;
BA_ "GenSigSendType" SG_ 715 HRwReqFrmCCmStatus 7;
BA_ "GenSigCycleTimeActive" SG_ 715 HRwReqFrmCCmStatus 100;
BA_ "GenSigCycleTime" SG_ 715 HRwReqFrmCCmStatus 100;
BA_ "GenSigSendType" SG_ 715 CCmVariantType 7;
BA_ "GenSigCycleTimeActive" SG_ 715 CCmVariantType 100;
BA_ "GenSigCycleTime" SG_ 715 CCmVariantType 100;
BA_ "GenSigSendType" SG_ 715 CCmPresence 7;
BA_ "GenSigCycleTimeActive" SG_ 715 CCmPresence 100;
BA_ "GenSigCycleTime" SG_ 715 CCmPresence 100;
BA_ "GenSigSendType" SG_ 715 VehicleInteriorTempStatus 7;
BA_ "GenSigCycleTimeActive" SG_ 715 VehicleInteriorTempStatus 100;
BA_ "GenSigCycleTime" SG_ 715 VehicleInteriorTempStatus 100;
BA_ "GenSigTimeoutTime_HU_B" SG_ 715 HRwReqFrmCCm 0;
BA_ "GenSigTimeoutTime_HU_A" SG_ 715 HRwReqFrmCCm 0;
BA_ "GenSigTimeoutMsg_HU_B" SG_ 715 HRwReqFrmCCm 0;
BA_ "GenSigTimeoutMsg_HU_A" SG_ 715 HRwReqFrmCCm 0;
BA_ "GenSigSendType" SG_ 715 HRwReqFrmCCm 7;
BA_ "GenSigCycleTimeActive" SG_ 715 HRwReqFrmCCm 100;
BA_ "GenSigCycleTime" SG_ 715 HRwReqFrmCCm 100;
BA_ "GenSigTimeoutTime_HU_Mid_X451" SG_ 715 CcmEmsEngStopStartReq 0;
BA_ "GenSigTimeoutTime_HU_High_X451" SG_ 715 CcmEmsEngStopStartReq 0;
BA_ "GenSigTimeoutTime_HU_B" SG_ 715 CcmEmsEngStopStartReq 0;
BA_ "GenSigTimeoutTime_HU_A" SG_ 715 CcmEmsEngStopStartReq 0;
BA_ "GenSigTimeoutMsg_HU_Mid_X451" SG_ 715 CcmEmsEngStopStartReq 0;
BA_ "GenSigTimeoutMsg_HU_High_X451" SG_ 715 CcmEmsEngStopStartReq 0;
BA_ "GenSigTimeoutMsg_HU_B" SG_ 715 CcmEmsEngStopStartReq 0;
BA_ "GenSigTimeoutMsg_HU_A" SG_ 715 CcmEmsEngStopStartReq 0;
BA_ "GenSigSendType" SG_ 715 CcmEmsEngStopStartReq 7;
BA_ "GenSigCycleTimeActive" SG_ 715 CcmEmsEngStopStartReq 100;
BA_ "GenSigCycleTime" SG_ 715 CcmEmsEngStopStartReq 100;
BA_ "GenSigTimeoutTime_HU_Mid_X451" SG_ 715 CcmEmsEngStopStartReqSts 0;
BA_ "GenSigTimeoutTime_HU_High_X451" SG_ 715 CcmEmsEngStopStartReqSts 0;
BA_ "GenSigTimeoutTime_HU_B" SG_ 715 CcmEmsEngStopStartReqSts 0;
BA_ "GenSigTimeoutTime_HU_A" SG_ 715 CcmEmsEngStopStartReqSts 0;
BA_ "GenSigTimeoutMsg_HU_Mid_X451" SG_ 715 CcmEmsEngStopStartReqSts 0;
BA_ "GenSigTimeoutMsg_HU_High_X451" SG_ 715 CcmEmsEngStopStartReqSts 0;
BA_ "GenSigTimeoutMsg_HU_B" SG_ 715 CcmEmsEngStopStartReqSts 0;
BA_ "GenSigTimeoutMsg_HU_A" SG_ 715 CcmEmsEngStopStartReqSts 0;
BA_ "GenSigSendType" SG_ 715 CcmEmsEngStopStartReqSts 7;
BA_ "GenSigCycleTimeActive" SG_ 715 CcmEmsEngStopStartReqSts 100;
BA_ "GenSigCycleTime" SG_ 715 CcmEmsEngStopStartReqSts 100;
BA_ "GenSigTimeoutTime_HU_Mid_X451" SG_ 715 EVAPSig 0;
BA_ "GenSigTimeoutTime_HU_High_X451" SG_ 715 EVAPSig 0;
BA_ "GenSigTimeoutTime_HU_B" SG_ 715 EVAPSig 0;
BA_ "GenSigTimeoutTime_HU_A" SG_ 715 EVAPSig 0;
BA_ "GenSigTimeoutMsg_HU_Mid_X451" SG_ 715 EVAPSig 0;
BA_ "GenSigTimeoutMsg_HU_High_X451" SG_ 715 EVAPSig 0;
BA_ "GenSigTimeoutMsg_HU_B" SG_ 715 EVAPSig 0;
BA_ "GenSigTimeoutMsg_HU_A" SG_ 715 EVAPSig 0;
BA_ "GenSigStartValue" SG_ 715 EVAPSig 130;
BA_ "GenSigSendType" SG_ 715 EVAPSig 7;
BA_ "GenSigCycleTimeActive" SG_ 715 EVAPSig 100;
BA_ "GenSigCycleTime" SG_ 715 EVAPSig 100;
BA_ "GenSigTimeoutTime_HU_Mid_X451" SG_ 715 EVAPSigStatus 0;
BA_ "GenSigTimeoutTime_HU_High_X451" SG_ 715 EVAPSigStatus 0;
BA_ "GenSigTimeoutTime_HU_B" SG_ 715 EVAPSigStatus 0;
BA_ "GenSigTimeoutTime_HU_A" SG_ 715 EVAPSigStatus 0;
BA_ "GenSigTimeoutMsg_HU_Mid_X451" SG_ 715 EVAPSigStatus 0;
BA_ "GenSigTimeoutMsg_HU_High_X451" SG_ 715 EVAPSigStatus 0;
BA_ "GenSigTimeoutMsg_HU_B" SG_ 715 EVAPSigStatus 0;
BA_ "GenSigTimeoutMsg_HU_A" SG_ 715 EVAPSigStatus 0;
BA_ "GenSigSendType" SG_ 715 EVAPSigStatus 7;
BA_ "GenSigCycleTimeActive" SG_ 715 EVAPSigStatus 100;
BA_ "GenSigCycleTime" SG_ 715 EVAPSigStatus 100;
BA_ "GenSigSendType" SG_ 720 RearWasherStateStatus 7;
BA_ "GenSigCycleTimeActive" SG_ 720 RearWasherStateStatus 100;
BA_ "GenSigCycleTime" SG_ 720 RearWasherStateStatus 100;
BA_ "GenSigSendType" SG_ 720 RearWasherState 7;
BA_ "GenSigCycleTimeActive" SG_ 720 RearWasherState 100;
BA_ "GenSigCycleTime" SG_ 720 RearWasherState 100;
BA_ "GenSigSendType" SG_ 720 FrontWasherStateStatus 7;
BA_ "GenSigCycleTimeActive" SG_ 720 FrontWasherStateStatus 100;
BA_ "GenSigCycleTime" SG_ 720 FrontWasherStateStatus 100;
BA_ "GenSigSendType" SG_ 720 FrontWasherState 7;
BA_ "GenSigCycleTimeActive" SG_ 720 FrontWasherState 100;
BA_ "GenSigCycleTime" SG_ 720 FrontWasherState 100;
BA_ "GenSigSendType" SG_ 720 AutoWipeStateStatus 7;
BA_ "GenSigCycleTimeActive" SG_ 720 AutoWipeStateStatus 100;
BA_ "GenSigCycleTime" SG_ 720 AutoWipeStateStatus 100;
BA_ "GenSigSendType" SG_ 720 AutoWipeState 7;
BA_ "GenSigCycleTimeActive" SG_ 720 AutoWipeState 100;
BA_ "GenSigCycleTime" SG_ 720 AutoWipeState 100;
BA_ "GenSigSendType" SG_ 720 PositionLmpTelltale 7;
BA_ "GenSigCycleTimeActive" SG_ 720 PositionLmpTelltale 100;
BA_ "GenSigCycleTime" SG_ 720 PositionLmpTelltale 100;
BA_ "GenSigSendType" SG_ 720 PositionLmpTelltaleStatus 7;
BA_ "GenSigCycleTimeActive" SG_ 720 PositionLmpTelltaleStatus 100;
BA_ "GenSigCycleTime" SG_ 720 PositionLmpTelltaleStatus 100;
BA_ "GenSigTimeoutTime_HU_B" SG_ 720 BattVolt_BCM 0;
BA_ "GenSigTimeoutTime_HU_A" SG_ 720 BattVolt_BCM 0;
BA_ "GenSigTimeoutMsg_HU_B" SG_ 720 BattVolt_BCM 0;
BA_ "GenSigTimeoutMsg_HU_A" SG_ 720 BattVolt_BCM 0;
BA_ "GenSigSendType" SG_ 720 BattVolt_BCM 7;
BA_ "GenSigCycleTimeActive" SG_ 720 BattVolt_BCM 100;
BA_ "GenSigCycleTime" SG_ 720 BattVolt_BCM 100;
BA_ "GenSigSendType" SG_ 720 BCMVariant 7;
BA_ "GenSigCycleTimeActive" SG_ 720 BCMVariant 100;
BA_ "GenSigCycleTime" SG_ 720 BCMVariant 100;
BA_ "GenSigSendType" SG_ 720 BCMPresence 7;
BA_ "GenSigCycleTimeActive" SG_ 720 BCMPresence 100;
BA_ "GenSigCycleTime" SG_ 720 BCMPresence 100;
BA_ "GenSigSendType" SG_ 720 RevGearStatus 7;
BA_ "GenSigCycleTimeActive" SG_ 720 RevGearStatus 100;
BA_ "GenSigCycleTime" SG_ 720 RevGearStatus 100;
BA_ "GenSigSendType" SG_ 720 RevGear 7;
BA_ "GenSigCycleTimeActive" SG_ 720 RevGear 100;
BA_ "GenSigCycleTime" SG_ 720 RevGear 100;
BA_ "GenSigTimeoutTime_HU_B" SG_ 720 RevLmpON 0;
BA_ "GenSigTimeoutTime_HU_A" SG_ 720 RevLmpON 0;
BA_ "GenSigTimeoutMsg_HU_B" SG_ 720 RevLmpON 0;
BA_ "GenSigTimeoutMsg_HU_A" SG_ 720 RevLmpON 0;
BA_ "GenSigSendType" SG_ 720 RevLmpON 7;
BA_ "GenSigCycleTimeActive" SG_ 720 RevLmpON 100;
BA_ "GenSigCycleTime" SG_ 720 RevLmpON 100;
BA_ "GenSigTimeoutTime_HU_B" SG_ 720 RevLmpONStatus 0;
BA_ "GenSigTimeoutTime_HU_A" SG_ 720 RevLmpONStatus 0;
BA_ "GenSigTimeoutMsg_HU_B" SG_ 720 RevLmpONStatus 0;
BA_ "GenSigTimeoutMsg_HU_A" SG_ 720 RevLmpONStatus 0;
BA_ "GenSigSendType" SG_ 720 RevLmpONStatus 7;
BA_ "GenSigCycleTimeActive" SG_ 720 RevLmpONStatus 100;
BA_ "GenSigCycleTime" SG_ 720 RevLmpONStatus 100;
BA_ "GenSigTimeoutTime_HU_B" SG_ 720 RearFogLmpON 0;
BA_ "GenSigTimeoutTime_HU_A" SG_ 720 RearFogLmpON 0;
BA_ "GenSigTimeoutMsg_HU_B" SG_ 720 RearFogLmpON 0;
BA_ "GenSigTimeoutMsg_HU_A" SG_ 720 RearFogLmpON 0;
BA_ "GenSigSendType" SG_ 720 RearFogLmpON 7;
BA_ "GenSigCycleTimeActive" SG_ 720 RearFogLmpON 100;
BA_ "GenSigCycleTime" SG_ 720 RearFogLmpON 100;
BA_ "GenSigTimeoutTime_HU_B" SG_ 720 RearFogLmpONStatus 0;
BA_ "GenSigTimeoutTime_HU_A" SG_ 720 RearFogLmpONStatus 0;
BA_ "GenSigTimeoutMsg_HU_B" SG_ 720 RearFogLmpONStatus 0;
BA_ "GenSigTimeoutMsg_HU_A" SG_ 720 RearFogLmpONStatus 0;
BA_ "GenSigSendType" SG_ 720 RearFogLmpONStatus 7;
BA_ "GenSigCycleTimeActive" SG_ 720 RearFogLmpONStatus 100;
BA_ "GenSigCycleTime" SG_ 720 RearFogLmpONStatus 100;
BA_ "GenSigSendType" SG_ 720 TurnLHTelltaleStatus 7;
BA_ "GenSigCycleTimeActive" SG_ 720 TurnLHTelltaleStatus 100;
BA_ "GenSigCycleTime" SG_ 720 TurnLHTelltaleStatus 100;
BA_ "GenSigSendType" SG_ 720 TurnLHTelltale 7;
BA_ "GenSigCycleTimeActive" SG_ 720 TurnLHTelltale 100;
BA_ "GenSigCycleTime" SG_ 720 TurnLHTelltale 100;
BA_ "GenSigSendType" SG_ 720 TurnRHTelltaleStatus 7;
BA_ "GenSigCycleTimeActive" SG_ 720 TurnRHTelltaleStatus 100;
BA_ "GenSigCycleTime" SG_ 720 TurnRHTelltaleStatus 100;
BA_ "GenSigSendType" SG_ 720 TurnRHTelltale 7;
BA_ "GenSigCycleTimeActive" SG_ 720 TurnRHTelltale 100;
BA_ "GenSigCycleTime" SG_ 720 TurnRHTelltale 100;
BA_ "GenSigSendType" SG_ 720 LightSensActiveStatus 7;
BA_ "GenSigCycleTimeActive" SG_ 720 LightSensActiveStatus 100;
BA_ "GenSigCycleTime" SG_ 720 LightSensActiveStatus 100;
BA_ "GenSigSendType" SG_ 720 LightSensActive 7;
BA_ "GenSigCycleTimeActive" SG_ 720 LightSensActive 100;
BA_ "GenSigCycleTime" SG_ 720 LightSensActive 100;
BA_ "GenSigSendType" SG_ 720 RVcPresence 7;
BA_ "GenSigCycleTimeActive" SG_ 720 RVcPresence 100;
BA_ "GenSigCycleTime" SG_ 720 RVcPresence 100;
BA_ "GenSigTimeoutTime_HU_B" SG_ 720 BcmCcmSolarInputLh 0;
BA_ "GenSigTimeoutTime_HU_A" SG_ 720 BcmCcmSolarInputLh 0;
BA_ "GenSigTimeoutMsg_HU_B" SG_ 720 BcmCcmSolarInputLh 0;
BA_ "GenSigTimeoutMsg_HU_A" SG_ 720 BcmCcmSolarInputLh 0;
BA_ "GenSigSendType" SG_ 720 BcmCcmSolarInputLh 7;
BA_ "GenSigCycleTimeActive" SG_ 720 BcmCcmSolarInputLh 100;
BA_ "GenSigCycleTime" SG_ 720 BcmCcmSolarInputLh 100;
BA_ "GenSigTimeoutTime_HU_B" SG_ 720 BcmCcmSolarInputRh 0;
BA_ "GenSigTimeoutTime_HU_A" SG_ 720 BcmCcmSolarInputRh 0;
BA_ "GenSigTimeoutMsg_HU_B" SG_ 720 BcmCcmSolarInputRh 0;
BA_ "GenSigTimeoutMsg_HU_A" SG_ 720 BcmCcmSolarInputRh 0;
BA_ "GenSigSendType" SG_ 720 BcmCcmSolarInputRh 7;
BA_ "GenSigCycleTimeActive" SG_ 720 BcmCcmSolarInputRh 100;
BA_ "GenSigCycleTime" SG_ 720 BcmCcmSolarInputRh 100;
BA_ "GenSigSendType" SG_ 722 PowerModeStateStatus 7;
BA_ "GenSigCycleTimeActive" SG_ 722 PowerModeStateStatus 100;
BA_ "GenSigCycleTime" SG_ 722 PowerModeStateStatus 100;
BA_ "GenSigStartValue" SG_ 722 PowerModeState 1;
BA_ "GenSigSendType" SG_ 722 PowerModeState 7;
BA_ "GenSigCycleTimeActive" SG_ 722 PowerModeState 100;
BA_ "GenSigCycleTime" SG_ 722 PowerModeState 100;
BA_ "GenSigSendType" SG_ 722 PositionLmpTelltaleStatus 7;
BA_ "GenSigCycleTimeActive" SG_ 722 PositionLmpTelltaleStatus 100;
BA_ "GenSigCycleTime" SG_ 722 PositionLmpTelltaleStatus 100;
BA_ "GenSigSendType" SG_ 722 PositionLmpTelltale 7;
BA_ "GenSigCycleTimeActive" SG_ 722 PositionLmpTelltale 100;
BA_ "GenSigCycleTime" SG_ 722 PositionLmpTelltale 100;
BA_ "GenSigTimeoutTime_HU_B" SG_ 722 HRwFdBkFrmBCm 0;
BA_ "GenSigTimeoutTime_HU_A" SG_ 722 HRwFdBkFrmBCm 0;
BA_ "GenSigTimeoutMsg_HU_B" SG_ 722 HRwFdBkFrmBCm 0;
BA_ "GenSigTimeoutMsg_HU_A" SG_ 722 HRwFdBkFrmBCm 0;
BA_ "GenSigSendType" SG_ 722 HRwFdBkFrmBCm 7;
BA_ "GenSigCycleTimeActive" SG_ 722 HRwFdBkFrmBCm 100;
BA_ "GenSigCycleTime" SG_ 722 HRwFdBkFrmBCm 100;
BA_ "GenSigTimeoutTime_HU_B" SG_ 722 HRwFdBkFrmBCmStatus 0;
BA_ "GenSigTimeoutTime_HU_A" SG_ 722 HRwFdBkFrmBCmStatus 0;
BA_ "GenSigTimeoutMsg_HU_B" SG_ 722 HRwFdBkFrmBCmStatus 0;
BA_ "GenSigTimeoutMsg_HU_A" SG_ 722 HRwFdBkFrmBCmStatus 0;
BA_ "GenSigSendType" SG_ 722 HRwFdBkFrmBCmStatus 7;
BA_ "GenSigCycleTimeActive" SG_ 722 HRwFdBkFrmBCmStatus 100;
BA_ "GenSigCycleTime" SG_ 722 HRwFdBkFrmBCmStatus 100;
BA_ "GenSigSendType" SG_ 722 TurnRHTelltale 7;
BA_ "GenSigCycleTimeActive" SG_ 722 TurnRHTelltale 100;
BA_ "GenSigCycleTime" SG_ 722 TurnRHTelltale 100;
BA_ "GenSigSendType" SG_ 722 TurnLHTelltaleStatus 7;
BA_ "GenSigCycleTimeActive" SG_ 722 TurnLHTelltaleStatus 100;
BA_ "GenSigCycleTime" SG_ 722 TurnLHTelltaleStatus 100;
BA_ "GenSigSendType" SG_ 722 TurnLHTelltale 7;
BA_ "GenSigCycleTimeActive" SG_ 722 TurnLHTelltale 100;
BA_ "GenSigCycleTime" SG_ 722 TurnLHTelltale 100;
BA_ "GenSigSendType" SG_ 722 TurnRHTelltaleStatus 7;
BA_ "GenSigCycleTimeActive" SG_ 722 TurnRHTelltaleStatus 100;
BA_ "GenSigCycleTime" SG_ 722 TurnRHTelltaleStatus 100;
BA_ "GenSigSendType" SG_ 722 BattSaverFnONStatus 7;
BA_ "GenSigCycleTimeActive" SG_ 722 BattSaverFnONStatus 100;
BA_ "GenSigCycleTime" SG_ 722 BattSaverFnONStatus 100;
BA_ "GenSigSendType" SG_ 722 BattSaverFnON 7;
BA_ "GenSigCycleTimeActive" SG_ 722 BattSaverFnON 100;
BA_ "GenSigCycleTime" SG_ 722 BattSaverFnON 100;
BA_ "GenSigTimeoutTime_HU_B" SG_ 722 BrkLmpONStatus 0;
BA_ "GenSigTimeoutTime_HU_A" SG_ 722 BrkLmpONStatus 0;
BA_ "GenSigTimeoutMsg_HU_B" SG_ 722 BrkLmpONStatus 0;
BA_ "GenSigTimeoutMsg_HU_A" SG_ 722 BrkLmpONStatus 0;
BA_ "GenSigSendType" SG_ 722 BrkLmpONStatus 7;
BA_ "GenSigCycleTimeActive" SG_ 722 BrkLmpONStatus 100;
BA_ "GenSigCycleTime" SG_ 722 BrkLmpONStatus 100;
BA_ "GenSigTimeoutTime_HU_B" SG_ 722 BrkLmpON 0;
BA_ "GenSigTimeoutTime_HU_A" SG_ 722 BrkLmpON 0;
BA_ "GenSigTimeoutMsg_HU_B" SG_ 722 BrkLmpON 0;
BA_ "GenSigTimeoutMsg_HU_A" SG_ 722 BrkLmpON 0;
BA_ "GenSigSendType" SG_ 722 BrkLmpON 7;
BA_ "GenSigCycleTimeActive" SG_ 722 BrkLmpON 100;
BA_ "GenSigCycleTime" SG_ 722 BrkLmpON 100;
BA_ "GenSigStartValue" SG_ 722 CockpitSigECuStatus 2;
BA_ "GenSigSendType" SG_ 722 CockpitSigECuStatus 7;
BA_ "GenSigCycleTimeActive" SG_ 722 CockpitSigECuStatus 100;
BA_ "GenSigCycleTime" SG_ 722 CockpitSigECuStatus 100;
BA_ "GenSigTimeoutTime_HU_B" SG_ 722 RearRHTurnLmpON 0;
BA_ "GenSigTimeoutTime_HU_A" SG_ 722 RearRHTurnLmpON 0;
BA_ "GenSigTimeoutMsg_HU_B" SG_ 722 RearRHTurnLmpON 0;
BA_ "GenSigTimeoutMsg_HU_A" SG_ 722 RearRHTurnLmpON 0;
BA_ "GenSigSendType" SG_ 722 RearRHTurnLmpON 7;
BA_ "GenSigCycleTimeActive" SG_ 722 RearRHTurnLmpON 100;
BA_ "GenSigCycleTime" SG_ 722 RearRHTurnLmpON 100;
BA_ "GenSigTimeoutTime_HU_B" SG_ 722 RearRHTurnLmpONStatus 0;
BA_ "GenSigTimeoutTime_HU_A" SG_ 722 RearRHTurnLmpONStatus 0;
BA_ "GenSigTimeoutMsg_HU_B" SG_ 722 RearRHTurnLmpONStatus 0;
BA_ "GenSigTimeoutMsg_HU_A" SG_ 722 RearRHTurnLmpONStatus 0;
BA_ "GenSigSendType" SG_ 722 RearRHTurnLmpONStatus 7;
BA_ "GenSigCycleTimeActive" SG_ 722 RearRHTurnLmpONStatus 100;
BA_ "GenSigCycleTime" SG_ 722 RearRHTurnLmpONStatus 100;
BA_ "GenSigTimeoutTime_HU_B" SG_ 722 RearLHTurnLmpONStatus 0;
BA_ "GenSigTimeoutTime_HU_A" SG_ 722 RearLHTurnLmpONStatus 0;
BA_ "GenSigTimeoutMsg_HU_B" SG_ 722 RearLHTurnLmpONStatus 0;
BA_ "GenSigTimeoutMsg_HU_A" SG_ 722 RearLHTurnLmpONStatus 0;
BA_ "GenSigSendType" SG_ 722 RearLHTurnLmpONStatus 7;
BA_ "GenSigCycleTimeActive" SG_ 722 RearLHTurnLmpONStatus 100;
BA_ "GenSigCycleTime" SG_ 722 RearLHTurnLmpONStatus 100;
BA_ "GenSigTimeoutTime_HU_B" SG_ 722 RearLHTurnLmpON 0;
BA_ "GenSigTimeoutTime_HU_A" SG_ 722 RearLHTurnLmpON 0;
BA_ "GenSigTimeoutMsg_HU_B" SG_ 722 RearLHTurnLmpON 0;
BA_ "GenSigTimeoutMsg_HU_A" SG_ 722 RearLHTurnLmpON 0;
BA_ "GenSigSendType" SG_ 722 RearLHTurnLmpON 7;
BA_ "GenSigCycleTimeActive" SG_ 722 RearLHTurnLmpON 100;
BA_ "GenSigCycleTime" SG_ 722 RearLHTurnLmpON 100;
BA_ "GenSigSendType" SG_ 722 CockpitSigECu 7;
BA_ "GenSigCycleTimeActive" SG_ 722 CockpitSigECu 100;
BA_ "GenSigCycleTime" SG_ 722 CockpitSigECu 100;
BA_ "GenSigTimeoutTime_HU_B" SG_ 722 VehicleLockStateStatus 0;
BA_ "GenSigTimeoutTime_HU_A" SG_ 722 VehicleLockStateStatus 0;
BA_ "GenSigTimeoutMsg_HU_B" SG_ 722 VehicleLockStateStatus 0;
BA_ "GenSigTimeoutMsg_HU_A" SG_ 722 VehicleLockStateStatus 0;
BA_ "GenSigSendType" SG_ 722 VehicleLockStateStatus 7;
BA_ "GenSigCycleTimeActive" SG_ 722 VehicleLockStateStatus 100;
BA_ "GenSigCycleTime" SG_ 722 VehicleLockStateStatus 100;
BA_ "GenSigSendType" SG_ 722 HighBeamTelltaleStatus 7;
BA_ "GenSigCycleTimeActive" SG_ 722 HighBeamTelltaleStatus 100;
BA_ "GenSigCycleTime" SG_ 722 HighBeamTelltaleStatus 100;
BA_ "GenSigSendType" SG_ 722 HighBeamTelltale 7;
BA_ "GenSigCycleTimeActive" SG_ 722 HighBeamTelltale 100;
BA_ "GenSigCycleTime" SG_ 722 HighBeamTelltale 100;
BA_ "GenSigSendType" SG_ 722 KeyInStateStatus 7;
BA_ "GenSigCycleTimeActive" SG_ 722 KeyInStateStatus 100;
BA_ "GenSigCycleTime" SG_ 722 KeyInStateStatus 100;
BA_ "GenSigSendType" SG_ 722 KeyInState 7;
BA_ "GenSigCycleTimeActive" SG_ 722 KeyInState 100;
BA_ "GenSigCycleTime" SG_ 722 KeyInState 100;
BA_ "GenSigTimeoutTime_HU_B" SG_ 722 PowerModeStateMsgCnt 0;
BA_ "GenSigTimeoutTime_HU_A" SG_ 722 PowerModeStateMsgCnt 0;
BA_ "GenSigTimeoutMsg_HU_B" SG_ 722 PowerModeStateMsgCnt 0;
BA_ "GenSigTimeoutMsg_HU_A" SG_ 722 PowerModeStateMsgCnt 0;
BA_ "GenSigSendType" SG_ 722 PowerModeStateMsgCnt 7;
BA_ "GenSigCycleTimeActive" SG_ 722 PowerModeStateMsgCnt 100;
BA_ "GenSigCycleTime" SG_ 722 PowerModeStateMsgCnt 100;
BA_ "GenSigTimeoutTime_HU_B" SG_ 722 VehicleLockState 0;
BA_ "GenSigTimeoutTime_HU_A" SG_ 722 VehicleLockState 0;
BA_ "GenSigTimeoutMsg_HU_B" SG_ 722 VehicleLockState 0;
BA_ "GenSigTimeoutMsg_HU_A" SG_ 722 VehicleLockState 0;
BA_ "GenSigStartValue" SG_ 722 VehicleLockState 3;
BA_ "GenSigSendType" SG_ 722 VehicleLockState 7;
BA_ "GenSigInactiveValue" SG_ 722 VehicleLockState 3;
BA_ "GenSigCycleTimeActive" SG_ 722 VehicleLockState 100;
BA_ "GenSigCycleTime" SG_ 722 VehicleLockState 100;
BA_ "GenSigTimeoutTime_HU_B" SG_ 722 PowerModeStateCRC 0;
BA_ "GenSigTimeoutTime_HU_A" SG_ 722 PowerModeStateCRC 0;
BA_ "GenSigTimeoutMsg_HU_B" SG_ 722 PowerModeStateCRC 0;
BA_ "GenSigTimeoutMsg_HU_A" SG_ 722 PowerModeStateCRC 0;
BA_ "GenSigSendType" SG_ 722 PowerModeStateCRC 7;
BA_ "GenSigCycleTimeActive" SG_ 722 PowerModeStateCRC 100;
BA_ "GenSigCycleTime" SG_ 722 PowerModeStateCRC 100;
BA_ "GenSigTimeoutTime_HU_Mid_X451" SG_ 729 VehicleMobilizationStateStatus 0;
BA_ "GenSigTimeoutTime_HU_High_X451" SG_ 729 VehicleMobilizationStateStatus 0;
BA_ "GenSigTimeoutTime_HU_B" SG_ 729 VehicleMobilizationStateStatus 0;
BA_ "GenSigTimeoutTime_HU_A" SG_ 729 VehicleMobilizationStateStatus 0;
BA_ "GenSigTimeoutMsg_HU_Mid_X451" SG_ 729 VehicleMobilizationStateStatus 0;
BA_ "GenSigTimeoutMsg_HU_High_X451" SG_ 729 VehicleMobilizationStateStatus 0;
BA_ "GenSigTimeoutMsg_HU_B" SG_ 729 VehicleMobilizationStateStatus 0;
BA_ "GenSigTimeoutMsg_HU_A" SG_ 729 VehicleMobilizationStateStatus 0;
BA_ "GenSigSendType" SG_ 729 VehicleMobilizationStateStatus 7;
BA_ "GenSigCycleTimeActive" SG_ 729 VehicleMobilizationStateStatus 100;
BA_ "GenSigCycleTime" SG_ 729 VehicleMobilizationStateStatus 100;
BA_ "GenSigTimeoutMsg_HU_High_X445" SG_ 729 VehicleMobilizationStateStatus 0;
BA_ "GenSigTimeoutMsg_HU_Mid_X445" SG_ 729 VehicleMobilizationStateStatus 0;
BA_ "GenSigTimeoutTime_HU_High_X445" SG_ 729 VehicleMobilizationStateStatus 0;
BA_ "GenSigTimeoutTime_HU_Mid_X445" SG_ 729 VehicleMobilizationStateStatus 0;
BA_ "GenSigTimeoutTime_HU_Mid_X451" SG_ 729 VehicleMobilizationState 0;
BA_ "GenSigTimeoutTime_HU_High_X451" SG_ 729 VehicleMobilizationState 0;
BA_ "GenSigTimeoutTime_HU_B" SG_ 729 VehicleMobilizationState 0;
BA_ "GenSigTimeoutTime_HU_A" SG_ 729 VehicleMobilizationState 0;
BA_ "GenSigTimeoutMsg_HU_Mid_X451" SG_ 729 VehicleMobilizationState 0;
BA_ "GenSigTimeoutMsg_HU_High_X451" SG_ 729 VehicleMobilizationState 0;
BA_ "GenSigTimeoutMsg_HU_B" SG_ 729 VehicleMobilizationState 0;
BA_ "GenSigTimeoutMsg_HU_A" SG_ 729 VehicleMobilizationState 0;
BA_ "GenSigStartValue" SG_ 729 VehicleMobilizationState 1;
BA_ "GenSigSendType" SG_ 729 VehicleMobilizationState 7;
BA_ "GenSigCycleTimeActive" SG_ 729 VehicleMobilizationState 100;
BA_ "GenSigCycleTime" SG_ 729 VehicleMobilizationState 100;
BA_ "GenSigTimeoutMsg_HU_High_X445" SG_ 729 VehicleMobilizationState 0;
BA_ "GenSigTimeoutMsg_HU_Mid_X445" SG_ 729 VehicleMobilizationState 0;
BA_ "GenSigTimeoutTime_HU_High_X445" SG_ 729 VehicleMobilizationState 0;
BA_ "GenSigTimeoutTime_HU_Mid_X445" SG_ 729 VehicleMobilizationState 0;
BA_ "GenSigTimeoutTime_HU_B" SG_ 729 KeySearchStatusPEPS 0;
BA_ "GenSigTimeoutTime_HU_A" SG_ 729 KeySearchStatusPEPS 0;
BA_ "GenSigTimeoutMsg_HU_B" SG_ 729 KeySearchStatusPEPS 0;
BA_ "GenSigTimeoutMsg_HU_A" SG_ 729 KeySearchStatusPEPS 0;
BA_ "GenSigSendType" SG_ 729 KeySearchStatusPEPS 7;
BA_ "GenSigCycleTimeActive" SG_ 729 KeySearchStatusPEPS 100;
BA_ "GenSigCycleTime" SG_ 729 KeySearchStatusPEPS 100;
BA_ "GenSigStartValue" SG_ 729 PEPsClampState 1;
BA_ "GenSigSendType" SG_ 729 PEPsClampState 7;
BA_ "GenSigCycleTimeActive" SG_ 729 PEPsClampState 100;
BA_ "GenSigCycleTime" SG_ 729 PEPsClampState 100;
BA_ "GenSigSendType" SG_ 729 PEPsClampStateStatus 7;
BA_ "GenSigCycleTimeActive" SG_ 729 PEPsClampStateStatus 100;
BA_ "GenSigCycleTime" SG_ 729 PEPsClampStateStatus 100;
BA_ "GenSigTimeoutTime_HU_B" SG_ 729 ESClLockInhibitPEPS 0;
BA_ "GenSigTimeoutTime_HU_A" SG_ 729 ESClLockInhibitPEPS 0;
BA_ "GenSigTimeoutMsg_HU_B" SG_ 729 ESClLockInhibitPEPS 0;
BA_ "GenSigTimeoutMsg_HU_A" SG_ 729 ESClLockInhibitPEPS 0;
BA_ "GenSigSendType" SG_ 729 ESClLockInhibitPEPS 7;
BA_ "GenSigCycleTimeActive" SG_ 729 ESClLockInhibitPEPS 100;
BA_ "GenSigCycleTime" SG_ 729 ESClLockInhibitPEPS 100;
BA_ "GenSigSendType" SG_ 729 PEPsPresence 7;
BA_ "GenSigCycleTimeActive" SG_ 729 PEPsPresence 100;
BA_ "GenSigCycleTime" SG_ 729 PEPsPresence 100;
BA_ "GenSigTimeoutTime_HU_B" SG_ 729 PEPsKeyInState 0;
BA_ "GenSigTimeoutTime_HU_A" SG_ 729 PEPsKeyInState 0;
BA_ "GenSigTimeoutMsg_HU_B" SG_ 729 PEPsKeyInState 0;
BA_ "GenSigTimeoutMsg_HU_A" SG_ 729 PEPsKeyInState 0;
BA_ "GenSigSendType" SG_ 729 PEPsKeyInState 7;
BA_ "GenSigCycleTimeActive" SG_ 729 PEPsKeyInState 100;
BA_ "GenSigCycleTime" SG_ 729 PEPsKeyInState 100;
BA_ "GenSigTimeoutTime_HU_B" SG_ 729 PEPsVehLockCmd 0;
BA_ "GenSigTimeoutTime_HU_A" SG_ 729 PEPsVehLockCmd 0;
BA_ "GenSigTimeoutMsg_HU_B" SG_ 729 PEPsVehLockCmd 0;
BA_ "GenSigTimeoutMsg_HU_A" SG_ 729 PEPsVehLockCmd 0;
BA_ "GenSigSendType" SG_ 729 PEPsVehLockCmd 7;
BA_ "GenSigCycleTimeActive" SG_ 729 PEPsVehLockCmd 100;
BA_ "GenSigCycleTime" SG_ 729 PEPsVehLockCmd 100;
BA_ "GenSigTimeoutTime_HU_B" SG_ 729 PEPsVehLockCmdStatus 0;
BA_ "GenSigTimeoutTime_HU_A" SG_ 729 PEPsVehLockCmdStatus 0;
BA_ "GenSigTimeoutMsg_HU_B" SG_ 729 PEPsVehLockCmdStatus 0;
BA_ "GenSigTimeoutMsg_HU_A" SG_ 729 PEPsVehLockCmdStatus 0;
BA_ "GenSigSendType" SG_ 729 PEPsVehLockCmdStatus 7;
BA_ "GenSigCycleTimeActive" SG_ 729 PEPsVehLockCmdStatus 100;
BA_ "GenSigCycleTime" SG_ 729 PEPsVehLockCmdStatus 100;
BA_ "GenSigTimeoutTime_HU_B" SG_ 729 PEPsClampStateMRC 0;
BA_ "GenSigTimeoutTime_HU_A" SG_ 729 PEPsClampStateMRC 0;
BA_ "GenSigTimeoutMsg_HU_B" SG_ 729 PEPsClampStateMRC 0;
BA_ "GenSigTimeoutMsg_HU_A" SG_ 729 PEPsClampStateMRC 0;
BA_ "GenSigSendType" SG_ 729 PEPsClampStateMRC 7;
BA_ "GenSigCycleTimeActive" SG_ 729 PEPsClampStateMRC 100;
BA_ "GenSigCycleTime" SG_ 729 PEPsClampStateMRC 100;
BA_ "GenSigTimeoutTime_HU_B" SG_ 729 PEPsClampStateCRC 0;
BA_ "GenSigTimeoutTime_HU_A" SG_ 729 PEPsClampStateCRC 0;
BA_ "GenSigTimeoutMsg_HU_B" SG_ 729 PEPsClampStateCRC 0;
BA_ "GenSigTimeoutMsg_HU_A" SG_ 729 PEPsClampStateCRC 0;
BA_ "GenSigSendType" SG_ 729 PEPsClampStateCRC 7;
BA_ "GenSigCycleTimeActive" SG_ 729 PEPsClampStateCRC 100;
BA_ "GenSigCycleTime" SG_ 729 PEPsClampStateCRC 100;
VAL_ 661 AccSystemState 15 "SNA" 14 "Reserved" 13 "Reserved" 12 "Reserved" 11 "Reserved" 10 "Reserved" 9 "Reserved" 8 "HAS_BSoC" 7 "NCC_Cancel" 6 "NCC_Engaged" 5 "NCC_Enabled" 4 "ACC_Cancel" 3 "ACC_Engaged_BrakeOnly" 2 "ACC_Engaged" 1 "ACC_Enabled" 0 "OFF" ;
VAL_ 661 DDOATextIndication 7 "Reserved Bit" 6 "Level 5 Text" 5 "Level 4 Text" 4 "Level 3 Text" 3 "Level 2 Text1" 2 "Level 2 Text2" 1 "Level 1 Text" 0 "Default" ;
VAL_ 661 DDOAAvailability 1 "DDOA not available" 0 "DDOA Available" ;
VAL_ 661 DDOAState 7 "Reserved Bit" 6 "Reserved Bit" 5 "Level 5" 4 "Level 4" 3 "Level 3" 2 "Level 2" 1 "Level 1" 0 "Default" ;
VAL_ 661 DDOAFuncState 3 "Reserved" 2 "DDOA function switched off due to a detected failure at  ESP system @ DDOA failure lamp is ON." 1 "Reserved" 0 "DDOA function fully available @DDOA failure lamp is OFF" ;
VAL_ 661 DriverChangeState 1 "Driver change detected" 0 "Default" ;
VAL_ 661 iTPMsIndctnStatus 3 "Signal is not available" 2 "Signal value is implausible" 1 "Reserved" 0 "Signal value is plausible" ;
VAL_ 661 iTPMsIndctn 1 "Check tyre pressure" 0 "Tyre pressure is ok" ;
VAL_ 661 iTPMsResetSett 1 "Reset Active" 0 "Reset not active" ;
VAL_ 661 iTPMsTxtInfoStatus 3 "Signal Not available" 2 "Information given  is implausible" 1 "Reserved" 0 "Information given is correct and according to specification" ;
VAL_ 661 iTPMSTxtInfo 1 "Display Value" 0 "Drive to display" ;
VAL_ 661 iTPMsAvailability 1 "TPMS function not available" 0 "TPMS function available" ;
VAL_ 661 iTPMsStatus 3 "TPMS learning completed" 2 "TPMS function switched off due to a detected failure at  ESP system " 1 "TPMS Reset in Process" 0 "TPMS function fully available " ;
VAL_ 662 BrakeAccPedalSimultaneouslyAlert 1 "Brake and Acc pedal simulataneously press Alert ON" 0 "Brake and Acc Pedal simultaneously press Alert OFF" ;
VAL_ 662 TxmnMilReq 1 "transmission NOK , OBD related malfunction" 0 "transmission OK , No OBD related malfunction" ;
VAL_ 662 GearIndicationTcuSts 1 "Blinking" 0 "Normal" ;
VAL_ 662 BuzzerRequest 7 "Reserved" 6 "Warning beep (pulse sound)" 5 "Warning beep (continuously sound)" 4 "Warning beep (intermittant pulse sound)" 3 "warning/Fault indication (short pulse sound)" 2 "Reverse buzzer On" 1 "Buzzer off" 0 "Reserved" ;
VAL_ 662 GearForDisplay 15 "Fault" 14 "Reserved" 13 "Reserved" 12 "Reserved" 11 "Reserved" 10 "Reserved" 9 "Reserved" 8 "Reverse gear" 7 "Sixth gear" 6 "Fifth gear" 5 "Fourth gear" 4 "Third gear" 3 "Second Gear" 2 "First gear" 1 "Neutral" 0 "Reserved" ;
VAL_ 662 TransShiftModeSts 1 "Blinking" 0 "Normal" ;
VAL_ 662 GearForDisplayStatus 3 "Signal not available" 2 "Value is implausible" 1 "Reserved" 0 "Value is valid" ;
VAL_ 662 RoboticTxmnFailCode 3 "Reserved" 2 "NCR warning present'" 1 "NCR vehicle Interface fail present" 0 "No failure" ;
VAL_ 662 TransShiftMode 1 "Automatic mode is active" 0 "Manual mode is active" ;
VAL_ 662 DriveModeTcu 3 "Reserved" 2 "Economy mode" 1 "Sports" 0 "Reserved " ;
VAL_ 662 GearShiftIndctnTcuStatus 3 "Signal not available" 2 "Value is implausible" 1 "Reserved" 0 "Value is plausible" ;
VAL_ 662 TransServiceIndication 3 "Reserved" 2 "AMT system warning lamp ON" 1 "AMT system warning lamp flashing" 0 "AMT System warning lamp off" ;
VAL_ 662 TcuErrMsgUserInfo 15 "No Message" 14 "Reserved for future use" 13 "Reserved for future use" 12 "Reserved for future use" 11 "Reserved for future use" 10 "Reserved for future use" 9 "Clutch over temperature" 8 "Move Gear shift lever to Neutral" 7 "Delayed Starter" 6 "Press brake pedal repeat" 5 "Press brake pedal repeat manoeurve" 4 "Lower gear shift" 3 "Automatic mode not available" 2 "Manual mode not available" 1 "Manoeuvre not allowed" 0 "Tip not available" ;
VAL_ 662 GearShiftIndctnTcu 7 "Reserved for future use" 6 "Reserved for future use" 5 "Shift Gear Up Blinking" 4 "Shift Gear Down Blinking" 3 "Reserved" 2 "Shift Gear Up" 1 "Shift Gear Down" 0 "GearShift OK" ;
VAL_ 662 ShifterLeverPos 7 "Reserved" 6 "Tap Down position" 5 "Tap Up position" 4 "Manual Position" 3 "reverse position" 2 "Drive position" 1 "neutral position" 0 "Reserved" ;
VAL_ 662 ShifterLeverPosStatus 3 "Signal not available" 2 "value is implausible" 1 "Reserved" 0 "Value is plausible" ;
VAL_ 664 TcuErrMsgUserInfoAT 7 "No warning/error/fault  message " 6 "Reserved" 5 "Reserved" 4 "Auto Park lock activated " 3 "reverse not available, speed to high" 2 "Press brake to move lever from Park" 1 "Only Auto Mode is available" 0 "Ensure hand brake is applied(Park lock failure)" ;
VAL_ 664 BuzzerRequestAT 7 "Reserved" 6 "Warning beep (pulse sound)" 5 "Warning beep (continuously sound)" 4 "Warning beep (intermittant pulse sound)" 3 "warning/Fault indication (short pulse sound)" 2 "Reverse buzzer On" 1 "Buzzer off" 0 "Reserved" ;
VAL_ 664 TrnOilTmpStatus 3 "Signal is not available" 2 "Signal value is implausible" 1 "Reserved" 0 "Signal value is plausible" ;
VAL_ 664 TCUFault 3 "Reserved" 2 "diagnostic failure in TCU, limp home activated " 1 "diagnostic failure in TCU " 0 "no failure " ;
VAL_ 664 DrShftCntrlReqDndIO 1 "driver gear request cannot be allowed" 0 "No request " ;
VAL_ 666 TcuErrMsgUserInfoDCT 7 "No warning/error/fault  message " 6 "Reserved" 5 "Reserved" 4 "Auto Park lock activated" 3 "Reverse not available,speed to high" 2 "Press brake to move lever from Park" 1 "Only Auto Mode is available" 0 "Ensure Hand Brake is applied(Park lock failure)" ;
VAL_ 666 DrShftCntrlReqDndIODCT 1 "driver gear request cannot be allowed" 0 "No request " ;
VAL_ 666 TxmnOilSumpTempStatus 3 "Signal is not available" 2 "Signal value is implausible" 1 "Reserved" 0 "Signal value is plausible" ;
VAL_ 666 BuzzerRequestDct 7 "Reserved" 6 "Warning beep (pulse sound)" 5 "Warning beep (continuously sound)" 4 "Warning beep (intermittant pulse sound)" 3 "warning/Fault indication (short pulse sound)" 2 "Reverse buzzer On" 1 "Buzzer off" 0 "Reserved" ;
VAL_ 666 TransServiceIndicationDCT 3 "Diagnostic failure, Stay in drive mode for recovery action" 2 "Diagnostic failure TCU, Limp home activated" 1 "Diagnostic failure TCU, Transmission malfunction" 0 "No failure" ;
VAL_ 666 CoolingFanStateReq 1 "FAN active" 0 "No Specific request" ;
VAL_ 666 ACCmprsrStateReq 3 "Reserved for future " 2 "Stop AC" 1 "Freeze AC state" 0 "No Specific request" ;
VAL_ 666 GearShiftIndctnTcuDct 7 "Not applicable or  Not supported" 6 "Reserved for future use" 5 "Shift Gear Up Blinking" 4 "Shift Gear Down Blinking" 3 "Reserved" 2 "Shift Gear Up" 1 "Shift Gear Down" 0 "GearShift OK" ;
VAL_ 666 GearShiftIndctnTcuDctStatus 3 "Signal not available" 2 "Value is implausible" 1 "Reserved" 0 "Value is plausible" ;
VAL_ 666 TxmnOverheated 1 "transmission is  Over heated" 0 "transmission is not Over heated" ;
VAL_ 666 InhibitStopStrt 1 "Start Stop function inhibited" 0 "Start Stop function not inhibited" ;
VAL_ 666 GearForDisplayDctStatus 3 "Signal is not available" 2 "Signal value is implausible" 1 "Reserved" 0 "Information given by signal is correct and according to specification" ;
VAL_ 666 GearForDisplayDct 15 "fault" 14 "Reverse gear" 13 "Not Used" 12 "Not Used" 11 "Not Used" 10 "Not Used" 9 "Not Used" 8 "Seventh gear" 7 "sixth gear" 6 "fifth gear" 5 "fourth gear" 4 "third gear" 3 "second gear" 2 "first gear" 1 "neutral" 0 "Not Used" ;
VAL_ 666 BrkPedalPressReq 1 "Brake press requested" 0 "Brake press not requested" ;
VAL_ 666 TxmnMilReq 1 "transmission NOK , OBD related malfunction" 0 "transmission OK , No OBD related malfunction" ;
VAL_ 666 EngShutAuth 1 "engine stopping authorized" 0 "engine stopping not authorized" ;
VAL_ 666 EngStopReqESS 1 "engine Stop request is Active" 0 "engine Stop request is Inactive" ;
VAL_ 666 EngRestrtReq 1 "engine restart requested by TCU" 0 "engine restart not requested by TCU" ;
VAL_ 693 iTPMsResetStatus 3 "Signal Not available" 2 "Information given  is implausible" 1 "Reserved" 0 "Information given is correct and according to specification" ;
VAL_ 693 iTPMsReset 1 "iTPMS reset input" 0 "No iTPMS reset input" ;
VAL_ 693 HvBattSoCColor 7 "Reserved" 6 "Reserved" 5 "Reserved" 4 "Blinking Red" 3 "Red" 2 "Amber" 1 "Green" 0 "No Action" ;
VAL_ 693 LowFuelOutputICStatus 3 "Signal not available" 2 "Signal is Implausible" 1 "Reserved for future use" 0 "Signal is correct" ;
VAL_ 693 LowFuelOutputIC 1 "Low Fuel Indication ON" 0 "Low Fuel Indication OFF" ;
VAL_ 693 ParkBrkState 1 "Park Brake is ON" 0 "Park Brake is Off" ;
VAL_ 693 IcPlatformVariant 15 "Reserved" 14 "Reserved" 13 "Reserved" 12 "Reserved" 11 "Reserved" 10 "Reserved" 9 "IC_4LCD_X451" 8 "IC_7TFT_Q5" 7 "IC_7TFT_X451" 6 "IC_4LCD_Q5" 5 "IC-F" 4 "IC-C-Eagle" 3 "IC-B" 2 "IC-C" 1 "IC-E" 0 "IC-D" ;
VAL_ 693 OATICSigStatus 3 "Signal not available" 2 "Value is impluasible" 1 "Reserved" 0 "Value is plausible" ;
VAL_ 693 IcPresence 1 "Reserved" 0 "IC Present" ;
VAL_ 693 SRSWarningLampStatus 1 "Lamp Failure" 0 "Lamp No failure" ;
VAL_ 693 VsSPulseCountSigStatus 3 "Signal not available" 2 "Reserved for future" 1 "Reserved for future" 0 "Value is correct" ;
VAL_ 693 IcHuVoiceAlertState 26 "Smart key out of range" 25 "Key Fob battery Low" 24 "Service Remainder" 23 "Water in Fuel" 22 "Low Oil Pressure" 21 "Low Brake fluid" 20 "Low fuel warning" 19 "Rear Left Tyre Pressure Monitoring" 18 "Rear Right Tyre Pressure Monitoring" 17 "Front Left Tyre Pressure Monitoring" 16 "Front Right Tyre Pressure Monitoring" 15 "Park Brake ON" 14 "Driver Seat Belt Remainder" 13 "Tail Gate open" 12 "Rear Left door open" 11 "Rear Right door open" 10 "Co Driver Door open" 9 "Driver Door Open" 8 "Door Open - general warning" 7 "Economy Mode" 6 "Sport Mode" 5 "Normal/ City Mode" 4 "Rough Road Mode" 3 "Dynamic Mode" 2 "Comfort Mode" 1 "Auto Mode" 0 "No Warning" ;
VAL_ 693 IcHuVoiceAlertStateStatus 1 "Active" 0 "Inactive" ;
VAL_ 693 ICCurDriveModeSig 15 "Reserved" 14 "Reserved" 13 "Reserved" 12 "Reserved" 11 "Reserved" 10 "Reserved" 9 "Reserved" 8 "Reserved" 7 "Reserved" 6 "Eco Mode" 5 "Sport Mode" 4 "City Mode" 3 "Dynamic Mode" 2 "Rough Road Mode" 1 "Comfort Mode" 0 "Auto Mode" ;
VAL_ 693 IcHuCarImageSelection 15 "Reserved" 14 "Reserved" 13 "Reserved" 12 "Reserved" 11 "Reserved" 10 "X451 EV Car Image" 9 "X446 Car Image" 8 "X445 Car Image" 7 "X442 Car Image" 6 "X441 Car Image" 5 "X454 Car Image" 4 "X453 Car Image" 3 "X452 Car Image" 2 "X451 Car Image" 1 "Q502 Car Image" 0 "Q501 Car Image" ;
VAL_ 693 IcSbDispReq 1 "Active" 0 "InActive" ;
VAL_ 693 IcSbrDrvrSeatBeltSwitchStatus 1 "Driver Seat Belt is not buckled" 0 "Driver Seat belt is buckled" ;
VAL_ 695 RefuelAlert 1 "Refuel warning present" 0 "No refuel warning present" ;
VAL_ 695 IcHuDrvrSeatBeltInfo 1 "Driver Seat Belt On" 0 "Driver Seat Belt Off" ;
VAL_ 695 IcHuVehRegion 3 "Reserved" 2 "UK" 1 "Domestic" 0 "Export" ;
VAL_ 695 IcHuTyreSize 15 "Reserved" 14 "Reserved" 13 "Reserved" 12 "Reserved" 11 "Reserved" 10 "Reserved" 9 "Reserved" 8 "Reserved" 7 "Reserved" 6 "Reserved" 5 "R13" 4 "R18" 3 "R17" 2 "R16" 1 "R15" 0 "R14" ;
VAL_ 695 RevGearIPC 1 "Reverse gear engaged" 0 "Reverse gear disengaged" ;
VAL_ 695 RevGearIPCStatus 3 "Signal not available" 2 "Reserved" 1 "Reserved" 0 "Value is pluasible" ;
VAL_ 697 IcHuOnBoardCompState 1 "Enabled" 0 "Disabled" ;
VAL_ 697 IcHuIcInfoFeaturePresenceAck 1 "Present" 0 "Not Present" ;
VAL_ 697 IcHuAlertType 3 "Reserved" 2 "Reserved" 1 "Text Alert" 0 "Voice & Text Alert" ;
VAL_ 697 IcHuAlertStateStatus 1 "Active" 0 "Inactive" ;
VAL_ 697 IcHuAlertState 127 "Reserved for future" 126 "Reserved for future" 125 "Reserved for future" 124 "Reserved for future" 123 "Reserved for future" 122 "Reserved for future" 121 "Reserved for future" 120 "Reserved for future" 119 "Reserved for future" 118 "Reserved for future" 117 "Reserved for future" 116 "Reserved for future" 115 "Reserved for future" 114 "Reserved for future" 113 "Reserved for future" 112 "Reserved for future" 111 "Reserved for future" 110 "Reserved for future" 109 "Reserved for future" 108 "Reserved for future" 107 "Reserved for future" 106 "Reserved for future" 105 "Reserved for future" 104 "Reserved for future" 103 "Reserved for future" 102 "Reserved for future" 101 "Reserved for future" 100 "Reserved for future" 99 "Reserved for future" 98 "Reserved for future" 97 "Reserved for future" 96 "Reserved for future" 95 "Reserved for future" 94 "Reserved for future" 93 "Reserved for future" 92 "Reserved for future" 91 "Reserved for future" 90 "Reserved for future" 89 "Reserved for future" 88 "Reserved for future" 87 "Reserved for future" 86 "Reserved for future" 85 "Reserved for future" 84 "Reserved for future" 83 "Reserved for future" 82 "DDOA level 2 text2 voice alert" 81 "DDOA level 2 text1 voice alert" 80 "DDOA level 1 text voice alert" 79 "Battery Saver Mode Alert if SoC <30% " 78 "welcome message ev" 77 "charging status" 76 "battery low and user change gear to s mode" 75 "hand brake to be engaged (hand brake engaged during charging)" 74 "charge full" 73 "System de-energies" 72 "HV system fault, contact service center" 71 "Vehicle will shift to Neutral in next 5 mins for your Safety" 70 "HV system fault, please stop the vehicle & contact service center" 69 "EV charging update" 68 "Hazard on alert" 67 "Head lamps ON alert" 66 "Park lamps on alert" 65 "Engage Park brake + Take key fob out" 64 "Take key Fob out" 63 "Low Ambient Temperature / Its Already Cold Outside" 62 "Roll Up the windows if down" 61 "Express Cooling OFF, Roll Up the windows if down" 60 "Express Cooling ON windows may roll DOWN" 59 "Express Cooling OFF, Normal Cooling Mode ON" 58 "Express Cooling ON" 57 "Key Not Found" 56 "Cruise ON/Ready to Cruise" 55 "Fasten seat belt co-driver" 54 "Key Fob battery Low" 53 "Water in Fuel" 52 "Drive Alert1 - Tea Break" 51 "Fuel Level Low State" 50 "Engine Oil Pressure Low State" 49 "Fuel filter clogging" 48 "Service Reminder Kms" 47 "Service Reminder Days" 46 "Cruise Activated" 45 "Forward Collision Warning Indication" 44 "Pressure Leakage Alert Spare" 43 "Pressure Leakage Alert RR" 42 "Pressure Leakage Alert RL" 41 "Pressure Leakage Alert FR" 40 "Pressure Leakage Alert FL" 39 "HighTireTemp Alert Spare" 38 "HighTireTemp Alert RR" 37 "HighTireTemp Alert RL" 36 "HighTireTemp Alert FR" 35 "HighTireTemp Alert FL" 34 "High Tire Pressure Alert Spare" 33 "High Tire Pressure Alert RR" 32 "High Tire Pressure Alert RL" 31 "High Tire Pressure Alert FR" 30 "High Tire Pressure Alert FL" 29 "Low Tire Pressure Alert Spare" 28 "Low Tire Pressure Alert RR" 27 "Low Tire Pressure Alert RL" 26 "Low Tire Pressure Alert FR" 25 "Low Tire Pressure Alert FL" 24 "TPMS - General warning" 23 "Low SoC Indication" 22 "Low Brake Fluid" 21 "Park Brake Engaged" 20 "HDC Activated" 19 "HDC deactivated due to speed above set value" 18 "Fasten seat belt - Driver" 17 "Tail gate open" 16 "Rear left door open" 15 "Rear right door open" 14 "Co-Driver Door open" 13 "Driver Door open" 12 "Door open- General warning" 11 "Grass/Snow" 10 "Sand" 9 "Mud/Rust/Gravel" 8 "Wet/Rain Mode" 7 "Economy Mode" 6 "Sport Mode" 5 "City Mode" 4 "Rough Road Mode" 3 "Dynamic Mode" 2 "Comfort mode" 1 "Auto Mode" 0 "No Warning" ;
VAL_ 697 DriveAlert1_TeaBreak 1 "Tea Break Alert ON" 0 "Tea Break Alert OFF" ;
VAL_ 697 IcHuFuelTankCapacity 15 "Reserved" 14 "Reserved" 13 "Reserved" 12 "Reserved" 11 "Reserved" 10 "Reserved" 9 "Reserved" 8 "Reserved" 7 "42 litres" 6 "50 litres" 5 "35 litres" 4 "65 litres" 3 "60 litres" 2 "55 litres" 1 "44 litres" 0 "37 litres" ;
VAL_ 697 IcHuResetTripB 1 "Yes" 0 "No" ;
VAL_ 697 IcHuResetTripA 1 "Yes" 0 "No" ;
VAL_ 697 IcHuDriveType 1 "RHD" 0 "LHD" ;
VAL_ 698 IllumDimLvlSettingStatus 3 "Signal not available" 2 "Reserved" 1 "Reserved" 0 "Value is pluasible" ;
VAL_ 698 SwitchDimmingControlIPC 1 "Enable" 0 "Disable" ;
VAL_ 698 IllumOnOffCtrlStatus 3 "signal not available" 2 "Reserved" 1 "Reserved" 0 "value is plausible" ;
VAL_ 698 IllumOnOffCtrl 1 "illumination ON" 0 "illumination OFF" ;
VAL_ 698 SwitchDimmingControlIPCStatus 3 "Signal Not Available" 2 "Reserved for future use" 1 "Reserved for future use." 0 "Plausible and signal is correct" ;
VAL_ 699 CruiseSpeedChangeStateIPC 3 "Reserved" 2 "Cruise Speed Decrement" 1 "Cruise Speed Increment" 0 "No Change" ;
VAL_ 699 CruiseSwitchSelStatusIPC 3 "Signal is not available" 2 "Information given is implausible due to a detected failure " 1 "Reserved" 0 "Information given correct and according to specification" ;
VAL_ 699 CruiseSwitchSelStateIPC 15 "Reserved" 14 "Reserved" 13 "Reserved" 12 "Reserved" 11 "Reserved" 10 "Reserved" 9 "Reserved" 8 "Reserved" 7 "Reserved" 6 "Reserved" 5 "Cruise Selections not possible" 4 "Cruise Cancelled" 3 "Cruise Resumed" 2 "Cruise Activated" 1 "Cruise Set" 0 "Cruise OFF" ;
VAL_ 699 RegenSelectionSwStateIPC 3 "Level 3" 2 "Level 2" 1 "Level 1" 0 "Level 0" ;
VAL_ 699 RegenSelectionSwStatusIPC 3 "Signal Not Available" 2 "Implausible" 1 "Reserved" 0 "Plausible" ;
VAL_ 700 IPCRemoteCheckStatus 3 "Signal Not available" 2 "Signal is implausible" 1 "Reserved" 0 "Signal is correct" ;
VAL_ 700 IPCRemoteCheck 3 "Reserved" 2 "IPC Remote AC & Engine Pre-condition check failed." 1 "IPC Remote AC & Engine Pre-condition check passed." 0 "Default State/Remote Command not requested" ;
VAL_ 700 IcHuIceState 3 "Reserved for future use" 2 "Reserved for future use" 1 "Text Warning  is On" 0 "Text Warning is Off" ;
VAL_ 700 IcHuBrakeFluidLowState 3 "Reserved for future use" 2 "Lamp is ON" 1 "Lamp is Flashing" 0 "Lamp is Off" ;
VAL_ 700 IcHuFastenSeatBeltState 3 "Reserved for future use" 2 "Reserved for future use" 1 "Text Warning  is On" 0 "Text Warning is Off" ;
VAL_ 700 IcHuEngSystemFaultState 3 "Reserved for future use" 2 "Reserved for future use" 1 "Text Warning  is On" 0 "Text Warning is Off" ;
VAL_ 700 IcHuEngRestrictedPerformanceStat 3 "Reserved for future use" 2 "Reserved for future use" 1 "Text Warning  is On" 0 "Text Warning is Off" ;
VAL_ 700 IcHuBatteryChargingState 3 "Reserved for future use" 2 "Lamp is ON" 1 "Lamp is Flashing" 0 "Lamp is Off" ;
VAL_ 700 IcHuFuelLevelLowState 3 "Reserved for future use" 2 "Lamp is ON" 1 "Lamp is Flashing" 0 "Lamp is Off" ;
VAL_ 700 IcHuEngineOilPressureLowState 3 "Reserved for future use" 2 "Lamp is ON" 1 "Lamp is Flashing" 0 "Lamp is Off" ;
VAL_ 700 NextServDueAlert 1 "Next service is due" 0 "Next Service is not due" ;
VAL_ 700 NextServDueAlertStatus 3 "Reserved" 2 "Plausible" 1 "Reserved" 0 "Signal Not available" ;
VAL_ 702 IcHuOnBoardCompState 1 "Enabled" 0 "Disabled" ;
VAL_ 702 IcHuIcInfoFeaturePresenceAck 1 "Present" 0 "Not Present" ;
VAL_ 702 IcHuAlertStateStatus 1 "Active" 0 "Inactive" ;
VAL_ 702 IcHuAlertType 3 "Reserved" 2 "Reserved" 1 "Text Alert" 0 "Voice & Text Alert" ;
VAL_ 702 DriveAlert1_TeaBreak 1 "Tea Break Alert ON" 0 "Tea Break Alert OFF" ;
VAL_ 702 IcHuAlertState 127 "Reserved for future" 126 "Reserved for future" 125 "Reserved for future" 124 "Reserved for future" 123 "Reserved for future" 122 "Reserved for future" 121 "Reserved for future" 120 "Reserved for future" 119 "Reserved for future" 118 "Reserved for future" 117 "Reserved for future" 116 "Reserved for future" 115 "Reserved for future" 114 "Reserved for future" 113 "Reserved for future" 112 "Reserved for future" 111 "Reserved for future" 110 "Reserved for future" 109 "Reserved for future" 108 "Reserved for future" 107 "Reserved for future" 106 "Reserved for future" 105 "Reserved for future" 104 "Reserved for future" 103 "Reserved for future" 102 "Reserved for future" 101 "Reserved for future" 100 "Reserved for future" 99 "Reserved for future" 98 "Reserved for future" 97 "Reserved for future" 96 "Reserved for future" 95 "Reserved for future" 94 "Reserved for future" 93 "Reserved for future" 92 "Reserved for future" 91 "Reserved for future" 90 "Reserved for future" 89 "Reserved for future" 88 "Reserved for future" 87 "Reserved for future" 86 "Reserved for future" 85 "Reserved for future" 84 "Reserved for future" 83 "Malfunction detected, Please safely park the vehicle and Exit immediately" 82 "DDOA level 2 text2 voice alert" 81 "DDOA level 2 text1 voice alert" 80 "DDOA level 1 text voice alert" 79 "Battery Saver Mode Alert if SoC <30% " 78 "welcome message ev" 77 "charging status" 76 "battery low and user change gear to s mode" 75 "hand brake to be engaged (hand brake engaged during charging)" 74 "charge full" 73 "System de-energies" 72 "HV system fault, contact service center" 71 "Vehicle will shift to Neutral in next 5 mins for your Safety" 70 "HV system fault, please stop the vehicle & contact service center" 69 "EV charging update" 68 "Hazard on alert" 67 "Head lamps ON alert" 66 "Park lamps on alert" 65 "Engage Park brake + Take key fob out" 64 "Take key Fob out" 63 "Low Ambient Temperature / Its Already Cold Outside" 62 "Roll Up the windows if down" 61 "Express Cooling OFF, Roll Up the windows if down" 60 "Express Cooling ON windows may roll DOWN" 59 "Express Cooling OFF, Normal Cooling Mode ON" 58 "Express Cooling ON" 57 "Key Not Found" 56 "Cruise ON/Ready to Cruise" 55 "Fasten seat belt co-driver" 54 "Key Fob battery Low" 53 "Water in Fuel" 52 "Drive Alert1 - Tea Break" 51 "Fuel Level Low State" 50 "Engine Oil Pressure Low State" 49 "Fuel filter clogging" 48 "Service Reminder Kms" 47 "Service Reminder Days" 46 "Cruise Activated" 45 "Forward Collision Warning Indication" 44 "Pressure Leakage Alert Spare" 43 "Pressure Leakage Alert RR" 42 "Pressure Leakage Alert RL" 41 "Pressure Leakage Alert FR" 40 "Pressure Leakage Alert FL" 39 "HighTireTemp Alert Spare" 38 "HighTireTemp Alert RR" 37 "HighTireTemp Alert RL" 36 "HighTireTemp Alert FR" 35 "HighTireTemp Alert FL" 34 "High Tire Pressure Alert Spare" 33 "High Tire Pressure Alert RR" 32 "High Tire Pressure Alert RL" 31 "High Tire Pressure Alert FR" 30 "High Tire Pressure Alert FL" 29 "Low Tire Pressure Alert Spare" 28 "Low Tire Pressure Alert RR" 27 "Low Tire Pressure Alert RL" 26 "Low Tire Pressure Alert FR" 25 "Low Tire Pressure Alert FL" 24 "TPMS - General warning" 23 "Low SoC Indication" 22 "Low Brake Fluid" 21 "Park Brake Engaged" 20 "HDC Activated" 19 "HDC deactivated due to speed above set value" 18 "Fasten seat belt - Driver" 17 "Tail gate open" 16 "Rear left door open" 15 "Rear right door open" 14 "Co-Driver Door open" 13 "Driver Door open" 12 "Door open- General warning" 11 "Grass/Snow" 10 "Sand" 9 "Mud/Rust/Gravel" 8 "Wet/Rain Mode" 7 "Economy Mode" 6 "Sport Mode" 5 "City Mode" 4 "Rough Road Mode" 3 "Dynamic Mode" 2 "Comfort mode" 1 "Auto Mode" 0 "No Warning" ;
VAL_ 704 GpsCompassPresence 1 "Compass information not available" 0 "Compass information available" ;
VAL_ 704 GPsCourseInfoStatusIVI 3 "Signal Not Available" 2 "Signal value is implausible" 1 "Reserved for future use." 0 "Plausible  - Information given is correct and according to specification" ;
VAL_ 704 HuEMsRegenReqStatus 3 "Not Supported / Signal Not Available" 2 "Signal is implausible" 1 "Reserved for future use" 0 "Signal is Correct" ;
VAL_ 704 HuEMsRegenReq 3 "DPFRegen Request is Cancelled by User" 2 "DPFRegen Request is confirmed by user" 1 "DPFRegen request  is initiated by user" 0 "No DPFRegen Request" ;
VAL_ 704 HuCcmRearBlwrOnOffReq 1 "Rear Blower ON" 0 "Rear Blower OFF" ;
VAL_ 704 StuckModeUserResponse 3 "User Turned Off Stuck Mode" 2 "User Ignored Stuck Mode Activation request" 1 "User made stuck mode ON" 0 "No Action" ;
VAL_ 704 HuIcDistanceDisplayUnitEnum 7 "Reserved" 6 "Reserved" 5 "Reserved" 4 "Feet" 3 "Yards" 2 "Meter" 1 "Miles" 0 "Kilo Metre" ;
VAL_ 704 HuPresence 1 "Reserved" 0 "HU Present" ;
VAL_ 704 HuPlatformVariant 20 "Gen3_High+" 19 "Gen3_High" 18 "Gen3_Mid+" 17 "Gen3_Mid" 16 "HU_High_X445" 15 "HU_Mid_X445" 14 "X0_Level_A_VaVe" 13 "HU_7" 12 "HU_High_X451" 11 "HU_Mid_X451" 10 "HU_High_Q5" 9 "HU_Mid_Q5" 8 "HU_Low_Q5" 7 "Gen1+ Level B" 6 "Gen1+ Level A" 5 "Level B Eagle" 4 "Hexa_HU_7_VaVe" 3 "Nexon_Level_B_VaVe" 2 "Nexon_Level_A_VaVe" 1 "Lavel B" 0 "Level A" ;
VAL_ 704 SbIcDispState 3 "Reserved" 2 "SbIcDispActive" 1 "SbIcDispStandBy" 0 "SbIcDispSwitchOff" ;
VAL_ 704 TpmsEnterLearning 3 "Signal is Invalid" 2 "TPMS to Enter Into Learning Mode" 1 "Reserved" 0 "Normal Mode" ;
VAL_ 704 HuIcAlertStatusAck 7 "Error" 6 "Aborted" 5 "Ignored" 4 "Delivered" 3 "In Process" 2 "In Queue" 1 "Received" 0 "No Alert" ;
VAL_ 704 HuIcAlertStateAck 126 "Reserved for future" 125 "Reserved for future" 124 "Reserved for future" 123 "Reserved for future" 122 "Reserved for future" 121 "Reserved for future" 120 "Reserved for future" 119 "Reserved for future" 118 "Reserved for future" 117 "Reserved for future" 116 "Reserved for future" 115 "Reserved for future" 114 "Reserved for future" 113 "Reserved for future" 112 "Reserved for future" 111 "Reserved for future" 110 "Reserved for future" 109 "Reserved for future" 108 "Reserved for future" 107 "Reserved for future" 106 "Reserved for future" 105 "Reserved for future" 104 "Reserved for future" 103 "Reserved for future" 102 "Reserved for future" 101 "Reserved for future" 100 "Reserved for future" 99 "Reserved for future" 98 "Reserved for future" 97 "Reserved for future" 96 "Reserved for future" 95 "Reserved for future" 94 "Reserved for future" 93 "Reserved for future" 92 "Reserved for future" 91 "Reserved for future" 90 "Reserved for future" 89 "Reserved for future" 88 "Reserved for future" 87 "Reserved for future" 86 "Reserved for future" 85 "Reserved for future" 84 "Reserved for future" 83 "Malfunction detected, Please safely park the vehicle and Exit immediately" 82 "DDOA level 2 text2 voice alert" 81 "DDOA level 2 text1 voice alert" 80 "DDOA level 1 text voice alert" 79 "Battery Saver Mode Alert if SoC <30% " 78 "welcome message ev" 77 "charging status" 76 "battery low and user change gear to s mode" 75 "hand brake to be engaged (hand brake engaged during charging)" 74 "charge full" 73 "System de-energies" 72 "HV system fault, contact service center" 71 "Vehicle will shift to Neutral in next 5 mins for your Safety" 70 "HV system fault, please stop the vehicle & contact service center" 69 "EV charging update" 68 "Hazard on alert" 67 "Head lamps ON alert" 66 "Park lamps on alert" 65 "Engage Park brake + Take key fob out" 64 "Take key Fob out" 63 "Low Ambient Temperature / Its Already Cold Outside" 62 "Roll Up the windows if down" 61 "Express Cooling OFF, Roll Up the windows if down" 60 "Express Cooling ON windows may roll DOWN" 59 "Express Cooling OFF, Normal Cooling Mode ON" 58 "Express Cooling ON" 57 "Key Not Found" 56 "Cruise ON/Ready to Cruise" 55 "Fasten seat belt co-driver" 54 "Key Fob battery Low" 53 "Water in Fuel" 52 "Drive Alert1 - Tea Break" 51 "Fuel Level Low State" 50 "Engine Oil Pressure Low State" 49 "Fuel filter clogging" 48 "Service Reminder Kms" 47 "Service Reminder Days" 46 "Cruise Activated" 45 "Forward Collision Warning Indication" 44 "Pressure Leakage Alert Spare" 43 "Pressure Leakage Alert RR" 42 "Pressure Leakage Alert RL" 41 "Pressure Leakage Alert FR" 40 "Pressure Leakage Alert FL" 39 "High Tire Pressure Alert Spare" 38 "HighTireTemp Alert RR" 37 "HighTireTemp Alert RL" 36 "HighTireTemp Alert FR" 35 "HighTireTemp Alert FL" 34 "High Tire Pressure Alert Spare" 33 "High Tire Pressure Alert RR" 32 "High Tire Pressure Alert RL" 31 "High Tire Pressure Alert FR" 30 "High Tire Pressure Alert FL" 29 "Low Tire Pressure Alert Spare" 28 "Low Tire Pressure Alert RR" 27 "Low Tire Pressure Alert RL" 26 "Low Tire Pressure Alert FR" 25 "Low Tire Pressure Alert FL" 24 "TPMS - General warning" 23 "Low SoC Indication" 22 "Low Brake Fluid" 21 "Park Brake Engaged" 20 "HDC Activated" 19 "HDC deactivated due to speed above set value" 18 "Fasten seat belt - Driver" 17 "Tail gate open" 16 "Rear left door open" 15 "Rear right door open" 14 "Co-Driver Door open" 13 "Driver Door open" 12 "Door open- General warning" 11 "Grass/Snow" 10 "Sand" 9 "Mud/Rust/Gravel" 8 "Wet/Rain Mode" 7 "Economy Mode" 6 "Sport Mode" 5 "City Mode" 4 "Rough Road Mode" 3 "Dynamic Mode" 2 "Comfort mode" 1 "Auto Mode" 0 "No Warning" ;
VAL_ 706 HuIcNaviSource 3 "Reserved" 2 "Car Play" 1 "Android Auto" 0 "Reserved" ;
VAL_ 706 HuIcCarPlayManeuverType 63 "Reserved" 62 "Reserved" 61 "Reserved" 60 "Reserved" 59 "Reserved" 58 "Reserved" 57 "Reserved" 56 "Reserved" 55 "Reserved" 54 "Reserved" 53 "Change Highway Right. Highway to highway change from the right side of the road" 52 "Change Highway Left. Highway to highway change from the left side of the road" 51 "Change Highway. Highway to highway change with implied or unknown side of the road" 50 "Slight Right Turn. Turn on to a different road (compare to Keep Right)" 49 "Slight Left Turn.Turn on to a different road (compare to Keep Left)" 48 "Sharp Right Turn. Angle is between 135° and 180°" 47 "Sharp Left Turn. Angle is between -135° and -180°" 46 "Round about Exit19. Exit the round about at the 19th street" 45 "Round about Exit18. Exit the round about at the 18th street" 44 "Round about Exit17. Exit the round about at the 17th street" 43 "Round about Exit16. Exit the round about at the 16th street" 42 "Round about Exit15. Exit the round about at the 15th street" 41 "Round about Exit14. Exit the round about at the 14th street" 40 "Round about Exit13. Exit the round about at the 13th street" 39 "Round about Exit12. Exit the round about at the 12th street" 38 "Round about Exit11. Exit the round about at the 11th street" 37 "Round about Exit10. Exit the round about at the 10th street" 36 "Round about Exit9. Exit the round about at the 9th street" 35 "Round about Exit8. Exit the round about at the 8th street" 34 "Round about Exit7. Exit the round about at the 7thstreet" 33 "Round about Exit6. Exit the round about at the 6th street" 32 "Round about Exit5. Exit the round about at the 5th street" 31 "Round about Exit4. Exit the round about at the 4th street" 30 "Round about Exit3. Exit the round about at the 3rd street" 29 "Round about Exit2. Exit the round about at the 2nd street" 28 "Round about Exit1. Exit the round about at the 1st street" 27 "Arrive End Of Directions. Navigation has completed, but the rest of the journey will need to use another transport method" 26 "Make a U-turn when possible" 25 "Arrive At Destination Right. Destination has been reached; it is on the right and navigation will end" 24 "Arrive At Destination Left. Destination has been reached; it is on the left and navigation will end" 23 "Highway Off Ramp Right. Exit the highway on the right" 22 "Highway Off Ramp Left. Exit the highway on the left" 21 "At the end of the road,turn right" 20 "At the end of the road,turn left" 19 "Use the roundabout to make a U-turn" 18 "Make a U-turn and proceed to the route" 17 "Change to a different ferry" 16 "Exit Ferry" 15 "Enter Ferry" 14 "Keep Right. Usually for bifurcations or other smooth maneuvers (compare to Slight Right Turn)" 13 "Keep Left. Usually for bifurcations or other smooth maneuvers (compare to Slight Left Turn)" 12 "Arrive At destination. Destination has beed reached , navigation will end" 11 "Proceed to the beginning of the route" 10 "Arrive End of Navigation has completed , but the rest of the journey will need to use another transport method" 9 "On Ramp. Take the ramp to merge onto the highway" 8 "Off Ramp. Take the ramp to leave the highway" 7 "Exit Roundabout" 6 "Enter Roundabout" 5 "Continue to follow the road the vehilce is currently on" 4 "Make a U-turn" 3 "StraightAhead. Continue straight through the intersection (implies a road name will change)" 2 "RightTurn.Angleisbetween 45°and 135°" 1 "LeftTurn.Angleisbetween -45°and-135°" 0 "NoTurn(default value)" ;
VAL_ 706 HuIcNextTurnSideEnum 31 "Reserved" 30 "Reserved" 29 "Reserved" 28 "Reserved" 27 "Reserved" 26 "Reserved" 25 "Reserved" 24 "Reserved" 23 "Reserved" 22 "Reserved" 21 "Reserved" 20 "Reserved" 19 "Reserved" 18 "Reserved" 17 "Reserved" 16 "Destination" 15 "Ferry Train" 14 "Ferry Boat" 13 "Straight" 12 "Round about Enter and Exit" 11 "Roundabout exit" 10 "Roundabout enter" 9 "Merge" 8 "Fork" 7 "Off Ramp" 6 "On Ramp" 5 "U Turn" 4 "Sharp Turn" 3 "Turn" 2 "Slight Turn" 1 "Name Change" 0 "Depart" ;
VAL_ 706 HuIcNextTurnRoundDistUnits 3 "Kilo Miles" 2 "Miles" 1 "Kilo Metre" 0 "Metre" ;
VAL_ 706 HuIcNaviStatus 3 "Reserved" 2 "Active" 1 "Inactive" 0 "Unavailable" ;
VAL_ 706 HuIcNextTurnSide 3 "Reserved" 2 "Left" 1 "Right" 0 "Unspecified" ;
VAL_ 706 HuIcRoundAboutType 15 "Reserved" 14 "Reserved" 13 "Reserved" 12 "Reserved" 11 "Reserved" 10 "Reserved" 9 "Reserved" 8 "Reserved" 7 "Roundabout Exit 8. Exit the roundabout at the 8th street " 6 "Roundabout Exit 7. Exit the roundabout at the 7th street " 5 "Roundabout Exit 6. Exit the roundabout at the 6th street " 4 "Roundabout Exit 5. Exit the roundabout at the 5th street " 3 "Roundabout Exit 4. Exit the roundabout at the 4th street " 2 "Roundabout Exit 3. Exit the roundabout at the 3rd  street " 1 "Roundabout Exit 2. Exit the roundabout at the 2nd street " 0 "Roundabout Exit 1. Exit the roundabout at the 1st street " ;
VAL_ 706 HuIcColorStatus 7 "Reserved" 6 "Reserved" 5 "Reserved" 4 "Orange" 3 "Pink" 2 "Red" 1 "Green" 0 "Blue" ;
VAL_ 707 LinSwcSbPowerModeCan 3 "Reserved" 2 "SwcActive" 1 "SwcSwitchOff" 0 "SwcUnpowered" ;
VAL_ 707 LinSwcIcKey9Can 7 "Reserved" 6 "Reserved" 5 "Reserved" 4 "Reserved" 3 "Key stuck" 2 "Long Pressed" 1 "Pressed" 0 "Not Pressed" ;
VAL_ 707 LinSwcIcKey8Can 7 "Reserved" 6 "Reserved" 5 "Reserved" 4 "Reserved" 3 "Key stuck" 2 "Long Pressed" 1 "Pressed" 0 "Not Pressed" ;
VAL_ 707 LinSwcIcKey7Can 7 "Reserved" 6 "Reserved" 5 "Reserved" 4 "Reserved" 3 "Key stuck" 2 "Long Pressed" 1 "Pressed" 0 "Not Pressed" ;
VAL_ 707 LinSwcIcKey6Can 7 "Reserved" 6 "Reserved" 5 "Reserved" 4 "Reserved" 3 "Key stuck" 2 "Long Pressed" 1 "Pressed" 0 "Not Pressed" ;
VAL_ 707 LinSwcIcViewCan 7 "Reserved" 6 "Reserved" 5 "Reserved" 4 "Reserved" 3 "Key stuck" 2 "Long Pressed" 1 "Pressed" 0 "Not Pressed" ;
VAL_ 707 LinSwcIcMenuSelectCan 7 "Reserved" 6 "Reserved" 5 "Reserved" 4 "Reserved" 3 "Key stuck" 2 "Long Pressed" 1 "Pressed" 0 "Not Pressed" ;
VAL_ 707 LinSwcIcMenuDownCan 7 "Reserved" 6 "Reserved" 5 "Reserved" 4 "Reserved" 3 "Key stuck" 2 "Long Pressed" 1 "Pressed" 0 "Not Pressed" ;
VAL_ 707 LinSwcIcMenuUpCan 7 "Reserved" 6 "Reserved" 5 "Reserved" 4 "Reserved" 3 "Key stuck" 2 "Long Pressed" 1 "Pressed" 0 "Not Pressed" ;
VAL_ 707 LinSwcIcpaginationCan 7 "Reserved" 6 "Reserved" 5 "Reserved" 4 "Reserved" 3 "Key stuck" 2 "Long Pressed" 1 "Pressed" 0 "Not Pressed" ;
VAL_ 707 LinSwcPresenceCanStatus 3 "Signal not available" 2 "Value is implausible" 1 "Reserved" 0 "Value is plausible" ;
VAL_ 707 LinSwcIcVariant 7 "Reserved" 6 "Reserved" 5 "9 Switch LIN" 4 "9 Switch Analog" 3 "5 Switch LIN" 2 "4 Switch LIN" 1 "5 Switch Analog" 0 "4 Switch Analog" ;
VAL_ 707 LinSwcPresenceCan 1 "Present" 0 "Not Present" ;
VAL_ 707 HuIcVoiceAlertStatusAck 7 "Error" 6 "Aborted" 5 "Ignored" 4 "Delivered" 3 "In Process" 2 "In Queue" 1 "Received" 0 "No Alert" ;
VAL_ 707 HuIcVoiceAlertStateAck 26 "Smart key out of range" 25 "Key Fob battery Low" 24 "Service Remainder" 23 "Water in Fuel" 22 "Low Oil Pressure" 21 "Low Brake fluid" 20 "Low fuel warning" 19 "Rear Left Tyre Pressure Monitoring" 18 "Rear Right Tyre Pressure Monitoring" 17 "Front Left Tyre Pressure Monitoring" 16 "Front Right Tyre Pressure Monitoring" 15 "Park Brake ON" 14 "Driver Seat Belt Remainder" 13 "Tail Gate open" 12 "Rear Left door open" 11 "Rear Right door open" 10 "Co Driver Door open" 9 "Driver Door Open" 8 "Door Open - general warning" 7 "Economy Mode" 6 "Sport Mode" 5 "Normal/City Mode" 4 "Rough Road Mode" 3 "Dynamic Mode" 2 "Comfort Mode" 1 "Auto Mode" 0 "No Warning" ;
VAL_ 708 SbCurrentAudioSource 15 "Reserved" 14 "Reserved" 13 "Reserved" 12 "Reserved" 11 "Reserved" 10 "Reserved" 9 "Reserved" 8 "Reserved" 7 "Reserved" 6 "Bluetooth Audio Streaming" 5 "AUX" 4 "SD Card" 3 "USB" 2 "FM" 1 "AM" 0 "Media Off" ;
VAL_ 708 DispVariant 15 "Reserved" 14 "Reserved" 13 "Reserved" 12 "Reserved" 11 "Reserved" 10 "Gen3 High+ 12.3 Inch  Infotainment + 10.25 Inch IC" 9 "Gen3 High 10.25 Inch Infotainment + 10.25 Inch IC" 8 "Gen3 Mid+ 10.25 Inch" 7 "Gen3 Mid 10.25 Inch" 6 "X451 7 Inch TFT Display" 5 "X451 3.5 Inch Monochrome Display" 4 "Q5 8.8 Inch TFT Display" 3 "Q5 7 Inch TFT Display" 2 "Q5 5.5 Inch TFT Display" 1 "X 104 TFT Display" 0 "X 104 Monochrome Display" ;
VAL_ 708 SbPowerModeConfig 1 "PEPS Type" 0 "Ign Lock Type" ;
VAL_ 708 SbCurrentPowerMode 7 "Reserved" 6 "Reserved" 5 "Crank" 4 "Static" 3 "Standby" 2 "S2R" 1 "SbActive Mode" 0 "SbMediaOff Mode" ;
VAL_ 708 BpVariant 15 "Reserved" 14 "Reserved" 13 "Reserved" 12 "Reserved" 11 "Reserved" 10 "Reserved" 9 "Reserved" 8 "Reserved" 7 "Reserved" 6 "Reserved" 5 "Reserved" 4 "Reserved" 3 "Reserved" 2 "X451  ButtonPanel" 1 "Q5  ButtonPanel" 0 "X 104 Button Panel" ;
VAL_ 708 DispCurrentPowerMode 7 "Reserved" 6 "Reserved" 5 "Reserved" 4 "Reserved" 3 "Reserved" 2 "DispActive Mode" 1 "DispStandBy Mode" 0 "DisplSwitchOff Mode" ;
VAL_ 708 BpCurrentPowerMode 7 "Reserved" 6 "Reserved" 5 "Reserved" 4 "Reserved" 3 "Reserved" 2 "Reserved" 1 "BpActive Mode" 0 "BpSwitchOff Mode" ;
VAL_ 708 BpPresence 3 "Reserved" 2 "Reserved" 1 "Present" 0 "Absence" ;
VAL_ 708 DispPresence 3 "Reserved" 2 "Reserved" 1 "Present" 0 "Absence" ;
VAL_ 710 PDcHuFaultState 31 "Reserved for future use." 30 "Reserved for future use." 29 "Reserved for future use." 28 "Reserved for future use." 27 "Reserved for future use." 26 "Reserved for future use." 25 "Reserved for future use." 24 "Reserved for future use." 23 "Reserved for future use." 22 "Reserved for future use." 21 "Reserved for future use." 20 "Reserved for future use." 19 "Reserved for future use." 18 "Reserved for future use." 17 "Reserved for future use." 16 "Reserved for future use." 15 "Reserved for future use." 14 "Reserved for future use." 13 "Reserved for future use." 12 "Reserved for future use." 11 " Reserved for future use." 10 "Reserved for future use." 9 "Reserved for future use." 8 "Reserved for future use." 7 " Park Brake Engaged" 6 "Tailgate Open" 5 "Minor Fault" 4 "Too much Noisy environment " 3 "Vehicle Speed too High		
" 2 "Trailer Connected" 1 " Critical fault" 0 "No Fault" ;
VAL_ 710 PDcHuAudioZoneState 7 "Reserved for future use." 6 "Reserved for future use." 5 "Reserved for future use." 4 "Reserved for future use." 3 "Continuous Beep" 2 "Fast Beep" 1 "Slow Beep" 0 "No Audio" ;
VAL_ 710 PDcHuVisualZoneRearLHSensState 15 "Reserved for future use." 14 "Reserved for future use." 13 "Reserved for future use." 12 "Reserved for future use." 11 "Reserved for future use." 10 "Reserved for future use." 9 "Reserved for future use." 8 "Reserved for future use." 7 "Reserved for future use." 6 "Zone 6" 5 "Zone 5" 4 "Zone 4" 3 "Zone 3" 2 "Zone 2" 1 "Zone 1" 0 "No Obstacle" ;
VAL_ 710 PDcHuVisualZoneRearMidRHSensStat 15 "Reserved for future use." 14 "Reserved for future use." 13 "Reserved for future use." 12 "Reserved for future use." 11 "Reserved for future use." 10 "Reserved for future use." 9 "Reserved for future use." 8 "Reserved for future use." 7 "Reserved for future use." 6 "Zone 6" 5 "Zone 5" 4 "Zone 4" 3 "Zone 3" 2 "Zone 2" 1 "Zone 1" 0 "No Obstacle" ;
VAL_ 710 PDcHuVisualZoneRearRHSensState 15 "Reserved for future use." 14 "Reserved for future use." 13 "Reserved for future use." 12 "Reserved for future use." 11 "Reserved for future use." 10 "Reserved for future use." 9 "Reserved for future use." 8 "Reserved for future use." 7 "Reserved for future use." 6 "Zone 6" 5 "Zone 5" 4 "Zone 4" 3 "Zone 3" 2 "Zone 2" 1 "Zone 1" 0 "No Obstacle" ;
VAL_ 710 PDcHuVisualZoneRearMidLHSensStat 15 "Reserved for future use." 14 "Reserved for future use." 13 "Reserved for future use." 12 "Reserved for future use." 11 "Reserved for future use." 10 "Reserved for future use." 9 "Reserved for future use." 8 "Reserved for future use." 7 "Reserved for future use." 6 "Zone 6" 5 "Zone 5" 4 "Zone 4" 3 "Zone 3" 2 "Zone 2" 1 "Zone 1" 0 "No Obstacle" ;
VAL_ 710 PDcPresence 1 "Reserved" 0 "PDC Present" ;
VAL_ 710 PDcHuState 1 "Active" 0 "Inactive" ;
VAL_ 710 PDcHuPwrModeState 15 "Reserved" 14 "Reserved" 13 "Reserved" 12 "Reserved" 11 "Reserved" 10 "Reserved" 9 "Reserved" 8 "Reserved" 7 "Reserved" 6 "Reserved" 5 "PDC Active (reverse to forward)" 4 "Front active" 3 "Pre-active " 2 "PDcTimer" 1 "PDcActive" 0 "PDcStandBy" ;
VAL_ 710 PDcVariant 3 "Reserved for future use" 2 "Front Only" 1 "Front & Rear" 0 "Rear Only" ;
VAL_ 710 PDcHuVisualZoneFrontLHSensState 15 "Reserved for future use." 14 "Reserved for future use." 13 "Reserved for future use." 12 "Reserved for future use." 11 "Reserved for future use." 10 "Reserved for future use." 9 "Reserved for future use." 8 "Reserved for future use." 7 "Reserved for future use." 6 "Zone 6" 5 "Zone 5" 4 "Zone 4" 3 "Zone 3" 2 "Zone 2" 1 "Zone 1" 0 "No Obstacle" ;
VAL_ 710 PDcHuVisualZoneFrontMidLHSensSta 15 "Reserved for future use." 14 "Reserved for future use." 13 "Reserved for future use." 12 "Reserved for future use." 11 "Reserved for future use." 10 "Reserved for future use." 9 "Reserved for future use." 8 "Reserved for future use." 7 "Reserved for future use." 6 "Zone 6" 5 "Zone 5" 4 "Zone 4" 3 "Zone 3" 2 "Zone 2" 1 "Zone 1" 0 "No Obstacle" ;
VAL_ 710 PDcHuVisualZoneFrontMidRHSensSta 15 "Reserved for future use." 14 "Reserved for future use." 13 "Reserved for future use." 12 "Reserved for future use." 11 "Reserved for future use." 10 "Reserved for future use." 9 "Reserved for future use." 8 "Reserved for future use." 7 "Reserved for future use." 6 "Zone 6" 5 "Zone 5" 4 "Zone 4" 3 "Zone 3" 2 "Zone 2" 1 "Zone 1" 0 "No Obstacle" ;
VAL_ 710 PDcHuVisualZoneFrontRHSensState 15 "Reserved for future use." 14 "Reserved for future use." 13 "Reserved for future use." 12 "Reserved for future use." 11 "Reserved for future use." 10 "Reserved for future use." 9 "Reserved for future use." 8 "Reserved for future use." 7 "Reserved for future use." 6 "Zone 6" 5 "Zone 5" 4 "Zone 4" 3 "Zone 3" 2 "Zone 2" 1 "Zone 1" 0 "No Obstacle" ;
VAL_ 710 PDcHuFrontAudioZoneState 7 "Reserved for future use." 6 "Reserved for future use." 5 "Reserved for future use." 4 "Reserved for future use." 3 "Continuous Beep" 2 "Fast Beep" 1 "Slow Beep" 0 "No Audio" ;
VAL_ 710 PDcHuFrontFaultState 31 "Reserved for future use." 30 "Reserved for future use." 29 "Reserved for future use." 28 "Reserved for future use." 27 "Reserved for future use." 26 "Reserved for future use." 25 "Reserved for future use." 24 "Reserved for future use." 23 "Reserved for future use." 22 "Reserved for future use." 21 "Reserved for future use." 20 "Reserved for future use." 19 "Reserved for future use." 18 "Reserved for future use." 17 "Reserved for future use." 16 "Reserved for future use." 15 "Reserved for future use." 14 "Reserved for future use." 13 "Reserved for future use." 12 "Reserved for future use." 11 " Reserved for future use." 10 "Reserved for future use." 9 "Reserved for future use." 8 "Reserved for future use." 7 "Reserved for future use." 6 "Reserved for future use." 5 "Reserved for future use." 4 "Reserved for future use." 3 "Reserved for future use." 2 "Too much Noisy environment " 1 " Critical fault" 0 "No Fault" ;
VAL_ 710 PDcHuFrontState 1 "Active" 0 "Inactive" ;
VAL_ 710 PDcIPcFrontActive 1 "Enable" 0 "Disable" ;
VAL_ 710 PDcIPcRearActive 1 "Enable" 0 "Disable" ;
VAL_ 711 PDcHuProxFrontRHSensStateStatus 3 "Signal  PDcHuProxFrontRHSensState not available. " 2 "Information given at PDcHuProxFrontRHSensState is implausible." 1 "Reserved for future use." 0 "Information given at PDcHuProxFrontRHSensState is correct and according to specification " ;
VAL_ 711 PDcHuProxFrontMidRHSensStateStat 3 "Signal  PDcHuProxFrontMidRHSensState not available  " 2 "Information given at PDcHuProxFrontMidRHSensState is implausible" 1 "Reserved for future use." 0 "Information given atPDcHuProxFrontMidRHSensState is correct and according to specification " ;
VAL_ 711 PDcHuProxFrontMidLHSensStateStat 3 "Signal  PDcHuProxFrontMidLHSensState not available  " 2 "Information given at PDcHuProxFrontMidLHSensState is implausible" 1 "Reserved for future use." 0 "Information given at PDcHuProxFrontMidLHSensState is correct and according to specification " ;
VAL_ 711 PDcHuProxFrontLHSensStateStatus 3 "Signal  PDcHuProxFrontLHSensState  not available  " 2 "Information given at PDcHuProxFrontLHSensState is implausible" 1 "Reserved for future use." 0 "Information given at PDcHuProxFrontLHSensStateis correct and according to specification " ;
VAL_ 712 PDcHuProxRearRHSensStateStatus 3 "signal not available" 2 "value is implausible" 1 "Reserved" 0 "value is plausible" ;
VAL_ 712 PDcHuProxRearMidRHSensStateStatu 3 "signal not available" 2 "value is implausible" 1 "Reserved" 0 "value is plausible" ;
VAL_ 712 PDcHuProxRearMidLHSensStateStatu 3 "signal not available" 2 "value is implausible" 1 "Reserved" 0 "value is plausible" ;
VAL_ 712 PDcHuProxRearLHSensStateStatus 3 "signal not available" 2 "value is implausible" 1 "Reserved" 0 "value is plausible" ;
VAL_ 713 HuIcMediaState 15 "Reserved" 14 "Reserved" 13 "Reserved" 12 "Reserved" 11 "Reserved" 10 "Reserved" 9 "Reserved" 8 "Tuner Scan State" 7 "Tuner Auto Store" 6 "Reverse Seeking" 5 "Forward seeking" 4 "Fast Reverse" 3 "Fast Forward" 2 "Play" 1 "Pause" 0 "Stop" ;
VAL_ 713 HuIcSource 31 "Reserved for future" 30 "Reserved for future" 29 "Reserved for future" 28 "Reserved for future" 27 "Reserved for future" 26 "Reserved for future" 25 "Media OFF" 24 "Alexa SiriusXM" 23 "Alexa ideezer" 22 "Alexa Pandora" 21 "Alexa iHeartRadio" 20 "Alexa TuneIN" 19 "Alexa Spotify" 18 "Alexa Kindle" 17 "Alexa Audible" 16 "Alexa Amazon music" 15 "CarPlay VR" 14 "Android Auto VR" 13 "Alexa VR" 12 "Voice recognition" 11 "SMS Read Out" 10 "CarPlay Audio" 9 "Android Auto Audio" 8 "Phone" 7 "Bluetooth Audio" 6 "Aux" 5 "DRM" 4 "FM" 3 "AM" 2 "iPod" 1 "USB" 0 "No Device" ;
VAL_ 713 HuIcBTStatus 7 "Reserved" 6 "Reserved" 5 "Deleted" 4 "Disconnected" 3 "Connected" 2 "Paired" 1 "Searching" 0 "No BT connection" ;
VAL_ 713 HuIcRepeatOneState 1 "Repeat One ON" 0 "Repeat One OFF" ;
VAL_ 713 HuIcMuteStatus 1 "Mute" 0 "UnMute" ;
VAL_ 713 HuIcSMSReceiveState 1 "SMS received" 0 "No SMS" ;
VAL_ 713 HuIcRepeatState 1 "Repeat ON" 0 "Repeat OFF" ;
VAL_ 713 HuIcPhoneCallStatus 7 "Reserved" 6 "Call ended" 5 "Hold" 4 "Active Conference Call" 3 "Active Call" 2 "Outgoing Call" 1 "Incoming Call" 0 "No Phone Call" ;
VAL_ 713 HuIcNetworkSignalStatus 7 "Level 7" 6 "Level 6" 5 "Level 5" 4 "Level 4" 3 "Level 3" 2 "Level 2" 1 "Level 1" 0 "Level 0" ;
VAL_ 713 HuIcInfoFeaturePresence 1 "Present" 0 "Not Present" ;
VAL_ 713 HuIcShuffleState 1 "Shuffle ON" 0 "Shuffle OFF" ;
VAL_ 714 TrailerPositionLmpMalFn 1 "Trailer Position lamp Malfunction" 0 "Trailer Position lamp Normal" ;
VAL_ 714 TrailerRevLmpMalFn 1 "Trailer Reverse lamp Malfunction" 0 "Trailer Reverse lamp Normal" ;
VAL_ 714 TrailerBrkLmpMalFnStatus 3 "Signal not available" 2 "Reserved" 1 "Reserved" 0 "Value is plausible" ;
VAL_ 714 TrailerBrkLmpMalFn 1 "Trailer Brake lamp Malfunction" 0 "Trailer Brake lamp Normal" ;
VAL_ 714 TrailerPresenceStatus 3 "Signal not available" 2 "Reserved" 1 "Reserved" 0 "Value is plausible" ;
VAL_ 714 TrailerPresence 1 "Trailer is Present" 0 "Trailer is not present" ;
VAL_ 714 TrailerTurnLhMalFn 1 "Trailer Turn left indicator light Malfunction" 0 "Trailer Turn left indicator light Normal" ;
VAL_ 714 TrailerFogMalFnStatus 3 "Signal not available" 2 "Reserved" 1 "Reserved" 0 "Value is plausible" ;
VAL_ 714 TrailerFogMalFn 1 "Trailer Fog lamp Malfunction" 0 "Trailer Fog lamp Normal" ;
VAL_ 714 TrailerPositionLmpMalFnStatus 3 "Signal not available" 2 "Reserved" 1 "Reserved" 0 "Value is plausible" ;
VAL_ 714 TrailerRevLmpMalFnStatus 3 "Signal not available" 2 "Reserved" 1 "Reserved" 0 "Value is plausible" ;
VAL_ 714 TrailerTurnRhMalFnStatus 3 "Signal not available" 2 "Reserved" 1 "Reserved" 0 "Value is plausible" ;
VAL_ 714 TrailerTurnRhMalFn 1 "Trailer Turn right indicator light Malfunction" 0 "Trailer Turn right indicator light Normal" ;
VAL_ 714 TrailerTurnLhMalFnStatus 3 "Signal not available" 2 "Reserved" 1 "Reserved" 0 "Value is plausible" ;
VAL_ 715 RemoteAcStatus 3 "Signal not available" 2 "Implausible" 1 "Reserved for future use" 0 "Plausible and signal is correct" ;
VAL_ 715 RemoteAcState 1 "Remote AC ON" 0 "Remote AC OFF" ;
VAL_ 715 CcmEmsIACReqSts 1 "Reserved for future use" 0 "Value is plausible" 3 "Reserved for future use" 2 "Value is implausible" ;
VAL_ 715 CcmEmsIACReq 1 "Alternator not to be Switch OFF" 0 "Alternator to be Switch OFF" 3 "Reserved for future use" 2 "Reserved for future use" ;
VAL_ 715 AcReq 1 "AC request from driver activated" 0 "AC Request from driver deactivated" ;
VAL_ 715 HRwReqFrmCCmStatus 3 "Signal not available" 2 "Value is implausibe" 1 "Reserved" 0 "Value is plausible" ;
VAL_ 715 CCmVariantType 3 "Reserved" 2 "ETC available" 1 "FATC dual zone available" 0 "FATC single zone available" ;
VAL_ 715 CCmPresence 1 "Reserved" 0 "Present" ;
VAL_ 715 VehicleInteriorTempStatus 3 "Reserved" 2 "Value is implausibe" 1 "Reserved" 0 "Value is plausible" ;
VAL_ 715 HRwReqFrmCCm 1 "Heated rear window is requested from Climate Control Module." 0 "Heated rear window is NOT requested from Climate Control Module." ;
VAL_ 715 CcmEmsEngStopStartReq 3 "Reserved" 2 "Reserved" 1 "Stop/Start permitted (Cabin comfort is acceptable)" 0 "Stop/Start not permitted (Cabin needs further conditioning)" ;
VAL_ 715 CcmEmsEngStopStartReqSts 3 "Reserved for future use" 2 "Implausible" 1 "Reserved for future use" 0 "Plausible and signal is correct" ;
VAL_ 715 EVAPSigStatus 3 "Signal Not Available" 2 "Implausible" 1 "Reserved" 0 "Plausible" ;
VAL_ 720 RearWasherStateStatus 3 "Signal Not Available(SNA)" 2 "Implausible" 1 "Reserved" 0 "Plausible" ;
VAL_ 720 RearWasherState 3 "Reserved for future use" 2 "Reserved for future use" 1 "Rear Washer Activated" 0 "Rear Washer Deactivated" ;
VAL_ 720 FrontWasherStateStatus 3 "Signal Not Available(SNA)" 2 "Implausible" 1 "Reserved" 0 "Plausible" ;
VAL_ 720 FrontWasherState 3 "Reserved for future use" 2 "Reserved for future use" 1 "Front Washer Activated" 0 "Front Washer Deactivated" ;
VAL_ 720 AutoWipeStateStatus 3 "Reserved for future use" 2 "Reserved for future use" 1 "signal AutoWipeState Not Available" 0 "Plausible  - Information given by AutoWipeState is correct and according to specification" ;
VAL_ 720 AutoWipeState 3 "Reserved for future use" 2 "Reserved for future use" 1 "Wiper sensor is activated" 0 "No activation of wiper sensor" ;
VAL_ 720 PositionLmpTelltale 1 "Position Lamp ON" 0 "Position Lamp OFF" ;
VAL_ 720 PositionLmpTelltaleStatus 3 "Signal not available" 2 "signal is implausible" 1 "Reserved" 0 "Value is plausible" ;
VAL_ 720 BCMVariant 7 "Reserved" 6 "Reserved" 5 "Reserved" 4 "Reserved" 3 "Reserved" 2 "BCM variant is Mid Gateway" 1 "BCM variant is Mid" 0 "BCM variant is Base" ;
VAL_ 720 BCMPresence 1 "Reserved" 0 "BCM is present" ;
VAL_ 720 RevGearStatus 3 "Signal not available" 2 "Reserved" 1 "Reserved" 0 "Value is pluasible" ;
VAL_ 720 RevGear 1 "Reverse gear engaged" 0 "Reverse gear disengaged" ;
VAL_ 720 RevLmpON 1 "Reverse Lamp is ON" 0 "Reverse Lamp is OFF" ;
VAL_ 720 RevLmpONStatus 3 "Signal not available" 2 "Reserved" 1 "Reserved" 0 "Value is plausible" ;
VAL_ 720 RearFogLmpON 1 "Rear Fog Lamp is ON" 0 "Rear Fog Lamp is OFF" ;
VAL_ 720 RearFogLmpONStatus 3 "Signal not available" 2 "Reserved" 1 "Reserved" 0 "Value is plausible" ;
VAL_ 720 TurnLHTelltaleStatus 3 "Signal not available" 2 "Reserved" 1 "Reserved" 0 "Value is plausible" ;
VAL_ 720 TurnLHTelltale 1 "LH Turn Indicator ON" 0 "LH Turn Indicator OFF" ;
VAL_ 720 TurnRHTelltaleStatus 3 "Signal not available" 2 "Reserved" 1 "Reserved" 0 "Value is plausible" ;
VAL_ 720 TurnRHTelltale 1 "RH Turn  Indicator ON" 0 "RH Turn  Indicator OFF" ;
VAL_ 720 LightSensActiveStatus 3 "Signal not available" 2 "Reserved" 1 "Reserved" 0 "Value is plausible" ;
VAL_ 720 LightSensActive 1 "Light sensor is activated" 0 "No activation of light sensor" ;
VAL_ 720 RVcPresence 3 "Ficosa Camera" 2 "Bosch Camera" 1 "Not Present" 0 "RVC Auto learning not available" ;
VAL_ 722 PowerModeStateStatus 3 "Signal not avialable" 2 "Reserved" 1 "Reserved" 0 "Value is plausible" ;
VAL_ 722 PowerModeState 15 "Reserved" 14 "Reserved" 13 "Reserved" 12 "Reserved" 11 "Transport Drive Run" 10 "Transport Drive Crank" 9 "Start(Crank)" 8 "Run(Engine Run)" 7 "Transport Drive" 6 "Active(Ignition ON)" 5 "Accessory Delay" 4 "Accessory" 3 "KeyIn" 2 "Transport Park" 1 "Awake" 0 "Pre Stand By" ;
VAL_ 722 PositionLmpTelltaleStatus 2 "signal is implausible" 1 "Reserved" 0 "Value is plausible" 3 "Signal not available" ;
VAL_ 722 PositionLmpTelltale 0 "Position Lamp OFF" 1 "Position Lamp ON" ;
VAL_ 722 HRwFdBkFrmBCm 1 "Heated Rear Window is ON" 0 "Heated Rear Window is OFF" ;
VAL_ 722 HRwFdBkFrmBCmStatus 3 "Signal not available" 2 "Reserved" 1 "Reserved " 0 "Value is plausible" ;
VAL_ 722 TurnRHTelltale 1 "RH Turn  Indicator ON" 0 "RH Turn  Indicator OFF" ;
VAL_ 722 TurnLHTelltaleStatus 3 "Signal not available" 2 "Reserved" 1 "Reserved" 0 "Value is plausible" ;
VAL_ 722 TurnLHTelltale 1 "LH Turn Indicator ON" 0 "LH Turn Indicator OFF" ;
VAL_ 722 TurnRHTelltaleStatus 3 "Signal not available" 2 "Reserved" 1 "Reserved" 0 "Value is plausible" ;
VAL_ 722 BattSaverFnONStatus 3 "Signal not avialable" 2 "Reserved" 1 "Reserved" 0 "Value is plausible" ;
VAL_ 722 BattSaverFnON 1 "BattSaver Active" 0 "BattSaver Inactive" ;
VAL_ 722 BrkLmpONStatus 3 "Signal not available" 2 "Reserved" 1 "Reserved" 0 "Value is plausible" ;
VAL_ 722 BrkLmpON 1 "Brake Lamp is ON" 0 "Brake Lamp is OFF" ;
VAL_ 722 CockpitSigECuStatus 3 "Signal CockpitSigECu Not Available" 2 "Implausible - Information given at CockpitSigECu signal value is implausible." 1 "Reserved for future use." 0 "Plausible  - Information given by CockpitSigECu is correct and according to specification  " ;
VAL_ 722 RearRHTurnLmpON 1 "Rear RH Turn Lamp ON" 0 "Rear RH Turn Lamp OFF" ;
VAL_ 722 RearRHTurnLmpONStatus 3 "Signal not available" 2 "Reserved" 1 "Reserved" 0 "Value is plausible" ;
VAL_ 722 RearLHTurnLmpONStatus 3 "Signal not available" 2 "Reserved" 1 "Reserved" 0 "Value is plausible" ;
VAL_ 722 RearLHTurnLmpON 1 "Rear LH Turn Lamp ON" 0 "Rear LH Turn Lamp OFF" ;
VAL_ 722 VehicleLockStateStatus 3 "Signal is not available" 2 "Signal is implausible" 1 "Reserved" 0 "Signal is plausible" ;
VAL_ 722 HighBeamTelltaleStatus 3 "Signal not available" 2 "Reserved" 1 "Reserved" 0 "Value is plausible" ;
VAL_ 722 HighBeamTelltale 1 "High Beam ON" 0 "High Beam OFF" ;
VAL_ 722 KeyInStateStatus 3 "Signal not available" 2 "Reserved" 1 "Reserved" 0 "Value is plausible" ;
VAL_ 722 KeyInState 1 "Key In" 0 "Key Out" ;
VAL_ 722 VehicleLockState 7 "TCU Unlocked " 6 "TCU Locked " 5 "Reverse Unlock" 4 "Crash Unlocked" 3 "Unlocked" 2 "Internally Locked" 1 "Externally Locked" 0 "Reserved for future use" ;
VAL_ 729 VehicleMobilizationStateStatus 3 "Signal  Not Available" 2 "Signal is Implausible" 1 "Reserved for future use" 0 "Plausible-Information is correct" ;
VAL_ 729 VehicleMobilizationState 3 "Reserved for future use" 2 "Immobilised by TCU" 1 "Mobilised by TCU" 0 "Reserved for future use" ;
VAL_ 729 KeySearchStatusPEPS 1 "Key search is active" 0 "Key search is not active" ;
VAL_ 729 PEPsClampState 7 "Reserved" 6 "Reserved" 5 "Reserved" 4 "CRANK ON" 3 "IGN ON" 2 "ACC ON" 1 "OFF" 0 "RESERVED" ;
VAL_ 729 PEPsClampStateStatus 3 "Signal not available" 2 "Value is implausibe" 1 "Reserved" 0 "Value is plausible" ;
VAL_ 729 ESClLockInhibitPEPS 1 "ESCL Locking prohibited" 0 "ESCL Locking allowed" ;
VAL_ 729 PEPsPresence 1 "Reserved" 0 "PEPS is present" ;
VAL_ 729 PEPsKeyInState 1 "Key Is Inside The Vehicle" 0 "Key Is Not Inside The Vehicle" ;
VAL_ 729 PEPsVehLockCmd 1 "Execute Lock" 0 "No Lock" ;
VAL_ 729 PEPsVehLockCmdStatus 3 "Signal PEPsVehLockCmd Not Available" 2 "Reserved" 1 "Reserved" 0 "Plausible  - Information given by PEPsVehLockCmd is correct and according to specification" ;
